VERSION ""

NS_ :

BS_:

BU_: R_BPCU_BCU JiaShiCang L_BPCU_BCU EMPC_ECU

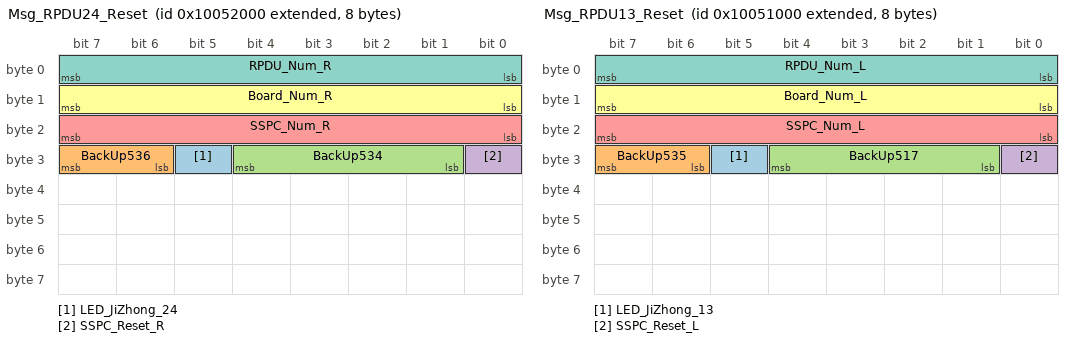
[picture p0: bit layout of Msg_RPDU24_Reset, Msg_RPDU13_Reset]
BO_ 2416254976 Msg_RPDU24_Reset: 8 JiaShiCang
 SG_ LED_JiZhong_24 : 29|1@1+ (1,0) [0|1] "" Vector__XXX
 SG_ BackUp536 : 30|2@1+ (1,0) [0|0] "" Vector__XXX
 SG_ BackUp534 : 25|4@1+ (1,0) [0|0] ""  R_BPCU_BCU
 SG_ SSPC_Reset_R : 24|1@1+ (1,0) [0|1] ""  R_BPCU_BCU
 SG_ SSPC_Num_R : 16|8@1+ (1,0) [1|18] ""  R_BPCU_BCU
 SG_ Board_Num_R : 8|8@1+ (1,0) [1|6] ""  R_BPCU_BCU
 SG_ RPDU_Num_R : 0|8@1+ (1,0) [1|4] ""  R_BPCU_BCU

BO_ 2416189440 Msg_RPDU4_Order2: 8 JiaShiCang
 SG_ BackUp533 : 56|8@1+ (1,0) [0|0] ""  R_BPCU_BCU
 SG_ BackUp532 : 55|1@1+ (1,0) [0|0] ""  R_BPCU_BCU
 SG_ RPDU4_B6_SSPC_Order_07 : 54|1@1+ (1,0) [0|1] ""  R_BPCU_BCU
 SG_ RPDU4_B6_SSPC_Order_06 : 53|1@1+ (1,0) [0|1] ""  R_BPCU_BCU
 SG_ RPDU4_B6_SSPC_Order_05 : 52|1@1+ (1,0) [0|1] ""  R_BPCU_BCU
 SG_ RPDU4_B6_SSPC_Order_04 : 51|1@1+ (1,0) [0|1] ""  R_BPCU_BCU
 SG_ RPDU4_B6_SSPC_Order_03 : 50|1@1+ (1,0) [0|1] ""  R_BPCU_BCU
 SG_ RPDU4_B6_SSPC_Order_02 : 49|1@1+ (1,0) [0|1] ""  R_BPCU_BCU
 SG_ RPDU4_B6_SSPC_Order_01 : 48|1@1+ (1,0) [0|1] ""  R_BPCU_BCU
 SG_ BackUp531 : 42|6@1+ (1,0) [0|0] ""  R_BPCU_BCU
 SG_ RPDU4_B4_SSPC_Order_18 : 41|1@1+ (1,0) [0|1] ""  R_BPCU_BCU
 SG_ RPDU4_B4_SSPC_Order_17 : 40|1@1+ (1,0) [0|1] ""  R_BPCU_BCU
 SG_ RPDU4_B4_SSPC_Order_16 : 39|1@1+ (1,0) [0|1] ""  R_BPCU_BCU
 SG_ RPDU4_B4_SSPC_Order_15 : 38|1@1+ (1,0) [0|1] ""  R_BPCU_BCU
 SG_ RPDU4_B4_SSPC_Order_14 : 37|1@1+ (1,0) [0|1] ""  R_BPCU_BCU
 SG_ RPDU4_B4_SSPC_Order_13 : 36|1@1+ (1,0) [0|1] ""  R_BPCU_BCU
 SG_ RPDU4_B4_SSPC_Order_12 : 35|1@1+ (1,0) [0|1] ""  R_BPCU_BCU
 SG_ RPDU4_B4_SSPC_Order_11 : 34|1@1+ (1,0) [0|1] ""  R_BPCU_BCU
 SG_ RPDU4_B4_SSPC_Order_10 : 33|1@1+ (1,0) [0|1] ""  R_BPCU_BCU
 SG_ RPDU4_B4_SSPC_Order_09 : 32|1@1+ (1,0) [0|1] ""  R_BPCU_BCU
 SG_ RPDU4_B4_SSPC_Order_08 : 31|1@1+ (1,0) [0|1] ""  R_BPCU_BCU
 SG_ RPDU4_B4_SSPC_Order_07 : 30|1@1+ (1,0) [0|1] ""  R_BPCU_BCU
 SG_ RPDU4_B4_SSPC_Order_06 : 29|1@1+ (1,0) [0|1] ""  R_BPCU_BCU
 SG_ RPDU4_B4_SSPC_Order_05 : 28|1@1+ (1,0) [0|1] ""  R_BPCU_BCU
 SG_ RPDU4_B4_SSPC_Order_04 : 27|1@1+ (1,0) [0|1] ""  R_BPCU_BCU
 SG_ RPDU4_B4_SSPC_Order_03 : 26|1@1+ (1,0) [0|1] ""  R_BPCU_BCU
 SG_ RPDU4_B4_SSPC_Order_02 : 25|1@1+ (1,0) [0|1] ""  R_BPCU_BCU
 SG_ RPDU4_B4_SSPC_Order_01 : 24|1@1+ (1,0) [0|1] ""  R_BPCU_BCU
 SG_ BackUp530 : 18|6@1+ (1,0) [0|0] ""  R_BPCU_BCU
 SG_ RPDU4_B2_SSPC_Order_18 : 17|1@1+ (1,0) [0|1] ""  R_BPCU_BCU
 SG_ RPDU4_B2_SSPC_Order_17 : 16|1@1+ (1,0) [0|1] ""  R_BPCU_BCU
 SG_ RPDU4_B2_SSPC_Order_16 : 15|1@1+ (1,0) [0|1] ""  R_BPCU_BCU
 SG_ RPDU4_B2_SSPC_Order_15 : 14|1@1+ (1,0) [0|1] ""  R_BPCU_BCU
 SG_ RPDU4_B2_SSPC_Order_14 : 13|1@1+ (1,0) [0|1] ""  R_BPCU_BCU
 SG_ RPDU4_B2_SSPC_Order_13 : 12|1@1+ (1,0) [0|1] ""  R_BPCU_BCU
 SG_ RPDU4_B2_SSPC_Order_12 : 11|1@1+ (1,0) [0|1] ""  R_BPCU_BCU
 SG_ RPDU4_B2_SSPC_Order_11 : 10|1@1+ (1,0) [0|1] ""  R_BPCU_BCU
 SG_ RPDU4_B2_SSPC_Order_10 : 9|1@1+ (1,0) [0|1] ""  R_BPCU_BCU
 SG_ RPDU4_B2_SSPC_Order_09 : 8|1@1+ (1,0) [0|1] ""  R_BPCU_BCU
 SG_ RPDU4_B2_SSPC_Order_08 : 7|1@1+ (1,0) [0|1] ""  R_BPCU_BCU
 SG_ RPDU4_B2_SSPC_Order_07 : 6|1@1+ (1,0) [0|1] ""  R_BPCU_BCU
 SG_ RPDU4_B2_SSPC_Order_06 : 5|1@1+ (1,0) [0|1] ""  R_BPCU_BCU
 SG_ RPDU4_B2_SSPC_Order_05 : 4|1@1+ (1,0) [0|1] ""  R_BPCU_BCU
 SG_ RPDU4_B2_SSPC_Order_04 : 3|1@1+ (1,0) [0|1] ""  R_BPCU_BCU
 SG_ RPDU4_B2_SSPC_Order_03 : 2|1@1+ (1,0) [0|1] ""  R_BPCU_BCU
 SG_ RPDU4_B2_SSPC_Order_02 : 1|1@1+ (1,0) [0|1] ""  R_BPCU_BCU
 SG_ RPDU4_B2_SSPC_Order_01 : 0|1@1+ (1,0) [0|1] ""  R_BPCU_BCU

BO_ 2416123904 Msg_RPDU4_Order1: 8 JiaShiCang
 SG_ BackUp529 : 56|8@1+ (1,0) [0|0] ""  R_BPCU_BCU
 SG_ BackUp528 : 55|1@1+ (1,0) [0|0] ""  R_BPCU_BCU
 SG_ RPDU4_B5_SSPC_Order_07 : 54|1@1+ (1,0) [0|1] ""  R_BPCU_BCU
 SG_ RPDU4_B5_SSPC_Order_06 : 53|1@1+ (1,0) [0|1] ""  R_BPCU_BCU
 SG_ RPDU4_B5_SSPC_Order_05 : 52|1@1+ (1,0) [0|1] ""  R_BPCU_BCU
 SG_ RPDU4_B5_SSPC_Order_04 : 51|1@1+ (1,0) [0|1] ""  R_BPCU_BCU
 SG_ RPDU4_B5_SSPC_Order_03 : 50|1@1+ (1,0) [0|1] ""  R_BPCU_BCU
 SG_ RPDU4_B5_SSPC_Order_02 : 49|1@1+ (1,0) [0|1] ""  R_BPCU_BCU
 SG_ RPDU4_B5_SSPC_Order_01 : 48|1@1+ (1,0) [0|1] ""  R_BPCU_BCU
 SG_ BackUp527 : 42|6@1+ (1,0) [0|0] ""  R_BPCU_BCU
 SG_ RPDU4_B3_SSPC_Order_18 : 41|1@1+ (1,0) [0|1] ""  R_BPCU_BCU
 SG_ RPDU4_B3_SSPC_Order_17 : 40|1@1+ (1,0) [0|1] ""  R_BPCU_BCU
 SG_ RPDU4_B3_SSPC_Order_16 : 39|1@1+ (1,0) [0|1] ""  R_BPCU_BCU
 SG_ RPDU4_B3_SSPC_Order_15 : 38|1@1+ (1,0) [0|1] ""  R_BPCU_BCU
 SG_ RPDU4_B3_SSPC_Order_14 : 37|1@1+ (1,0) [0|1] ""  R_BPCU_BCU
 SG_ RPDU4_B3_SSPC_Order_13 : 36|1@1+ (1,0) [0|1] ""  R_BPCU_BCU
 SG_ RPDU4_B3_SSPC_Order_12 : 35|1@1+ (1,0) [0|1] ""  R_BPCU_BCU
 SG_ RPDU4_B3_SSPC_Order_11 : 34|1@1+ (1,0) [0|1] ""  R_BPCU_BCU
 SG_ RPDU4_B3_SSPC_Order_10 : 33|1@1+ (1,0) [0|1] ""  R_BPCU_BCU
 SG_ RPDU4_B3_SSPC_Order_09 : 32|1@1+ (1,0) [0|1] ""  R_BPCU_BCU
 SG_ RPDU4_B3_SSPC_Order_08 : 31|1@1+ (1,0) [0|1] ""  R_BPCU_BCU
 SG_ RPDU4_B3_SSPC_Order_07 : 30|1@1+ (1,0) [0|1] ""  R_BPCU_BCU
 SG_ RPDU4_B3_SSPC_Order_06 : 29|1@1+ (1,0) [0|1] ""  R_BPCU_BCU
 SG_ RPDU4_B3_SSPC_Order_05 : 28|1@1+ (1,0) [0|1] ""  R_BPCU_BCU
 SG_ RPDU4_B3_SSPC_Order_04 : 27|1@1+ (1,0) [0|1] ""  R_BPCU_BCU
 SG_ RPDU4_B3_SSPC_Order_03 : 26|1@1+ (1,0) [0|1] ""  R_BPCU_BCU
 SG_ RPDU4_B3_SSPC_Order_02 : 25|1@1+ (1,0) [0|1] ""  R_BPCU_BCU
 SG_ RPDU4_B3_SSPC_Order_01 : 24|1@1+ (1,0) [0|1] ""  R_BPCU_BCU
 SG_ BackUp526 : 18|6@1+ (1,0) [0|0] ""  R_BPCU_BCU
 SG_ RPDU4_B1_SSPC_Order_18 : 17|1@1+ (1,0) [0|1] ""  R_BPCU_BCU
 SG_ RPDU4_B1_SSPC_Order_17 : 16|1@1+ (1,0) [0|1] ""  R_BPCU_BCU
 SG_ RPDU4_B1_SSPC_Order_16 : 15|1@1+ (1,0) [0|1] ""  R_BPCU_BCU
 SG_ RPDU4_B1_SSPC_Order_15 : 14|1@1+ (1,0) [0|1] ""  R_BPCU_BCU
 SG_ RPDU4_B1_SSPC_Order_14 : 13|1@1+ (1,0) [0|1] ""  R_BPCU_BCU
 SG_ RPDU4_B1_SSPC_Order_13 : 12|1@1+ (1,0) [0|1] ""  R_BPCU_BCU
 SG_ RPDU4_B1_SSPC_Order_12 : 11|1@1+ (1,0) [0|1] ""  R_BPCU_BCU
 SG_ RPDU4_B1_SSPC_Order_11 : 10|1@1+ (1,0) [0|1] ""  R_BPCU_BCU
 SG_ RPDU4_B1_SSPC_Order_10 : 9|1@1+ (1,0) [0|1] ""  R_BPCU_BCU
 SG_ RPDU4_B1_SSPC_Order_09 : 8|1@1+ (1,0) [0|1] ""  R_BPCU_BCU
 SG_ RPDU4_B1_SSPC_Order_08 : 7|1@1+ (1,0) [0|1] ""  R_BPCU_BCU
 SG_ RPDU4_B1_SSPC_Order_07 : 6|1@1+ (1,0) [0|1] ""  R_BPCU_BCU
 SG_ RPDU4_B1_SSPC_Order_06 : 5|1@1+ (1,0) [0|1] ""  R_BPCU_BCU
 SG_ RPDU4_B1_SSPC_Order_05 : 4|1@1+ (1,0) [0|1] ""  R_BPCU_BCU
 SG_ RPDU4_B1_SSPC_Order_04 : 3|1@1+ (1,0) [0|1] ""  R_BPCU_BCU
 SG_ RPDU4_B1_SSPC_Order_03 : 2|1@1+ (1,0) [0|1] ""  R_BPCU_BCU
 SG_ RPDU4_B1_SSPC_Order_02 : 1|1@1+ (1,0) [0|1] ""  R_BPCU_BCU
 SG_ RPDU4_B1_SSPC_Order_01 : 0|1@1+ (1,0) [0|1] ""  R_BPCU_BCU

BO_ 2416058368 Msg_RPDU2_Order2: 8 JiaShiCang
 SG_ BackUp525 : 56|8@1+ (1,0) [0|0] ""  R_BPCU_BCU
 SG_ BackUp524 : 55|1@1+ (1,0) [0|0] ""  R_BPCU_BCU
 SG_ RPDU2_B6_SSPC_Order_07 : 54|1@1+ (1,0) [0|1] ""  R_BPCU_BCU
 SG_ RPDU2_B6_SSPC_Order_06 : 53|1@1+ (1,0) [0|1] ""  R_BPCU_BCU
 SG_ RPDU2_B6_SSPC_Order_05 : 52|1@1+ (1,0) [0|1] ""  R_BPCU_BCU
 SG_ RPDU2_B6_SSPC_Order_04 : 51|1@1+ (1,0) [0|1] ""  R_BPCU_BCU
 SG_ RPDU2_B6_SSPC_Order_03 : 50|1@1+ (1,0) [0|1] ""  R_BPCU_BCU
 SG_ RPDU2_B6_SSPC_Order_02 : 49|1@1+ (1,0) [0|1] ""  R_BPCU_BCU
 SG_ RPDU2_B6_SSPC_Order_01 : 48|1@1+ (1,0) [0|1] ""  R_BPCU_BCU
 SG_ BackUp523 : 42|6@1+ (1,0) [0|0] ""  R_BPCU_BCU
 SG_ RPDU2_B4_SSPC_Order_18 : 41|1@1+ (1,0) [0|1] ""  R_BPCU_BCU
 SG_ RPDU2_B4_SSPC_Order_17 : 40|1@1+ (1,0) [0|1] ""  R_BPCU_BCU
 SG_ RPDU2_B4_SSPC_Order_16 : 39|1@1+ (1,0) [0|1] ""  R_BPCU_BCU
 SG_ RPDU2_B4_SSPC_Order_15 : 38|1@1+ (1,0) [0|1] ""  R_BPCU_BCU
 SG_ RPDU2_B4_SSPC_Order_14 : 37|1@1+ (1,0) [0|1] ""  R_BPCU_BCU
 SG_ RPDU2_B4_SSPC_Order_13 : 36|1@1+ (1,0) [0|1] ""  R_BPCU_BCU
 SG_ RPDU2_B4_SSPC_Order_12 : 35|1@1+ (1,0) [0|1] ""  R_BPCU_BCU
 SG_ RPDU2_B4_SSPC_Order_11 : 34|1@1+ (1,0) [0|1] ""  R_BPCU_BCU
 SG_ RPDU2_B4_SSPC_Order_10 : 33|1@1+ (1,0) [0|1] ""  R_BPCU_BCU
 SG_ RPDU2_B4_SSPC_Order_09 : 32|1@1+ (1,0) [0|1] ""  R_BPCU_BCU
 SG_ RPDU2_B4_SSPC_Order_08 : 31|1@1+ (1,0) [0|1] ""  R_BPCU_BCU
 SG_ RPDU2_B4_SSPC_Order_07 : 30|1@1+ (1,0) [0|1] ""  R_BPCU_BCU
 SG_ RPDU2_B4_SSPC_Order_06 : 29|1@1+ (1,0) [0|1] ""  R_BPCU_BCU
 SG_ RPDU2_B4_SSPC_Order_05 : 28|1@1+ (1,0) [0|1] ""  R_BPCU_BCU
 SG_ RPDU2_B4_SSPC_Order_04 : 27|1@1+ (1,0) [0|1] ""  R_BPCU_BCU
 SG_ RPDU2_B4_SSPC_Order_03 : 26|1@1+ (1,0) [0|1] ""  R_BPCU_BCU
 SG_ RPDU2_B4_SSPC_Order_02 : 25|1@1+ (1,0) [0|1] ""  R_BPCU_BCU
 SG_ RPDU2_B4_SSPC_Order_01 : 24|1@1+ (1,0) [0|1] ""  R_BPCU_BCU
 SG_ BackUp522 : 18|6@1+ (1,0) [0|0] ""  R_BPCU_BCU
 SG_ RPDU2_B2_SSPC_Order_18 : 17|1@1+ (1,0) [0|1] ""  R_BPCU_BCU
 SG_ RPDU2_B2_SSPC_Order_17 : 16|1@1+ (1,0) [0|1] ""  R_BPCU_BCU
 SG_ RPDU2_B2_SSPC_Order_16 : 15|1@1+ (1,0) [0|1] ""  R_BPCU_BCU
 SG_ RPDU2_B2_SSPC_Order_15 : 14|1@1+ (1,0) [0|1] ""  R_BPCU_BCU
 SG_ RPDU2_B2_SSPC_Order_14 : 13|1@1+ (1,0) [0|1] ""  R_BPCU_BCU
 SG_ RPDU2_B2_SSPC_Order_13 : 12|1@1+ (1,0) [0|1] ""  R_BPCU_BCU
 SG_ RPDU2_B2_SSPC_Order_12 : 11|1@1+ (1,0) [0|1] ""  R_BPCU_BCU
 SG_ RPDU2_B2_SSPC_Order_11 : 10|1@1+ (1,0) [0|1] ""  R_BPCU_BCU
 SG_ RPDU2_B2_SSPC_Order_10 : 9|1@1+ (1,0) [0|1] ""  R_BPCU_BCU
 SG_ RPDU2_B2_SSPC_Order_09 : 8|1@1+ (1,0) [0|1] ""  R_BPCU_BCU
 SG_ RPDU2_B2_SSPC_Order_08 : 7|1@1+ (1,0) [0|1] ""  R_BPCU_BCU
 SG_ RPDU2_B2_SSPC_Order_07 : 6|1@1+ (1,0) [0|1] ""  R_BPCU_BCU
 SG_ RPDU2_B2_SSPC_Order_06 : 5|1@1+ (1,0) [0|1] ""  R_BPCU_BCU
 SG_ RPDU2_B2_SSPC_Order_05 : 4|1@1+ (1,0) [0|1] ""  R_BPCU_BCU
 SG_ RPDU2_B2_SSPC_Order_04 : 3|1@1+ (1,0) [0|1] ""  R_BPCU_BCU
 SG_ RPDU2_B2_SSPC_Order_03 : 2|1@1+ (1,0) [0|1] ""  R_BPCU_BCU
 SG_ RPDU2_B2_SSPC_Order_02 : 1|1@1+ (1,0) [0|1] ""  R_BPCU_BCU
 SG_ RPDU2_B2_SSPC_Order_01 : 0|1@1+ (1,0) [0|1] ""  R_BPCU_BCU

BO_ 2415992832 Msg_RPDU2_Order1: 8 JiaShiCang
 SG_ BackUp521 : 56|8@1+ (1,0) [0|0] ""  R_BPCU_BCU
 SG_ BackUp520 : 55|1@1+ (1,0) [0|0] ""  R_BPCU_BCU
 SG_ RPDU2_B5_SSPC_Order_07 : 54|1@1+ (1,0) [0|1] ""  R_BPCU_BCU
 SG_ RPDU2_B5_SSPC_Order_06 : 53|1@1+ (1,0) [0|1] ""  R_BPCU_BCU
 SG_ RPDU2_B5_SSPC_Order_05 : 52|1@1+ (1,0) [0|1] ""  R_BPCU_BCU
 SG_ RPDU2_B5_SSPC_Order_04 : 51|1@1+ (1,0) [0|1] ""  R_BPCU_BCU
 SG_ RPDU2_B5_SSPC_Order_03 : 50|1@1+ (1,0) [0|1] ""  R_BPCU_BCU
 SG_ RPDU2_B5_SSPC_Order_02 : 49|1@1+ (1,0) [0|1] ""  R_BPCU_BCU
 SG_ RPDU2_B5_SSPC_Order_01 : 48|1@1+ (1,0) [0|1] ""  R_BPCU_BCU
 SG_ BackUp519 : 42|6@1+ (1,0) [0|0] ""  R_BPCU_BCU
 SG_ RPDU2_B3_SSPC_Order_18 : 41|1@1+ (1,0) [0|1] ""  R_BPCU_BCU
 SG_ RPDU2_B3_SSPC_Order_17 : 40|1@1+ (1,0) [0|1] ""  R_BPCU_BCU
 SG_ RPDU2_B3_SSPC_Order_16 : 39|1@1+ (1,0) [0|1] ""  R_BPCU_BCU
 SG_ RPDU2_B3_SSPC_Order_15 : 38|1@1+ (1,0) [0|1] ""  R_BPCU_BCU
 SG_ RPDU2_B3_SSPC_Order_14 : 37|1@1+ (1,0) [0|1] ""  R_BPCU_BCU
 SG_ RPDU2_B3_SSPC_Order_13 : 36|1@1+ (1,0) [0|1] ""  R_BPCU_BCU
 SG_ RPDU2_B3_SSPC_Order_12 : 35|1@1+ (1,0) [0|1] ""  R_BPCU_BCU
 SG_ RPDU2_B3_SSPC_Order_11 : 34|1@1+ (1,0) [0|1] ""  R_BPCU_BCU
 SG_ RPDU2_B3_SSPC_Order_10 : 33|1@1+ (1,0) [0|1] ""  R_BPCU_BCU
 SG_ RPDU2_B3_SSPC_Order_09 : 32|1@1+ (1,0) [0|1] ""  R_BPCU_BCU
 SG_ RPDU2_B3_SSPC_Order_08 : 31|1@1+ (1,0) [0|1] ""  R_BPCU_BCU
 SG_ RPDU2_B3_SSPC_Order_07 : 30|1@1+ (1,0) [0|1] ""  R_BPCU_BCU
 SG_ RPDU2_B3_SSPC_Order_06 : 29|1@1+ (1,0) [0|1] ""  R_BPCU_BCU
 SG_ RPDU2_B3_SSPC_Order_05 : 28|1@1+ (1,0) [0|1] ""  R_BPCU_BCU
 SG_ RPDU2_B3_SSPC_Order_04 : 27|1@1+ (1,0) [0|1] ""  R_BPCU_BCU
 SG_ RPDU2_B3_SSPC_Order_03 : 26|1@1+ (1,0) [0|1] ""  R_BPCU_BCU
 SG_ RPDU2_B3_SSPC_Order_02 : 25|1@1+ (1,0) [0|1] ""  R_BPCU_BCU
 SG_ RPDU2_B3_SSPC_Order_01 : 24|1@1+ (1,0) [0|1] ""  R_BPCU_BCU
 SG_ BackUp518 : 18|6@1+ (1,0) [0|0] ""  R_BPCU_BCU
 SG_ RPDU2_B1_SSPC_Order_18 : 17|1@1+ (1,0) [0|1] ""  R_BPCU_BCU
 SG_ RPDU2_B1_SSPC_Order_17 : 16|1@1+ (1,0) [0|1] ""  R_BPCU_BCU
 SG_ RPDU2_B1_SSPC_Order_16 : 15|1@1+ (1,0) [0|1] ""  R_BPCU_BCU
 SG_ RPDU2_B1_SSPC_Order_15 : 14|1@1+ (1,0) [0|1] ""  R_BPCU_BCU
 SG_ RPDU2_B1_SSPC_Order_14 : 13|1@1+ (1,0) [0|1] ""  R_BPCU_BCU
 SG_ RPDU2_B1_SSPC_Order_13 : 12|1@1+ (1,0) [0|1] ""  R_BPCU_BCU
 SG_ RPDU2_B1_SSPC_Order_12 : 11|1@1+ (1,0) [0|1] ""  R_BPCU_BCU
 SG_ RPDU2_B1_SSPC_Order_11 : 10|1@1+ (1,0) [0|1] ""  R_BPCU_BCU
 SG_ RPDU2_B1_SSPC_Order_10 : 9|1@1+ (1,0) [0|1] ""  R_BPCU_BCU
 SG_ RPDU2_B1_SSPC_Order_09 : 8|1@1+ (1,0) [0|1] ""  R_BPCU_BCU
 SG_ RPDU2_B1_SSPC_Order_08 : 7|1@1+ (1,0) [0|1] ""  R_BPCU_BCU
 SG_ RPDU2_B1_SSPC_Order_07 : 6|1@1+ (1,0) [0|1] ""  R_BPCU_BCU
 SG_ RPDU2_B1_SSPC_Order_06 : 5|1@1+ (1,0) [0|1] ""  R_BPCU_BCU
 SG_ RPDU2_B1_SSPC_Order_05 : 4|1@1+ (1,0) [0|1] ""  R_BPCU_BCU
 SG_ RPDU2_B1_SSPC_Order_04 : 3|1@1+ (1,0) [0|1] ""  R_BPCU_BCU
 SG_ RPDU2_B1_SSPC_Order_03 : 2|1@1+ (1,0) [0|1] ""  R_BPCU_BCU
 SG_ RPDU2_B1_SSPC_Order_02 : 1|1@1+ (1,0) [0|1] ""  R_BPCU_BCU
 SG_ RPDU2_B1_SSPC_Order_01 : 0|1@1+ (1,0) [0|1] ""  R_BPCU_BCU

BO_ 2416250880 Msg_RPDU13_Reset: 8 JiaShiCang
 SG_ LED_JiZhong_13 : 29|1@1+ (1,0) [0|1] "" Vector__XXX
 SG_ BackUp535 : 30|2@1+ (1,0) [0|0] "" Vector__XXX
 SG_ BackUp517 : 25|4@1+ (1,0) [0|0] ""  L_BPCU_BCU
 SG_ SSPC_Reset_L : 24|1@1+ (1,0) [0|1] ""  L_BPCU_BCU
 SG_ SSPC_Num_L : 16|8@1+ (1,0) [1|18] ""  L_BPCU_BCU
 SG_ Board_Num_L : 8|8@1+ (1,0) [1|6] ""  L_BPCU_BCU
 SG_ RPDU_Num_L : 0|8@1+ (1,0) [1|4] ""  L_BPCU_BCU

BO_ 2416185344 Msg_RPDU3_Order2: 8 JiaShiCang
 SG_ BackUp516 : 56|8@1+ (1,0) [0|0] ""  L_BPCU_BCU
 SG_ BackUp515 : 55|1@1+ (1,0) [0|0] ""  L_BPCU_BCU
 SG_ RPDU3_B6_SSPC_Order_07 : 54|1@1+ (1,0) [0|1] ""  L_BPCU_BCU
 SG_ RPDU3_B6_SSPC_Order_06 : 53|1@1+ (1,0) [0|1] ""  L_BPCU_BCU
 SG_ RPDU3_B6_SSPC_Order_05 : 52|1@1+ (1,0) [0|1] ""  L_BPCU_BCU
 SG_ RPDU3_B6_SSPC_Order_04 : 51|1@1+ (1,0) [0|1] ""  L_BPCU_BCU
 SG_ RPDU3_B6_SSPC_Order_03 : 50|1@1+ (1,0) [0|1] ""  L_BPCU_BCU
 SG_ RPDU3_B6_SSPC_Order_02 : 49|1@1+ (1,0) [0|1] ""  L_BPCU_BCU
 SG_ RPDU3_B6_SSPC_Order_01 : 48|1@1+ (1,0) [0|1] ""  L_BPCU_BCU
 SG_ BackUp514 : 42|6@1+ (1,0) [0|0] ""  L_BPCU_BCU
 SG_ RPDU3_B4_SSPC_Order_18 : 41|1@1+ (1,0) [0|1] ""  L_BPCU_BCU
 SG_ RPDU3_B4_SSPC_Order_17 : 40|1@1+ (1,0) [0|1] ""  L_BPCU_BCU
 SG_ RPDU3_B4_SSPC_Order_16 : 39|1@1+ (1,0) [0|1] ""  L_BPCU_BCU
 SG_ RPDU3_B4_SSPC_Order_15 : 38|1@1+ (1,0) [0|1] ""  L_BPCU_BCU
 SG_ RPDU3_B4_SSPC_Order_14 : 37|1@1+ (1,0) [0|1] ""  L_BPCU_BCU
 SG_ RPDU3_B4_SSPC_Order_13 : 36|1@1+ (1,0) [0|1] ""  L_BPCU_BCU
 SG_ RPDU3_B4_SSPC_Order_12 : 35|1@1+ (1,0) [0|1] ""  L_BPCU_BCU
 SG_ RPDU3_B4_SSPC_Order_11 : 34|1@1+ (1,0) [0|1] ""  L_BPCU_BCU
 SG_ RPDU3_B4_SSPC_Order_10 : 33|1@1+ (1,0) [0|1] ""  L_BPCU_BCU
 SG_ RPDU3_B4_SSPC_Order_09 : 32|1@1+ (1,0) [0|1] ""  L_BPCU_BCU
 SG_ RPDU3_B4_SSPC_Order_08 : 31|1@1+ (1,0) [0|1] ""  L_BPCU_BCU
 SG_ RPDU3_B4_SSPC_Order_07 : 30|1@1+ (1,0) [0|1] ""  L_BPCU_BCU
 SG_ RPDU3_B4_SSPC_Order_06 : 29|1@1+ (1,0) [0|1] ""  L_BPCU_BCU
 SG_ RPDU3_B4_SSPC_Order_05 : 28|1@1+ (1,0) [0|1] ""  L_BPCU_BCU
 SG_ RPDU3_B4_SSPC_Order_04 : 27|1@1+ (1,0) [0|1] ""  L_BPCU_BCU
 SG_ RPDU3_B4_SSPC_Order_03 : 26|1@1+ (1,0) [0|1] ""  L_BPCU_BCU
 SG_ RPDU3_B4_SSPC_Order_02 : 25|1@1+ (1,0) [0|1] ""  L_BPCU_BCU
 SG_ RPDU3_B4_SSPC_Order_01 : 24|1@1+ (1,0) [0|1] ""  L_BPCU_BCU
 SG_ BackUp513 : 18|6@1+ (1,0) [0|0] ""  L_BPCU_BCU
 SG_ RPDU3_B2_SSPC_Order_18 : 17|1@1+ (1,0) [0|1] ""  L_BPCU_BCU
 SG_ RPDU3_B2_SSPC_Order_17 : 16|1@1+ (1,0) [0|1] ""  L_BPCU_BCU
 SG_ RPDU3_B2_SSPC_Order_16 : 15|1@1+ (1,0) [0|1] ""  L_BPCU_BCU
 SG_ RPDU3_B2_SSPC_Order_15 : 14|1@1+ (1,0) [0|1] ""  L_BPCU_BCU
 SG_ RPDU3_B2_SSPC_Order_14 : 13|1@1+ (1,0) [0|1] ""  L_BPCU_BCU
 SG_ RPDU3_B2_SSPC_Order_13 : 12|1@1+ (1,0) [0|1] ""  L_BPCU_BCU
 SG_ RPDU3_B2_SSPC_Order_12 : 11|1@1+ (1,0) [0|1] ""  L_BPCU_BCU
 SG_ RPDU3_B2_SSPC_Order_11 : 10|1@1+ (1,0) [0|1] ""  L_BPCU_BCU
 SG_ RPDU3_B2_SSPC_Order_10 : 9|1@1+ (1,0) [0|1] ""  L_BPCU_BCU
 SG_ RPDU3_B2_SSPC_Order_09 : 8|1@1+ (1,0) [0|1] ""  L_BPCU_BCU
 SG_ RPDU3_B2_SSPC_Order_08 : 7|1@1+ (1,0) [0|1] ""  L_BPCU_BCU
 SG_ RPDU3_B2_SSPC_Order_07 : 6|1@1+ (1,0) [0|1] ""  L_BPCU_BCU
 SG_ RPDU3_B2_SSPC_Order_06 : 5|1@1+ (1,0) [0|1] ""  L_BPCU_BCU
 SG_ RPDU3_B2_SSPC_Order_05 : 4|1@1+ (1,0) [0|1] ""  L_BPCU_BCU
 SG_ RPDU3_B2_SSPC_Order_04 : 3|1@1+ (1,0) [0|1] ""  L_BPCU_BCU
 SG_ RPDU3_B2_SSPC_Order_03 : 2|1@1+ (1,0) [0|1] ""  L_BPCU_BCU
 SG_ RPDU3_B2_SSPC_Order_02 : 1|1@1+ (1,0) [0|1] ""  L_BPCU_BCU
 SG_ RPDU3_B2_SSPC_Order_01 : 0|1@1+ (1,0) [0|1] ""  L_BPCU_BCU

BO_ 2416119808 Msg_RPDU3_Order1: 8 JiaShiCang
 SG_ BackUp512 : 56|8@1+ (1,0) [0|0] ""  L_BPCU_BCU
 SG_ BackUp511 : 55|1@1+ (1,0) [0|0] ""  L_BPCU_BCU
 SG_ RPDU3_B5_SSPC_Order_07 : 54|1@1+ (1,0) [0|1] ""  L_BPCU_BCU
 SG_ RPDU3_B5_SSPC_Order_06 : 53|1@1+ (1,0) [0|1] ""  L_BPCU_BCU
 SG_ RPDU3_B5_SSPC_Order_05 : 52|1@1+ (1,0) [0|1] ""  L_BPCU_BCU
 SG_ RPDU3_B5_SSPC_Order_04 : 51|1@1+ (1,0) [0|1] ""  L_BPCU_BCU
 SG_ RPDU3_B5_SSPC_Order_03 : 50|1@1+ (1,0) [0|1] ""  L_BPCU_BCU
 SG_ RPDU3_B5_SSPC_Order_02 : 49|1@1+ (1,0) [0|1] ""  L_BPCU_BCU
 SG_ RPDU3_B5_SSPC_Order_01 : 48|1@1+ (1,0) [0|1] ""  L_BPCU_BCU
 SG_ BackUp510 : 42|6@1+ (1,0) [0|0] ""  L_BPCU_BCU
 SG_ RPDU3_B3_SSPC_Order_18 : 41|1@1+ (1,0) [0|1] ""  L_BPCU_BCU
 SG_ RPDU3_B3_SSPC_Order_17 : 40|1@1+ (1,0) [0|1] ""  L_BPCU_BCU
 SG_ RPDU3_B3_SSPC_Order_16 : 39|1@1+ (1,0) [0|1] ""  L_BPCU_BCU
 SG_ RPDU3_B3_SSPC_Order_15 : 38|1@1+ (1,0) [0|1] ""  L_BPCU_BCU
 SG_ RPDU3_B3_SSPC_Order_14 : 37|1@1+ (1,0) [0|1] ""  L_BPCU_BCU
 SG_ RPDU3_B3_SSPC_Order_13 : 36|1@1+ (1,0) [0|1] ""  L_BPCU_BCU
 SG_ RPDU3_B3_SSPC_Order_12 : 35|1@1+ (1,0) [0|1] ""  L_BPCU_BCU
 SG_ RPDU3_B3_SSPC_Order_11 : 34|1@1+ (1,0) [0|1] ""  L_BPCU_BCU
 SG_ RPDU3_B3_SSPC_Order_10 : 33|1@1+ (1,0) [0|1] ""  L_BPCU_BCU
 SG_ RPDU3_B3_SSPC_Order_09 : 32|1@1+ (1,0) [0|1] ""  L_BPCU_BCU
 SG_ RPDU3_B3_SSPC_Order_08 : 31|1@1+ (1,0) [0|1] ""  L_BPCU_BCU
 SG_ RPDU3_B3_SSPC_Order_07 : 30|1@1+ (1,0) [0|1] ""  L_BPCU_BCU
 SG_ RPDU3_B3_SSPC_Order_06 : 29|1@1+ (1,0) [0|1] ""  L_BPCU_BCU
 SG_ RPDU3_B3_SSPC_Order_05 : 28|1@1+ (1,0) [0|1] ""  L_BPCU_BCU
 SG_ RPDU3_B3_SSPC_Order_04 : 27|1@1+ (1,0) [0|1] ""  L_BPCU_BCU
 SG_ RPDU3_B3_SSPC_Order_03 : 26|1@1+ (1,0) [0|1] ""  L_BPCU_BCU
 SG_ RPDU3_B3_SSPC_Order_02 : 25|1@1+ (1,0) [0|1] ""  L_BPCU_BCU
 SG_ RPDU3_B3_SSPC_Order_01 : 24|1@1+ (1,0) [0|1] ""  L_BPCU_BCU
 SG_ BackUp509 : 18|6@1+ (1,0) [0|0] ""  L_BPCU_BCU
 SG_ RPDU3_B1_SSPC_Order_18 : 17|1@1+ (1,0) [0|1] ""  L_BPCU_BCU
 SG_ RPDU3_B1_SSPC_Order_17 : 16|1@1+ (1,0) [0|1] ""  L_BPCU_BCU
 SG_ RPDU3_B1_SSPC_Order_16 : 15|1@1+ (1,0) [0|1] ""  L_BPCU_BCU
 SG_ RPDU3_B1_SSPC_Order_15 : 14|1@1+ (1,0) [0|1] ""  L_BPCU_BCU
 SG_ RPDU3_B1_SSPC_Order_14 : 13|1@1+ (1,0) [0|1] ""  L_BPCU_BCU
 SG_ RPDU3_B1_SSPC_Order_13 : 12|1@1+ (1,0) [0|1] ""  L_BPCU_BCU
 SG_ RPDU3_B1_SSPC_Order_12 : 11|1@1+ (1,0) [0|1] ""  L_BPCU_BCU
 SG_ RPDU3_B1_SSPC_Order_11 : 10|1@1+ (1,0) [0|1] ""  L_BPCU_BCU
 SG_ RPDU3_B1_SSPC_Order_10 : 9|1@1+ (1,0) [0|1] ""  L_BPCU_BCU
 SG_ RPDU3_B1_SSPC_Order_09 : 8|1@1+ (1,0) [0|1] ""  L_BPCU_BCU
 SG_ RPDU3_B1_SSPC_Order_08 : 7|1@1+ (1,0) [0|1] ""  L_BPCU_BCU
 SG_ RPDU3_B1_SSPC_Order_07 : 6|1@1+ (1,0) [0|1] ""  L_BPCU_BCU
 SG_ RPDU3_B1_SSPC_Order_06 : 5|1@1+ (1,0) [0|1] ""  L_BPCU_BCU
 SG_ RPDU3_B1_SSPC_Order_05 : 4|1@1+ (1,0) [0|1] ""  L_BPCU_BCU
 SG_ RPDU3_B1_SSPC_Order_04 : 3|1@1+ (1,0) [0|1] ""  L_BPCU_BCU
 SG_ RPDU3_B1_SSPC_Order_03 : 2|1@1+ (1,0) [0|1] ""  L_BPCU_BCU
 SG_ RPDU3_B1_SSPC_Order_02 : 1|1@1+ (1,0) [0|1] ""  L_BPCU_BCU
 SG_ RPDU3_B1_SSPC_Order_01 : 0|1@1+ (1,0) [0|1] ""  L_BPCU_BCU

BO_ 2416054272 Msg_RPDU1_Order2: 8 JiaShiCang
 SG_ BackUp508 : 56|8@1+ (1,0) [0|0] ""  L_BPCU_BCU
 SG_ BackUp507 : 55|1@1+ (1,0) [0|0] ""  L_BPCU_BCU
 SG_ RPDU1_B6_SSPC_Order_07 : 54|1@1+ (1,0) [0|1] ""  L_BPCU_BCU
 SG_ RPDU1_B6_SSPC_Order_06 : 53|1@1+ (1,0) [0|1] ""  L_BPCU_BCU
 SG_ RPDU1_B6_SSPC_Order_05 : 52|1@1+ (1,0) [0|1] ""  L_BPCU_BCU
 SG_ RPDU1_B6_SSPC_Order_04 : 51|1@1+ (1,0) [0|1] ""  L_BPCU_BCU
 SG_ RPDU1_B6_SSPC_Order_03 : 50|1@1+ (1,0) [0|1] ""  L_BPCU_BCU
 SG_ RPDU1_B6_SSPC_Order_02 : 49|1@1+ (1,0) [0|1] ""  L_BPCU_BCU
 SG_ RPDU1_B6_SSPC_Order_01 : 48|1@1+ (1,0) [0|1] ""  L_BPCU_BCU
 SG_ BackUp506 : 42|6@1+ (1,0) [0|0] ""  L_BPCU_BCU
 SG_ RPDU1_B4_SSPC_Order_18 : 41|1@1+ (1,0) [0|1] ""  L_BPCU_BCU
 SG_ RPDU1_B4_SSPC_Order_17 : 40|1@1+ (1,0) [0|1] ""  L_BPCU_BCU
 SG_ RPDU1_B4_SSPC_Order_16 : 39|1@1+ (1,0) [0|1] ""  L_BPCU_BCU
 SG_ RPDU1_B4_SSPC_Order_15 : 38|1@1+ (1,0) [0|1] ""  L_BPCU_BCU
 SG_ RPDU1_B4_SSPC_Order_14 : 37|1@1+ (1,0) [0|1] ""  L_BPCU_BCU
 SG_ RPDU1_B4_SSPC_Order_13 : 36|1@1+ (1,0) [0|1] ""  L_BPCU_BCU
 SG_ RPDU1_B4_SSPC_Order_12 : 35|1@1+ (1,0) [0|1] ""  L_BPCU_BCU
 SG_ RPDU1_B4_SSPC_Order_11 : 34|1@1+ (1,0) [0|1] ""  L_BPCU_BCU
 SG_ RPDU1_B4_SSPC_Order_10 : 33|1@1+ (1,0) [0|1] ""  L_BPCU_BCU
 SG_ RPDU1_B4_SSPC_Order_09 : 32|1@1+ (1,0) [0|1] ""  L_BPCU_BCU
 SG_ RPDU1_B4_SSPC_Order_08 : 31|1@1+ (1,0) [0|1] ""  L_BPCU_BCU
 SG_ RPDU1_B4_SSPC_Order_07 : 30|1@1+ (1,0) [0|1] ""  L_BPCU_BCU
 SG_ RPDU1_B4_SSPC_Order_06 : 29|1@1+ (1,0) [0|1] ""  L_BPCU_BCU
 SG_ RPDU1_B4_SSPC_Order_05 : 28|1@1+ (1,0) [0|1] ""  L_BPCU_BCU
 SG_ RPDU1_B4_SSPC_Order_04 : 27|1@1+ (1,0) [0|1] ""  L_BPCU_BCU
 SG_ RPDU1_B4_SSPC_Order_03 : 26|1@1+ (1,0) [0|1] ""  L_BPCU_BCU
 SG_ RPDU1_B4_SSPC_Order_02 : 25|1@1+ (1,0) [0|1] ""  L_BPCU_BCU
 SG_ RPDU1_B4_SSPC_Order_01 : 24|1@1+ (1,0) [0|1] ""  L_BPCU_BCU
 SG_ BackUp505 : 18|6@1+ (1,0) [0|0] ""  L_BPCU_BCU
 SG_ RPDU1_B2_SSPC_Order_18 : 17|1@1+ (1,0) [0|1] ""  L_BPCU_BCU
 SG_ RPDU1_B2_SSPC_Order_17 : 16|1@1+ (1,0) [0|1] ""  L_BPCU_BCU
 SG_ RPDU1_B2_SSPC_Order_16 : 15|1@1+ (1,0) [0|1] ""  L_BPCU_BCU
 SG_ RPDU1_B2_SSPC_Order_15 : 14|1@1+ (1,0) [0|1] ""  L_BPCU_BCU
 SG_ RPDU1_B2_SSPC_Order_14 : 13|1@1+ (1,0) [0|1] ""  L_BPCU_BCU
 SG_ RPDU1_B2_SSPC_Order_13 : 12|1@1+ (1,0) [0|1] ""  L_BPCU_BCU
 SG_ RPDU1_B2_SSPC_Order_12 : 11|1@1+ (1,0) [0|1] ""  L_BPCU_BCU
 SG_ RPDU1_B2_SSPC_Order_11 : 10|1@1+ (1,0) [0|1] ""  L_BPCU_BCU
 SG_ RPDU1_B2_SSPC_Order_10 : 9|1@1+ (1,0) [0|1] ""  L_BPCU_BCU
 SG_ RPDU1_B2_SSPC_Order_09 : 8|1@1+ (1,0) [0|1] ""  L_BPCU_BCU
 SG_ RPDU1_B2_SSPC_Order_08 : 7|1@1+ (1,0) [0|1] ""  L_BPCU_BCU
 SG_ RPDU1_B2_SSPC_Order_07 : 6|1@1+ (1,0) [0|1] ""  L_BPCU_BCU
 SG_ RPDU1_B2_SSPC_Order_06 : 5|1@1+ (1,0) [0|1] ""  L_BPCU_BCU
 SG_ RPDU1_B2_SSPC_Order_05 : 4|1@1+ (1,0) [0|1] ""  L_BPCU_BCU
 SG_ RPDU1_B2_SSPC_Order_04 : 3|1@1+ (1,0) [0|1] ""  L_BPCU_BCU
 SG_ RPDU1_B2_SSPC_Order_03 : 2|1@1+ (1,0) [0|1] ""  L_BPCU_BCU
 SG_ RPDU1_B2_SSPC_Order_02 : 1|1@1+ (1,0) [0|1] ""  L_BPCU_BCU
 SG_ RPDU1_B2_SSPC_Order_01 : 0|1@1+ (1,0) [0|1] ""  L_BPCU_BCU

BO_ 2415988736 Msg_RPDU1_Order1: 8 JiaShiCang
 SG_ BackUp504 : 56|8@1+ (1,0) [0|0] ""  L_BPCU_BCU
 SG_ BackUp503 : 55|1@1+ (1,0) [0|0] ""  L_BPCU_BCU
 SG_ RPDU1_B5_SSPC_Order_07 : 54|1@1+ (1,0) [0|1] ""  L_BPCU_BCU
 SG_ RPDU1_B5_SSPC_Order_06 : 53|1@1+ (1,0) [0|1] ""  L_BPCU_BCU
 SG_ RPDU1_B5_SSPC_Order_05 : 52|1@1+ (1,0) [0|1] ""  L_BPCU_BCU
 SG_ RPDU1_B5_SSPC_Order_04 : 51|1@1+ (1,0) [0|1] ""  L_BPCU_BCU
 SG_ RPDU1_B5_SSPC_Order_03 : 50|1@1+ (1,0) [0|1] ""  L_BPCU_BCU
 SG_ RPDU1_B5_SSPC_Order_02 : 49|1@1+ (1,0) [0|1] ""  L_BPCU_BCU
 SG_ RPDU1_B5_SSPC_Order_01 : 48|1@1+ (1,0) [0|1] ""  L_BPCU_BCU
 SG_ BackUp502 : 42|6@1+ (1,0) [0|0] ""  L_BPCU_BCU
 SG_ RPDU1_B3_SSPC_Order_18 : 41|1@1+ (1,0) [0|1] ""  L_BPCU_BCU
 SG_ RPDU1_B3_SSPC_Order_17 : 40|1@1+ (1,0) [0|1] ""  L_BPCU_BCU
 SG_ RPDU1_B3_SSPC_Order_16 : 39|1@1+ (1,0) [0|1] ""  L_BPCU_BCU
 SG_ RPDU1_B3_SSPC_Order_15 : 38|1@1+ (1,0) [0|1] ""  L_BPCU_BCU
 SG_ RPDU1_B3_SSPC_Order_14 : 37|1@1+ (1,0) [0|1] ""  L_BPCU_BCU
 SG_ RPDU1_B3_SSPC_Order_13 : 36|1@1+ (1,0) [0|1] ""  L_BPCU_BCU
 SG_ RPDU1_B3_SSPC_Order_12 : 35|1@1+ (1,0) [0|1] ""  L_BPCU_BCU
 SG_ RPDU1_B3_SSPC_Order_11 : 34|1@1+ (1,0) [0|1] ""  L_BPCU_BCU
 SG_ RPDU1_B3_SSPC_Order_10 : 33|1@1+ (1,0) [0|1] ""  L_BPCU_BCU
 SG_ RPDU1_B3_SSPC_Order_09 : 32|1@1+ (1,0) [0|1] ""  L_BPCU_BCU
 SG_ RPDU1_B3_SSPC_Order_08 : 31|1@1+ (1,0) [0|1] ""  L_BPCU_BCU
 SG_ RPDU1_B3_SSPC_Order_07 : 30|1@1+ (1,0) [0|1] ""  L_BPCU_BCU
 SG_ RPDU1_B3_SSPC_Order_06 : 29|1@1+ (1,0) [0|1] ""  L_BPCU_BCU
 SG_ RPDU1_B3_SSPC_Order_05 : 28|1@1+ (1,0) [0|1] ""  L_BPCU_BCU
 SG_ RPDU1_B3_SSPC_Order_04 : 27|1@1+ (1,0) [0|1] ""  L_BPCU_BCU
 SG_ RPDU1_B3_SSPC_Order_03 : 26|1@1+ (1,0) [0|1] ""  L_BPCU_BCU
 SG_ RPDU1_B3_SSPC_Order_02 : 25|1@1+ (1,0) [0|1] ""  L_BPCU_BCU
 SG_ RPDU1_B3_SSPC_Order_01 : 24|1@1+ (1,0) [0|1] ""  L_BPCU_BCU
 SG_ BackUp501 : 18|6@1+ (1,0) [0|0] ""  L_BPCU_BCU
 SG_ RPDU1_B1_SSPC_Order_18 : 17|1@1+ (1,0) [0|1] ""  L_BPCU_BCU
 SG_ RPDU1_B1_SSPC_Order_17 : 16|1@1+ (1,0) [0|1] ""  L_BPCU_BCU
 SG_ RPDU1_B1_SSPC_Order_16 : 15|1@1+ (1,0) [0|1] ""  L_BPCU_BCU
 SG_ RPDU1_B1_SSPC_Order_15 : 14|1@1+ (1,0) [0|1] ""  L_BPCU_BCU
 SG_ RPDU1_B1_SSPC_Order_14 : 13|1@1+ (1,0) [0|1] ""  L_BPCU_BCU
 SG_ RPDU1_B1_SSPC_Order_13 : 12|1@1+ (1,0) [0|1] ""  L_BPCU_BCU
 SG_ RPDU1_B1_SSPC_Order_12 : 11|1@1+ (1,0) [0|1] ""  L_BPCU_BCU
 SG_ RPDU1_B1_SSPC_Order_11 : 10|1@1+ (1,0) [0|1] ""  L_BPCU_BCU
 SG_ RPDU1_B1_SSPC_Order_10 : 9|1@1+ (1,0) [0|1] ""  L_BPCU_BCU
 SG_ RPDU1_B1_SSPC_Order_09 : 8|1@1+ (1,0) [0|1] ""  L_BPCU_BCU
 SG_ RPDU1_B1_SSPC_Order_08 : 7|1@1+ (1,0) [0|1] ""  L_BPCU_BCU
 SG_ RPDU1_B1_SSPC_Order_07 : 6|1@1+ (1,0) [0|1] ""  L_BPCU_BCU
 SG_ RPDU1_B1_SSPC_Order_06 : 5|1@1+ (1,0) [0|1] ""  L_BPCU_BCU
 SG_ RPDU1_B1_SSPC_Order_05 : 4|1@1+ (1,0) [0|1] ""  L_BPCU_BCU
 SG_ RPDU1_B1_SSPC_Order_04 : 3|1@1+ (1,0) [0|1] ""  L_BPCU_BCU
 SG_ RPDU1_B1_SSPC_Order_03 : 2|1@1+ (1,0) [0|1] ""  L_BPCU_BCU
 SG_ RPDU1_B1_SSPC_Order_02 : 1|1@1+ (1,0) [0|1] ""  L_BPCU_BCU
 SG_ RPDU1_B1_SSPC_Order_01 : 0|1@1+ (1,0) [0|1] ""  L_BPCU_BCU

BO_ 2421178416 Msg_E_ChongGou_JiaoHu: 8 EMPC_ECU
 SG_ BackUp500 : 56|8@1+ (1,0) [0|0] ""  R_BPCU_BCU,L_BPCU_BCU
 SG_ BackUp499 : 48|8@1+ (1,0) [0|0] ""  R_BPCU_BCU,L_BPCU_BCU
 SG_ E_E270_HLT_U : 32|16@1+ (0.1,0) [0|6553.5] "V"  R_BPCU_BCU,L_BPCU_BCU
 SG_ BackUp498 : 24|8@1+ (1,0) [0|0] ""  R_BPCU_BCU,L_BPCU_BCU
 SG_ BackUp497 : 23|1@1+ (1,0) [0|0] ""  R_BPCU_BCU,L_BPCU_BCU
 SG_ BackUp496 : 22|1@1+ (1,0) [0|0] ""  R_BPCU_BCU,L_BPCU_BCU
 SG_ BackUp495 : 20|2@1+ (1,0) [0|0] ""  R_BPCU_BCU,L_BPCU_BCU
 SG_ BackUp494 : 18|2@1+ (1,0) [0|0] ""  R_BPCU_BCU,L_BPCU_BCU
 SG_ BackUp493 : 16|2@1+ (1,0) [0|0] ""  R_BPCU_BCU,L_BPCU_BCU
 SG_ BackUp492 : 14|2@1+ (1,0) [0|0] ""  R_BPCU_BCU,L_BPCU_BCU
 SG_ EPC_Ctrl : 13|1@1+ (1,0) [0|1] ""  R_BPCU_BCU,L_BPCU_BCU
 SG_ BackUp491 : 12|1@1+ (1,0) [0|0] ""  R_BPCU_BCU,L_BPCU_BCU
 SG_ CPC_A_STA_ChongGou : 11|1@1+ (1,0) [0|1] ""  R_BPCU_BCU,L_BPCU_BCU
 SG_ BackUp490 : 10|1@1+ (1,0) [0|0] ""  R_BPCU_BCU,L_BPCU_BCU
 SG_ BackUp489 : 9|1@1+ (1,0) [0|0] ""  R_BPCU_BCU,L_BPCU_BCU
 SG_ EDC1_Ctrl : 8|1@1+ (1,0) [0|1] ""  R_BPCU_BCU,L_BPCU_BCU
 SG_ BackUp488 : 6|2@1+ (1,0) [0|0] ""  R_BPCU_BCU,L_BPCU_BCU
 SG_ BackUp487 : 4|2@1+ (1,0) [0|0] ""  R_BPCU_BCU,L_BPCU_BCU
 SG_ BackUp486 : 3|1@1+ (1,0) [0|0] ""  R_BPCU_BCU,L_BPCU_BCU
 SG_ BackUp485 : 2|1@1+ (1,0) [0|0] ""  R_BPCU_BCU,L_BPCU_BCU
 SG_ E_HLT28IOver_ChongGou : 1|1@1+ (1,0) [0|1] ""  R_BPCU_BCU,L_BPCU_BCU
 SG_ E_HLT270IOver_ChongGou : 0|1@1+ (1,0) [0|1] ""  R_BPCU_BCU,L_BPCU_BCU

BO_ 2416181296 Msg_E_DuanLuQi_State: 6 EMPC_ECU
 SG_ E_DuanLuQi_Sta_48 : 47|1@1+ (1,0) [0|1] ""  JiaShiCang
 SG_ E_DuanLuQi_Sta_47 : 46|1@1+ (1,0) [0|1] ""  JiaShiCang
 SG_ E_DuanLuQi_Sta_46 : 45|1@1+ (1,0) [0|1] ""  JiaShiCang
 SG_ E_DuanLuQi_Sta_45 : 44|1@1+ (1,0) [0|1] ""  JiaShiCang
 SG_ E_DuanLuQi_Sta_44 : 43|1@1+ (1,0) [0|1] ""  JiaShiCang
 SG_ E_DuanLuQi_Sta_43 : 42|1@1+ (1,0) [0|1] ""  JiaShiCang
 SG_ E_DuanLuQi_Sta_42 : 41|1@1+ (1,0) [0|1] ""  JiaShiCang
 SG_ E_DuanLuQi_Sta_41 : 40|1@1+ (1,0) [0|1] ""  JiaShiCang
 SG_ E_DuanLuQi_Sta_40 : 39|1@1+ (1,0) [0|1] ""  JiaShiCang
 SG_ E_DuanLuQi_Sta_39 : 38|1@1+ (1,0) [0|1] ""  JiaShiCang
 SG_ E_DuanLuQi_Sta_38 : 37|1@1+ (1,0) [0|1] ""  JiaShiCang
 SG_ E_DuanLuQi_Sta_37 : 36|1@1+ (1,0) [0|1] ""  JiaShiCang
 SG_ E_DuanLuQi_Sta_36 : 35|1@1+ (1,0) [0|1] ""  JiaShiCang
 SG_ E_DuanLuQi_Sta_35 : 34|1@1+ (1,0) [0|1] ""  JiaShiCang
 SG_ E_DuanLuQi_Sta_34 : 33|1@1+ (1,0) [0|1] ""  JiaShiCang
 SG_ E_DuanLuQi_Sta_33 : 32|1@1+ (1,0) [0|1] ""  JiaShiCang
 SG_ E_DuanLuQi_Sta_32 : 31|1@1+ (1,0) [0|1] ""  JiaShiCang
 SG_ E_DuanLuQi_Sta_31 : 30|1@1+ (1,0) [0|1] ""  JiaShiCang
 SG_ E_DuanLuQi_Sta_30 : 29|1@1+ (1,0) [0|1] ""  JiaShiCang
 SG_ E_DuanLuQi_Sta_29 : 28|1@1+ (1,0) [0|1] ""  JiaShiCang
 SG_ E_DuanLuQi_Sta_28 : 27|1@1+ (1,0) [0|1] ""  JiaShiCang
 SG_ E_DuanLuQi_Sta_27 : 26|1@1+ (1,0) [0|1] ""  JiaShiCang
 SG_ E_DuanLuQi_Sta_26 : 25|1@1+ (1,0) [0|1] ""  JiaShiCang
 SG_ E_DuanLuQi_Sta_25 : 24|1@1+ (1,0) [0|1] ""  JiaShiCang
 SG_ E_DuanLuQi_Sta_24 : 23|1@1+ (1,0) [0|1] ""  JiaShiCang
 SG_ E_DuanLuQi_Sta_23 : 22|1@1+ (1,0) [0|1] ""  JiaShiCang
 SG_ E_DuanLuQi_Sta_22 : 21|1@1+ (1,0) [0|1] ""  JiaShiCang
 SG_ E_DuanLuQi_Sta_21 : 20|1@1+ (1,0) [0|1] ""  JiaShiCang
 SG_ E_DuanLuQi_Sta_20 : 19|1@1+ (1,0) [0|1] ""  JiaShiCang
 SG_ E_DuanLuQi_Sta_19 : 18|1@1+ (1,0) [0|1] ""  JiaShiCang
 SG_ E_DuanLuQi_Sta_18 : 17|1@1+ (1,0) [0|1] ""  JiaShiCang
 SG_ E_DuanLuQi_Sta_17 : 16|1@1+ (1,0) [0|1] ""  JiaShiCang
 SG_ E_DuanLuQi_Sta_16 : 15|1@1+ (1,0) [0|1] ""  JiaShiCang
 SG_ E_DuanLuQi_Sta_15 : 14|1@1+ (1,0) [0|1] ""  JiaShiCang
 SG_ E_DuanLuQi_Sta_14 : 13|1@1+ (1,0) [0|1] ""  JiaShiCang
 SG_ E_DuanLuQi_Sta_13 : 12|1@1+ (1,0) [0|1] ""  JiaShiCang
 SG_ E_DuanLuQi_Sta_12 : 11|1@1+ (1,0) [0|1] ""  JiaShiCang
 SG_ E_DuanLuQi_Sta_11 : 10|1@1+ (1,0) [0|1] ""  JiaShiCang
 SG_ E_DuanLuQi_Sta_10 : 9|1@1+ (1,0) [0|1] ""  JiaShiCang
 SG_ E_DuanLuQi_Sta_09 : 8|1@1+ (1,0) [0|1] ""  JiaShiCang
 SG_ E_DuanLuQi_Sta_08 : 7|1@1+ (1,0) [0|1] ""  JiaShiCang
 SG_ E_DuanLuQi_Sta_07 : 6|1@1+ (1,0) [0|1] ""  JiaShiCang
 SG_ E_DuanLuQi_Sta_06 : 5|1@1+ (1,0) [0|1] ""  JiaShiCang
 SG_ E_DuanLuQi_Sta_05 : 4|1@1+ (1,0) [0|1] ""  JiaShiCang
 SG_ E_DuanLuQi_Sta_04 : 3|1@1+ (1,0) [0|1] ""  JiaShiCang
 SG_ E_DuanLuQi_Sta_03 : 2|1@1+ (1,0) [0|1] ""  JiaShiCang
 SG_ E_DuanLuQi_Sta_02 : 1|1@1+ (1,0) [0|1] ""  JiaShiCang
 SG_ E_DuanLuQi_Sta_01 : 0|1@1+ (1,0) [0|1] ""  JiaShiCang

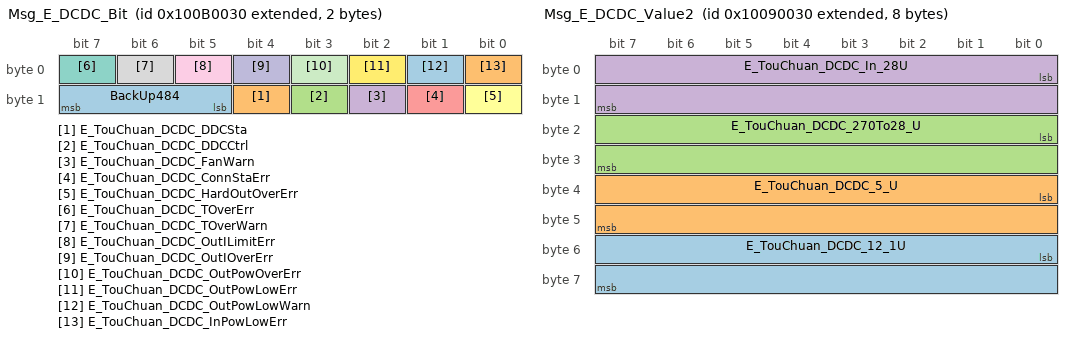
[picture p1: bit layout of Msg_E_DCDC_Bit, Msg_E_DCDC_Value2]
BO_ 2416640048 Msg_E_DCDC_Bit: 2 EMPC_ECU
 SG_ BackUp484 : 13|3@1+ (1,0) [0|0] ""  JiaShiCang
 SG_ E_TouChuan_DCDC_DDCSta : 12|1@1+ (1,0) [0|1] ""  JiaShiCang
 SG_ E_TouChuan_DCDC_DDCCtrl : 11|1@1+ (1,0) [0|1] ""  JiaShiCang
 SG_ E_TouChuan_DCDC_FanWarn : 10|1@1+ (1,0) [0|1] ""  JiaShiCang
 SG_ E_TouChuan_DCDC_ConnStaErr : 9|1@1+ (1,0) [0|1] ""  JiaShiCang
 SG_ E_TouChuan_DCDC_HardOutOverErr : 8|1@1+ (1,0) [0|1] ""  JiaShiCang
 SG_ E_TouChuan_DCDC_TOverErr : 7|1@1+ (1,0) [0|1] ""  JiaShiCang
 SG_ E_TouChuan_DCDC_TOverWarn : 6|1@1+ (1,0) [0|1] ""  JiaShiCang
 SG_ E_TouChuan_DCDC_OutILimitErr : 5|1@1+ (1,0) [0|1] ""  JiaShiCang
 SG_ E_TouChuan_DCDC_OutIOverErr : 4|1@1+ (1,0) [0|1] ""  JiaShiCang
 SG_ E_TouChuan_DCDC_OutPowOverErr : 3|1@1+ (1,0) [0|1] ""  JiaShiCang
 SG_ E_TouChuan_DCDC_OutPowLowErr : 2|1@1+ (1,0) [0|1] ""  JiaShiCang
 SG_ E_TouChuan_DCDC_OutPowLowWarn : 1|1@1+ (1,0) [0|1] ""  JiaShiCang
 SG_ E_TouChuan_DCDC_InPowLowErr : 0|1@1+ (1,0) [0|1] ""  JiaShiCang

BO_ 2416574512 Msg_E_DCDC_Value3: 8 EMPC_ECU
 SG_ BackUp481 : 16|16@1+ (1,0) [0|0] ""  JiaShiCang
 SG_ E_TouChuan_DCDC_12_2U : 0|16@1+ (0.1,0) [0|6553.5] "V"  JiaShiCang

BO_ 2416508976 Msg_E_DCDC_Value2: 8 EMPC_ECU
 SG_ E_TouChuan_DCDC_12_1U : 48|16@1+ (0.1,0) [0|6553.5] "V"  JiaShiCang
 SG_ E_TouChuan_DCDC_5_U : 32|16@1+ (0.1,0) [0|6553.5] "V"  JiaShiCang
 SG_ E_TouChuan_DCDC_270To28_U : 16|16@1+ (0.1,0) [0|6553.5] "V"  JiaShiCang
 SG_ E_TouChuan_DCDC_In_28U : 0|16@1+ (0.1,0) [0|6553.5] "V"  JiaShiCang

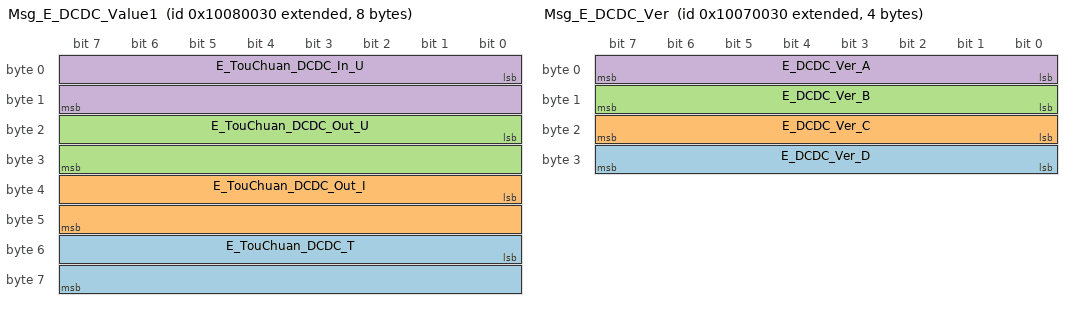
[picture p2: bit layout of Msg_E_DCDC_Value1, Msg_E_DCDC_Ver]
BO_ 2416443440 Msg_E_DCDC_Value1: 8 EMPC_ECU
 SG_ E_TouChuan_DCDC_T : 48|16@1+ (1,-55) [-55|65480] ""  JiaShiCang
 SG_ E_TouChuan_DCDC_Out_I : 32|16@1+ (0.1,0) [0|6553.5] "A"  JiaShiCang
 SG_ E_TouChuan_DCDC_Out_U : 16|16@1+ (0.1,0) [0|6553.5] "V"  JiaShiCang
 SG_ E_TouChuan_DCDC_In_U : 0|16@1+ (0.1,0) [0|6553.5] "V"  JiaShiCang

BO_ 2416377904 Msg_E_DCDC_Ver: 4 EMPC_ECU
 SG_ E_DCDC_Ver_D : 24|8@1+ (1,0) [0|153] ""  JiaShiCang
 SG_ E_DCDC_Ver_C : 16|8@1+ (1,0) [0|153] ""  JiaShiCang
 SG_ E_DCDC_Ver_B : 8|8@1+ (1,0) [0|153] ""  JiaShiCang
 SG_ E_DCDC_Ver_A : 0|8@1+ (1,0) [0|153] ""  JiaShiCang

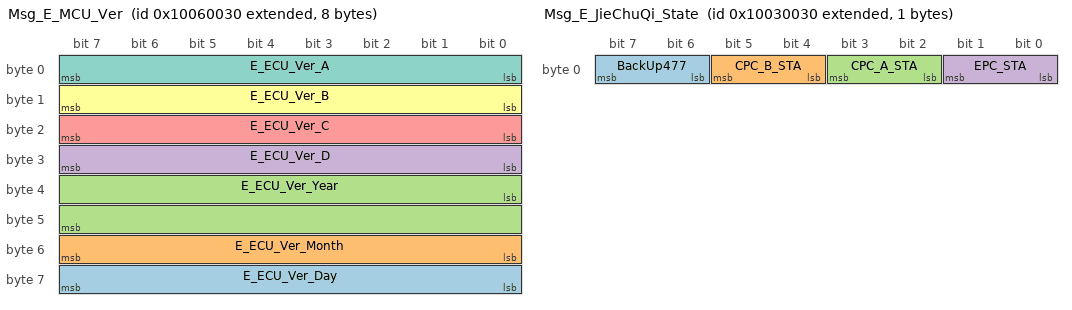
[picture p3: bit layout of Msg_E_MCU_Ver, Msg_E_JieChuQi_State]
BO_ 2416312368 Msg_E_MCU_Ver: 8 EMPC_ECU
 SG_ E_ECU_Ver_Day : 56|8@1+ (1,0) [1|49] ""  JiaShiCang
 SG_ E_ECU_Ver_Month : 48|8@1+ (1,0) [1|18] ""  JiaShiCang
 SG_ E_ECU_Ver_Year : 32|16@1+ (1,0) [0|39321] ""  JiaShiCang
 SG_ E_ECU_Ver_D : 24|8@1+ (1,0) [0|153] ""  JiaShiCang
 SG_ E_ECU_Ver_C : 16|8@1+ (1,0) [0|153] ""  JiaShiCang
 SG_ E_ECU_Ver_B : 8|8@1+ (1,0) [0|153] ""  JiaShiCang
 SG_ E_ECU_Ver_A : 0|8@1+ (1,0) [0|153] ""  JiaShiCang

BO_ 2416246832 Msg_E_BIT_Msg: 8 EMPC_ECU
 SG_ BackUp480 : 35|5@1+ (1,0) [0|0] ""  JiaShiCang
 SG_ E_HLT28IOver : 34|1@1+ (1,0) [0|1] ""  JiaShiCang
 SG_ E_WaiBu270IOver : 33|1@1+ (1,0) [0|1] ""  JiaShiCang
 SG_ E_HLT270IOver : 32|1@1+ (1,0) [0|1] ""  JiaShiCang
 SG_ BackUp479 : 30|2@1+ (1,0) [0|0] ""  JiaShiCang
 SG_ E_HLT28USta : 28|2@1+ (1,0) [0|3] ""  JiaShiCang
 SG_ E_DCDC28OutUSta : 26|2@1+ (1,0) [0|3] ""  JiaShiCang
 SG_ E_DCDC270InUSta : 24|2@1+ (1,0) [0|3] ""  JiaShiCang
 SG_ E_HLT270USta : 22|2@1+ (1,0) [0|3] ""  JiaShiCang
 SG_ E_ChongDianUSta : 20|2@1+ (1,0) [0|3] ""  JiaShiCang
 SG_ E_WaiBu270USta : 18|2@1+ (1,0) [0|3] ""  JiaShiCang
 SG_ E_Batter270USta : 16|2@1+ (1,0) [0|3] ""  JiaShiCang
 SG_ BackUp478 : 8|8@1+ (1,0) [0|0] ""  JiaShiCang
 SG_ E_ADCIN_BIT : 7|1@1+ (1,0) [0|1] ""  JiaShiCang
 SG_ E_GpioIN_BIT : 6|1@1+ (1,0) [0|1] ""  JiaShiCang
 SG_ E_Flash_BIT : 5|1@1+ (1,0) [0|1] ""  JiaShiCang
 SG_ E_UART_BIT : 4|1@1+ (1,0) [0|1] ""  JiaShiCang
 SG_ E_ExtCAN2_BIT : 3|1@1+ (1,0) [0|1] ""  JiaShiCang
 SG_ E_ExtCAN1_BIT : 2|1@1+ (1,0) [0|1] ""  JiaShiCang
 SG_ E_CPU_BIT : 1|1@1+ (1,0) [0|1] ""  JiaShiCang
 SG_ E_Pow_BIT : 0|1@1+ (1,0) [0|1] ""  JiaShiCang

BO_ 2416115760 Msg_E_JieChuQi_State: 1 EMPC_ECU
 SG_ BackUp477 : 6|2@1+ (1,0) [0|0] ""  JiaShiCang
 SG_ CPC_B_STA : 4|2@1+ (1,0) [0|3] ""  JiaShiCang
 SG_ CPC_A_STA : 2|2@1+ (1,0) [0|3] ""  JiaShiCang
 SG_ EPC_STA : 0|2@1+ (1,0) [0|3] ""  JiaShiCang

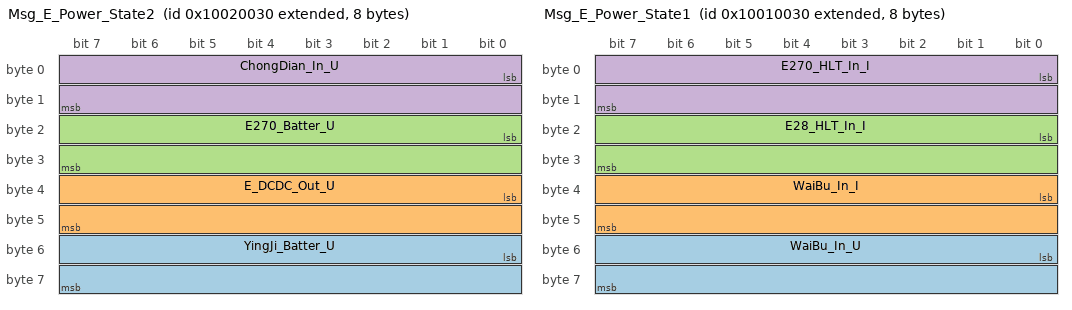
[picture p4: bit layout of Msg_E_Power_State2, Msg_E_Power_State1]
BO_ 2416050224 Msg_E_Power_State2: 8 EMPC_ECU
 SG_ YingJi_Batter_U : 48|16@1+ (0.1,0) [0|6553.5] "V"  JiaShiCang
 SG_ E_DCDC_Out_U : 32|16@1+ (0.1,0) [0|6553.5] "V"  JiaShiCang
 SG_ E270_Batter_U : 16|16@1+ (0.1,0) [0|6553.5] "V"  JiaShiCang
 SG_ ChongDian_In_U : 0|16@1+ (0.1,0) [0|6553.5] "V"  JiaShiCang

BO_ 2415984688 Msg_E_Power_State1: 8 EMPC_ECU
 SG_ WaiBu_In_U : 48|16@1+ (0.1,0) [0|6553.5] "V"  JiaShiCang
 SG_ WaiBu_In_I : 32|16@1+ (0.1,0) [0|6553.5] "A"  JiaShiCang
 SG_ E28_HLT_In_I : 16|16@1+ (0.1,0) [0|6553.5] "A"  JiaShiCang
 SG_ E270_HLT_In_I : 0|16@1+ (0.1,0) [0|6553.5] "A"  JiaShiCang

BO_ 2421178400 Msg_R_ChongGou_JiaoHu: 8 R_BPCU_BCU
 SG_ BackUp476 : 56|8@1+ (1,0) [0|0] ""  L_BPCU_BCU,EMPC_ECU
 SG_ BackUp475 : 48|8@1+ (1,0) [0|0] ""  L_BPCU_BCU,EMPC_ECU
 SG_ BackUp474 : 32|16@1+ (1,0) [0|0] ""  L_BPCU_BCU,EMPC_ECU
 SG_ BackUp473 : 24|8@1+ (1,0) [0|0] ""  L_BPCU_BCU,EMPC_ECU
 SG_ BackUp472 : 23|1@1+ (1,0) [0|0] ""  L_BPCU_BCU,EMPC_ECU
 SG_ BackUp471 : 22|1@1+ (1,0) [0|0] ""  L_BPCU_BCU,EMPC_ECU
 SG_ BackUp470 : 20|2@1+ (1,0) [0|0] ""  L_BPCU_BCU,EMPC_ECU
 SG_ RETC1_ChongGou_ChangJing : 18|2@1+ (1,0) [0|3] ""  L_BPCU_BCU,EMPC_ECU
 SG_ RETC1_STA_ChongGou : 16|2@1+ (1,0) [0|3] ""  L_BPCU_BCU,EMPC_ECU
 SG_ BackUp469 : 14|2@1+ (1,0) [0|0] ""  L_BPCU_BCU,EMPC_ECU
 SG_ BackUp468 : 13|1@1+ (1,0) [0|0] ""  L_BPCU_BCU,EMPC_ECU
 SG_ BackUp467 : 12|1@1+ (1,0) [0|0] ""  L_BPCU_BCU,EMPC_ECU
 SG_ BackUp466 : 11|1@1+ (1,0) [0|0] ""  L_BPCU_BCU,EMPC_ECU
 SG_ BackUp465 : 10|1@1+ (1,0) [0|0] ""  L_BPCU_BCU,EMPC_ECU
 SG_ RDC2_Ctrl : 9|1@1+ (1,0) [0|1] ""  L_BPCU_BCU,EMPC_ECU
 SG_ RDC1_Ctrl : 8|1@1+ (1,0) [0|1] ""  L_BPCU_BCU,EMPC_ECU
 SG_ BackUp464 : 6|2@1+ (1,0) [0|0] ""  L_BPCU_BCU,EMPC_ECU
 SG_ BTC1_ChongGou_ChangJing : 4|2@1+ (1,0) [0|3] ""  L_BPCU_BCU,EMPC_ECU
 SG_ RETC1_ReSta : 3|1@1+ (1,0) [0|1] ""  L_BPCU_BCU,EMPC_ECU
 SG_ R_HLT282IOver_ChongGou : 2|1@1+ (1,0) [0|1] ""  L_BPCU_BCU,EMPC_ECU
 SG_ R_HLT281IOver_ChongGou : 1|1@1+ (1,0) [0|1] ""  L_BPCU_BCU,EMPC_ECU
 SG_ R_HLT270IOver_ChongGou : 0|1@1+ (1,0) [0|1] ""  L_BPCU_BCU,EMPC_ECU

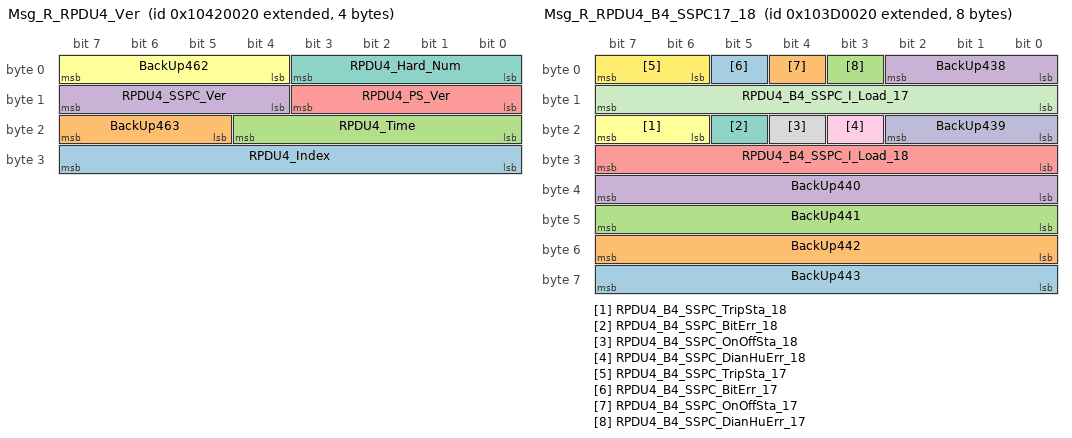
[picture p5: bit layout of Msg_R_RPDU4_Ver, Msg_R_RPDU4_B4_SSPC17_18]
BO_ 2420244512 Msg_R_RPDU4_Ver: 4 R_BPCU_BCU
 SG_ RPDU4_Index : 24|8@1+ (1,0) [0|255] ""  JiaShiCang
 SG_ BackUp463 : 21|3@1+ (1,0) [0|0] ""  JiaShiCang
 SG_ RPDU4_Time : 16|5@1+ (1,0) [0|31] ""  JiaShiCang
 SG_ RPDU4_SSPC_Ver : 12|4@1+ (1,0) [0|15] ""  JiaShiCang
 SG_ RPDU4_PS_Ver : 8|4@1+ (1,0) [0|15] ""  JiaShiCang
 SG_ BackUp462 : 4|4@1+ (1,0) [0|0] ""  JiaShiCang
 SG_ RPDU4_Hard_Num : 0|4@1+ (1,0) [0|15] ""  JiaShiCang

BO_ 2420178976 Msg_R_RPDU4_B6_SSPC05_07: 8 R_BPCU_BCU
 SG_ BackUp461 : 56|8@1+ (1,0) [0|0] ""  JiaShiCang
 SG_ BackUp460 : 48|8@1+ (1,0) [0|0] ""  JiaShiCang
 SG_ RPDU4_B6_SSPC_I_Load_07 : 40|8@1+ (0.1,0) [0|25.5] "A"  JiaShiCang
 SG_ RPDU4_B6_SSPC_TripSta_07 : 38|2@1+ (1,0) [0|3] ""  JiaShiCang
 SG_ RPDU4_B6_SSPC_BitErr_07 : 37|1@1+ (1,0) [0|1] ""  JiaShiCang
 SG_ RPDU4_B6_SSPC_OnOffSta_07 : 36|1@1+ (1,0) [0|1] ""  JiaShiCang
 SG_ RPDU4_B6_SSPC_DianHuErr_07 : 35|1@1+ (1,0) [0|1] ""  JiaShiCang
 SG_ BackUp459 : 32|3@1+ (1,0) [0|0] ""  JiaShiCang
 SG_ RPDU4_B6_SSPC_I_Load_06 : 24|8@1+ (0.1,0) [0|25.5] "A"  JiaShiCang
 SG_ RPDU4_B6_SSPC_TripSta_06 : 22|2@1+ (1,0) [0|3] ""  JiaShiCang
 SG_ RPDU4_B6_SSPC_BitErr_06 : 21|1@1+ (1,0) [0|1] ""  JiaShiCang
 SG_ RPDU4_B6_SSPC_OnOffSta_06 : 20|1@1+ (1,0) [0|1] ""  JiaShiCang
 SG_ RPDU4_B6_SSPC_DianHuErr_06 : 19|1@1+ (1,0) [0|1] ""  JiaShiCang
 SG_ BackUp458 : 16|3@1+ (1,0) [0|0] ""  JiaShiCang
 SG_ RPDU4_B6_SSPC_I_Load_05 : 8|8@1+ (0.1,0) [0|25.5] "A"  JiaShiCang
 SG_ RPDU4_B6_SSPC_TripSta_05 : 6|2@1+ (1,0) [0|3] ""  JiaShiCang
 SG_ RPDU4_B6_SSPC_BitErr_05 : 5|1@1+ (1,0) [0|1] ""  JiaShiCang
 SG_ RPDU4_B6_SSPC_OnOffSta_05 : 4|1@1+ (1,0) [0|1] ""  JiaShiCang
 SG_ RPDU4_B6_SSPC_DianHuErr_05 : 3|1@1+ (1,0) [0|1] ""  JiaShiCang
 SG_ BackUp457 : 0|3@1+ (1,0) [0|0] ""  JiaShiCang

BO_ 2420113440 Msg_R_RPDU4_B6_SSPC01_04: 8 R_BPCU_BCU
 SG_ RPDU4_B6_SSPC_I_Load_04 : 56|8@1+ (0.1,0) [0|25.5] "A"  JiaShiCang
 SG_ RPDU4_B6_SSPC_TripSta_04 : 54|2@1+ (1,0) [0|3] ""  JiaShiCang
 SG_ RPDU4_B6_SSPC_BitErr_04 : 53|1@1+ (1,0) [0|1] ""  JiaShiCang
 SG_ RPDU4_B6_SSPC_OnOffSta_04 : 52|1@1+ (1,0) [0|1] ""  JiaShiCang
 SG_ RPDU4_B6_SSPC_DianHuErr_04 : 51|1@1+ (1,0) [0|1] ""  JiaShiCang
 SG_ BackUp456 : 48|3@1+ (1,0) [0|0] ""  JiaShiCang
 SG_ RPDU4_B6_SSPC_I_Load_03 : 40|8@1+ (0.1,0) [0|25.5] "A"  JiaShiCang
 SG_ RPDU4_B6_SSPC_TripSta_03 : 38|2@1+ (1,0) [0|3] ""  JiaShiCang
 SG_ RPDU4_B6_SSPC_BitErr_03 : 37|1@1+ (1,0) [0|1] ""  JiaShiCang
 SG_ RPDU4_B6_SSPC_OnOffSta_03 : 36|1@1+ (1,0) [0|1] ""  JiaShiCang
 SG_ RPDU4_B6_SSPC_DianHuErr_03 : 35|1@1+ (1,0) [0|1] ""  JiaShiCang
 SG_ BackUp455 : 32|3@1+ (1,0) [0|0] ""  JiaShiCang
 SG_ RPDU4_B6_SSPC_I_Load_02 : 24|8@1+ (0.1,0) [0|25.5] "A"  JiaShiCang
 SG_ RPDU4_B6_SSPC_TripSta_02 : 22|2@1+ (1,0) [0|3] ""  JiaShiCang
 SG_ RPDU4_B6_SSPC_BitErr_02 : 21|1@1+ (1,0) [0|1] ""  JiaShiCang
 SG_ RPDU4_B6_SSPC_OnOffSta_02 : 20|1@1+ (1,0) [0|1] ""  JiaShiCang
 SG_ RPDU4_B6_SSPC_DianHuErr_02 : 19|1@1+ (1,0) [0|1] ""  JiaShiCang
 SG_ BackUp454 : 16|3@1+ (1,0) [0|0] ""  JiaShiCang
 SG_ RPDU4_B6_SSPC_I_Load_01 : 8|8@1+ (0.1,0) [0|25.5] "A"  JiaShiCang
 SG_ RPDU4_B6_SSPC_TripSta_01 : 6|2@1+ (1,0) [0|3] ""  JiaShiCang
 SG_ RPDU4_B6_SSPC_BitErr_01 : 5|1@1+ (1,0) [0|1] ""  JiaShiCang
 SG_ RPDU4_B6_SSPC_OnOffSta_01 : 4|1@1+ (1,0) [0|1] ""  JiaShiCang
 SG_ RPDU4_B6_SSPC_DianHuErr_01 : 3|1@1+ (1,0) [0|1] ""  JiaShiCang
 SG_ BackUp453 : 0|3@1+ (1,0) [0|0] ""  JiaShiCang

BO_ 2420047904 Msg_R_RPDU4_B5_SSPC05_07: 8 R_BPCU_BCU
 SG_ BackUp452 : 56|8@1+ (1,0) [0|0] ""  JiaShiCang
 SG_ BackUp451 : 48|8@1+ (1,0) [0|0] ""  JiaShiCang
 SG_ RPDU4_B5_SSPC_I_Load_07 : 40|8@1+ (0.1,0) [0|25.5] "A"  JiaShiCang
 SG_ RPDU4_B5_SSPC_TripSta_07 : 38|2@1+ (1,0) [0|3] ""  JiaShiCang
 SG_ RPDU4_B5_SSPC_BitErr_07 : 37|1@1+ (1,0) [0|1] ""  JiaShiCang
 SG_ RPDU4_B5_SSPC_OnOffSta_07 : 36|1@1+ (1,0) [0|1] ""  JiaShiCang
 SG_ RPDU4_B5_SSPC_DianHuErr_07 : 35|1@1+ (1,0) [0|1] ""  JiaShiCang
 SG_ BackUp450 : 32|3@1+ (1,0) [0|0] ""  JiaShiCang
 SG_ RPDU4_B5_SSPC_I_Load_06 : 24|8@1+ (0.1,0) [0|25.5] "A"  JiaShiCang
 SG_ RPDU4_B5_SSPC_TripSta_06 : 22|2@1+ (1,0) [0|3] ""  JiaShiCang
 SG_ RPDU4_B5_SSPC_BitErr_06 : 21|1@1+ (1,0) [0|1] ""  JiaShiCang
 SG_ RPDU4_B5_SSPC_OnOffSta_06 : 20|1@1+ (1,0) [0|1] ""  JiaShiCang
 SG_ RPDU4_B5_SSPC_DianHuErr_06 : 19|1@1+ (1,0) [0|1] ""  JiaShiCang
 SG_ BackUp449 : 16|3@1+ (1,0) [0|0] ""  JiaShiCang
 SG_ RPDU4_B5_SSPC_I_Load_05 : 8|8@1+ (0.1,0) [0|25.5] "A"  JiaShiCang
 SG_ RPDU4_B5_SSPC_TripSta_05 : 6|2@1+ (1,0) [0|3] ""  JiaShiCang
 SG_ RPDU4_B5_SSPC_BitErr_05 : 5|1@1+ (1,0) [0|1] ""  JiaShiCang
 SG_ RPDU4_B5_SSPC_OnOffSta_05 : 4|1@1+ (1,0) [0|1] ""  JiaShiCang
 SG_ RPDU4_B5_SSPC_DianHuErr_05 : 3|1@1+ (1,0) [0|1] ""  JiaShiCang
 SG_ BackUp448 : 0|3@1+ (1,0) [0|0] ""  JiaShiCang

BO_ 2419982368 Msg_R_RPDU4_B5_SSPC01_04: 8 R_BPCU_BCU
 SG_ RPDU4_B5_SSPC_I_Load_04 : 56|8@1+ (0.1,0) [0|25.5] "A"  JiaShiCang
 SG_ RPDU4_B5_SSPC_TripSta_04 : 54|2@1+ (1,0) [0|3] ""  JiaShiCang
 SG_ RPDU4_B5_SSPC_BitErr_04 : 53|1@1+ (1,0) [0|1] ""  JiaShiCang
 SG_ RPDU4_B5_SSPC_OnOffSta_04 : 52|1@1+ (1,0) [0|1] ""  JiaShiCang
 SG_ RPDU4_B5_SSPC_DianHuErr_04 : 51|1@1+ (1,0) [0|1] ""  JiaShiCang
 SG_ BackUp447 : 48|3@1+ (1,0) [0|0] ""  JiaShiCang
 SG_ RPDU4_B5_SSPC_I_Load_03 : 40|8@1+ (0.1,0) [0|25.5] "A"  JiaShiCang
 SG_ RPDU4_B5_SSPC_TripSta_03 : 38|2@1+ (1,0) [0|3] ""  JiaShiCang
 SG_ RPDU4_B5_SSPC_BitErr_03 : 37|1@1+ (1,0) [0|1] ""  JiaShiCang
 SG_ RPDU4_B5_SSPC_OnOffSta_03 : 36|1@1+ (1,0) [0|1] ""  JiaShiCang
 SG_ RPDU4_B5_SSPC_DianHuErr_03 : 35|1@1+ (1,0) [0|1] ""  JiaShiCang
 SG_ BackUp446 : 32|3@1+ (1,0) [0|0] ""  JiaShiCang
 SG_ RPDU4_B5_SSPC_I_Load_02 : 24|8@1+ (0.1,0) [0|25.5] "A"  JiaShiCang
 SG_ RPDU4_B5_SSPC_TripSta_02 : 22|2@1+ (1,0) [0|3] ""  JiaShiCang
 SG_ RPDU4_B5_SSPC_BitErr_02 : 21|1@1+ (1,0) [0|1] ""  JiaShiCang
 SG_ RPDU4_B5_SSPC_OnOffSta_02 : 20|1@1+ (1,0) [0|1] ""  JiaShiCang
 SG_ RPDU4_B5_SSPC_DianHuErr_02 : 19|1@1+ (1,0) [0|1] ""  JiaShiCang
 SG_ BackUp445 : 16|3@1+ (1,0) [0|0] ""  JiaShiCang
 SG_ RPDU4_B5_SSPC_I_Load_01 : 8|8@1+ (0.1,0) [0|25.5] "A"  JiaShiCang
 SG_ RPDU4_B5_SSPC_TripSta_01 : 6|2@1+ (1,0) [0|3] ""  JiaShiCang
 SG_ RPDU4_B5_SSPC_BitErr_01 : 5|1@1+ (1,0) [0|1] ""  JiaShiCang
 SG_ RPDU4_B5_SSPC_OnOffSta_01 : 4|1@1+ (1,0) [0|1] ""  JiaShiCang
 SG_ RPDU4_B5_SSPC_DianHuErr_01 : 3|1@1+ (1,0) [0|1] ""  JiaShiCang
 SG_ BackUp444 : 0|3@1+ (1,0) [0|0] ""  JiaShiCang

BO_ 2419916832 Msg_R_RPDU4_B4_SSPC17_18: 8 R_BPCU_BCU
 SG_ BackUp443 : 56|8@1+ (1,0) [0|0] ""  JiaShiCang
 SG_ BackUp442 : 48|8@1+ (1,0) [0|0] ""  JiaShiCang
 SG_ BackUp441 : 40|8@1+ (1,0) [0|0] ""  JiaShiCang
 SG_ BackUp440 : 32|8@1+ (1,0) [0|0] ""  JiaShiCang
 SG_ RPDU4_B4_SSPC_I_Load_18 : 24|8@1+ (0.1,0) [0|25.5] "A"  JiaShiCang
 SG_ RPDU4_B4_SSPC_TripSta_18 : 22|2@1+ (1,0) [0|3] ""  JiaShiCang
 SG_ RPDU4_B4_SSPC_BitErr_18 : 21|1@1+ (1,0) [0|1] ""  JiaShiCang
 SG_ RPDU4_B4_SSPC_OnOffSta_18 : 20|1@1+ (1,0) [0|1] ""  JiaShiCang
 SG_ RPDU4_B4_SSPC_DianHuErr_18 : 19|1@1+ (1,0) [0|1] ""  JiaShiCang
 SG_ BackUp439 : 16|3@1+ (1,0) [0|0] ""  JiaShiCang
 SG_ RPDU4_B4_SSPC_I_Load_17 : 8|8@1+ (0.1,0) [0|25.5] "A"  JiaShiCang
 SG_ RPDU4_B4_SSPC_TripSta_17 : 6|2@1+ (1,0) [0|3] ""  JiaShiCang
 SG_ RPDU4_B4_SSPC_BitErr_17 : 5|1@1+ (1,0) [0|1] ""  JiaShiCang
 SG_ RPDU4_B4_SSPC_OnOffSta_17 : 4|1@1+ (1,0) [0|1] ""  JiaShiCang
 SG_ RPDU4_B4_SSPC_DianHuErr_17 : 3|1@1+ (1,0) [0|1] ""  JiaShiCang
 SG_ BackUp438 : 0|3@1+ (1,0) [0|0] ""  JiaShiCang

BO_ 2419851296 Msg_R_RPDU4_B4_SSPC13_16: 8 R_BPCU_BCU
 SG_ RPDU4_B4_SSPC_I_Load_16 : 56|8@1+ (0.1,0) [0|25.5] "A"  JiaShiCang
 SG_ RPDU4_B4_SSPC_TripSta_16 : 54|2@1+ (1,0) [0|3] ""  JiaShiCang
 SG_ RPDU4_B4_SSPC_BitErr_16 : 53|1@1+ (1,0) [0|1] ""  JiaShiCang
 SG_ RPDU4_B4_SSPC_OnOffSta_16 : 52|1@1+ (1,0) [0|1] ""  JiaShiCang
 SG_ RPDU4_B4_SSPC_DianHuErr_16 : 51|1@1+ (1,0) [0|1] ""  JiaShiCang
 SG_ BackUp437 : 48|3@1+ (1,0) [0|0] ""  JiaShiCang
 SG_ RPDU4_B4_SSPC_I_Load_15 : 40|8@1+ (0.1,0) [0|25.5] "A"  JiaShiCang
 SG_ RPDU4_B4_SSPC_TripSta_15 : 38|2@1+ (1,0) [0|3] ""  JiaShiCang
 SG_ RPDU4_B4_SSPC_BitErr_15 : 37|1@1+ (1,0) [0|1] ""  JiaShiCang
 SG_ RPDU4_B4_SSPC_OnOffSta_15 : 36|1@1+ (1,0) [0|1] ""  JiaShiCang
 SG_ RPDU4_B4_SSPC_DianHuErr_15 : 35|1@1+ (1,0) [0|1] ""  JiaShiCang
 SG_ BackUp436 : 32|3@1+ (1,0) [0|0] ""  JiaShiCang
 SG_ RPDU4_B4_SSPC_I_Load_14 : 24|8@1+ (0.1,0) [0|25.5] "A"  JiaShiCang
 SG_ RPDU4_B4_SSPC_TripSta_14 : 22|2@1+ (1,0) [0|3] ""  JiaShiCang
 SG_ RPDU4_B4_SSPC_BitErr_14 : 21|1@1+ (1,0) [0|1] ""  JiaShiCang
 SG_ RPDU4_B4_SSPC_OnOffSta_14 : 20|1@1+ (1,0) [0|1] ""  JiaShiCang
 SG_ RPDU4_B4_SSPC_DianHuErr_14 : 19|1@1+ (1,0) [0|1] ""  JiaShiCang
 SG_ BackUp435 : 16|3@1+ (1,0) [0|0] ""  JiaShiCang
 SG_ RPDU4_B4_SSPC_I_Load_13 : 8|8@1+ (0.1,0) [0|25.5] "A"  JiaShiCang
 SG_ RPDU4_B4_SSPC_TripSta_13 : 6|2@1+ (1,0) [0|3] ""  JiaShiCang
 SG_ RPDU4_B4_SSPC_BitErr_13 : 5|1@1+ (1,0) [0|1] ""  JiaShiCang
 SG_ RPDU4_B4_SSPC_OnOffSta_13 : 4|1@1+ (1,0) [0|1] ""  JiaShiCang
 SG_ RPDU4_B4_SSPC_DianHuErr_13 : 3|1@1+ (1,0) [0|1] ""  JiaShiCang
 SG_ BackUp434 : 0|3@1+ (1,0) [0|0] ""  JiaShiCang

BO_ 2419785760 Msg_R_RPDU4_B4_SSPC09_12: 8 R_BPCU_BCU
 SG_ RPDU4_B4_SSPC_I_Load_12 : 56|8@1+ (0.1,0) [0|25.5] "A"  JiaShiCang
 SG_ RPDU4_B4_SSPC_TripSta_12 : 54|2@1+ (1,0) [0|3] ""  JiaShiCang
 SG_ RPDU4_B4_SSPC_BitErr_12 : 53|1@1+ (1,0) [0|1] ""  JiaShiCang
 SG_ RPDU4_B4_SSPC_OnOffSta_12 : 52|1@1+ (1,0) [0|1] ""  JiaShiCang
 SG_ RPDU4_B4_SSPC_DianHuErr_12 : 51|1@1+ (1,0) [0|1] ""  JiaShiCang
 SG_ BackUp433 : 48|3@1+ (1,0) [0|0] ""  JiaShiCang
 SG_ RPDU4_B4_SSPC_I_Load_11 : 40|8@1+ (0.1,0) [0|25.5] "A"  JiaShiCang
 SG_ RPDU4_B4_SSPC_TripSta_11 : 38|2@1+ (1,0) [0|3] ""  JiaShiCang
 SG_ RPDU4_B4_SSPC_BitErr_11 : 37|1@1+ (1,0) [0|1] ""  JiaShiCang
 SG_ RPDU4_B4_SSPC_OnOffSta_11 : 36|1@1+ (1,0) [0|1] ""  JiaShiCang
 SG_ RPDU4_B4_SSPC_DianHuErr_11 : 35|1@1+ (1,0) [0|1] ""  JiaShiCang
 SG_ BackUp432 : 32|3@1+ (1,0) [0|0] ""  JiaShiCang
 SG_ RPDU4_B4_SSPC_I_Load_10 : 24|8@1+ (0.1,0) [0|25.5] "A"  JiaShiCang
 SG_ RPDU4_B4_SSPC_TripSta_10 : 22|2@1+ (1,0) [0|3] ""  JiaShiCang
 SG_ RPDU4_B4_SSPC_BitErr_10 : 21|1@1+ (1,0) [0|1] ""  JiaShiCang
 SG_ RPDU4_B4_SSPC_OnOffSta_10 : 20|1@1+ (1,0) [0|1] ""  JiaShiCang
 SG_ RPDU4_B4_SSPC_DianHuErr_10 : 19|1@1+ (1,0) [0|1] ""  JiaShiCang
 SG_ BackUp431 : 16|3@1+ (1,0) [0|0] ""  JiaShiCang
 SG_ RPDU4_B4_SSPC_I_Load_09 : 8|8@1+ (0.1,0) [0|25.5] "A"  JiaShiCang
 SG_ RPDU4_B4_SSPC_TripSta_09 : 6|2@1+ (1,0) [0|3] ""  JiaShiCang
 SG_ RPDU4_B4_SSPC_BitErr_09 : 5|1@1+ (1,0) [0|1] ""  JiaShiCang
 SG_ RPDU4_B4_SSPC_OnOffSta_09 : 4|1@1+ (1,0) [0|1] ""  JiaShiCang
 SG_ RPDU4_B4_SSPC_DianHuErr_09 : 3|1@1+ (1,0) [0|1] ""  JiaShiCang
 SG_ BackUp430 : 0|3@1+ (1,0) [0|0] ""  JiaShiCang

BO_ 2419720224 Msg_R_RPDU4_B4_SSPC05_08: 8 R_BPCU_BCU
 SG_ RPDU4_B4_SSPC_I_Load_08 : 56|8@1+ (0.1,0) [0|25.5] "A"  JiaShiCang
 SG_ RPDU4_B4_SSPC_TripSta_08 : 54|2@1+ (1,0) [0|3] ""  JiaShiCang
 SG_ RPDU4_B4_SSPC_BitErr_08 : 53|1@1+ (1,0) [0|1] ""  JiaShiCang
 SG_ RPDU4_B4_SSPC_OnOffSta_08 : 52|1@1+ (1,0) [0|1] ""  JiaShiCang
 SG_ RPDU4_B4_SSPC_DianHuErr_08 : 51|1@1+ (1,0) [0|1] ""  JiaShiCang
 SG_ BackUp429 : 48|3@1+ (1,0) [0|0] ""  JiaShiCang
 SG_ RPDU4_B4_SSPC_I_Load_07 : 40|8@1+ (0.1,0) [0|25.5] "A"  JiaShiCang
 SG_ RPDU4_B4_SSPC_TripSta_07 : 38|2@1+ (1,0) [0|3] ""  JiaShiCang
 SG_ RPDU4_B4_SSPC_BitErr_07 : 37|1@1+ (1,0) [0|1] ""  JiaShiCang
 SG_ RPDU4_B4_SSPC_OnOffSta_07 : 36|1@1+ (1,0) [0|1] ""  JiaShiCang
 SG_ RPDU4_B4_SSPC_DianHuErr_07 : 35|1@1+ (1,0) [0|1] ""  JiaShiCang
 SG_ BackUp428 : 32|3@1+ (1,0) [0|0] ""  JiaShiCang
 SG_ RPDU4_B4_SSPC_I_Load_06 : 24|8@1+ (0.1,0) [0|25.5] "A"  JiaShiCang
 SG_ RPDU4_B4_SSPC_TripSta_06 : 22|2@1+ (1,0) [0|3] ""  JiaShiCang
 SG_ RPDU4_B4_SSPC_BitErr_06 : 21|1@1+ (1,0) [0|1] ""  JiaShiCang
 SG_ RPDU4_B4_SSPC_OnOffSta_06 : 20|1@1+ (1,0) [0|1] ""  JiaShiCang
 SG_ RPDU4_B4_SSPC_DianHuErr_06 : 19|1@1+ (1,0) [0|1] ""  JiaShiCang
 SG_ BackUp427 : 16|3@1+ (1,0) [0|0] ""  JiaShiCang
 SG_ RPDU4_B4_SSPC_I_Load_05 : 8|8@1+ (0.1,0) [0|25.5] "A"  JiaShiCang
 SG_ RPDU4_B4_SSPC_TripSta_05 : 6|2@1+ (1,0) [0|3] ""  JiaShiCang
 SG_ RPDU4_B4_SSPC_BitErr_05 : 5|1@1+ (1,0) [0|1] ""  JiaShiCang
 SG_ RPDU4_B4_SSPC_OnOffSta_05 : 4|1@1+ (1,0) [0|1] ""  JiaShiCang
 SG_ RPDU4_B4_SSPC_DianHuErr_05 : 3|1@1+ (1,0) [0|1] ""  JiaShiCang
 SG_ BackUp426 : 0|3@1+ (1,0) [0|0] ""  JiaShiCang

BO_ 2419654688 Msg_R_RPDU4_B4_SSPC01_04: 8 R_BPCU_BCU
 SG_ RPDU4_B4_SSPC_I_Load_04 : 56|8@1+ (0.1,0) [0|25.5] "A"  JiaShiCang
 SG_ RPDU4_B4_SSPC_TripSta_04 : 54|2@1+ (1,0) [0|3] ""  JiaShiCang
 SG_ RPDU4_B4_SSPC_BitErr_04 : 53|1@1+ (1,0) [0|1] ""  JiaShiCang
 SG_ RPDU4_B4_SSPC_OnOffSta_04 : 52|1@1+ (1,0) [0|1] ""  JiaShiCang
 SG_ RPDU4_B4_SSPC_DianHuErr_04 : 51|1@1+ (1,0) [0|1] ""  JiaShiCang
 SG_ BackUp425 : 48|3@1+ (1,0) [0|0] ""  JiaShiCang
 SG_ RPDU4_B4_SSPC_I_Load_03 : 40|8@1+ (0.1,0) [0|25.5] "A"  JiaShiCang
 SG_ RPDU4_B4_SSPC_TripSta_03 : 38|2@1+ (1,0) [0|3] ""  JiaShiCang
 SG_ RPDU4_B4_SSPC_BitErr_03 : 37|1@1+ (1,0) [0|1] ""  JiaShiCang
 SG_ RPDU4_B4_SSPC_OnOffSta_03 : 36|1@1+ (1,0) [0|1] ""  JiaShiCang
 SG_ RPDU4_B4_SSPC_DianHuErr_03 : 35|1@1+ (1,0) [0|1] ""  JiaShiCang
 SG_ BackUp424 : 32|3@1+ (1,0) [0|0] ""  JiaShiCang
 SG_ RPDU4_B4_SSPC_I_Load_02 : 24|8@1+ (0.1,0) [0|25.5] "A"  JiaShiCang
 SG_ RPDU4_B4_SSPC_TripSta_02 : 22|2@1+ (1,0) [0|3] ""  JiaShiCang
 SG_ RPDU4_B4_SSPC_BitErr_02 : 21|1@1+ (1,0) [0|1] ""  JiaShiCang
 SG_ RPDU4_B4_SSPC_OnOffSta_02 : 20|1@1+ (1,0) [0|1] ""  JiaShiCang
 SG_ RPDU4_B4_SSPC_DianHuErr_02 : 19|1@1+ (1,0) [0|1] ""  JiaShiCang
 SG_ BackUp423 : 16|3@1+ (1,0) [0|0] ""  JiaShiCang
 SG_ RPDU4_B4_SSPC_I_Load_01 : 8|8@1+ (0.1,0) [0|25.5] "A"  JiaShiCang
 SG_ RPDU4_B4_SSPC_TripSta_01 : 6|2@1+ (1,0) [0|3] ""  JiaShiCang
 SG_ RPDU4_B4_SSPC_BitErr_01 : 5|1@1+ (1,0) [0|1] ""  JiaShiCang
 SG_ RPDU4_B4_SSPC_OnOffSta_01 : 4|1@1+ (1,0) [0|1] ""  JiaShiCang
 SG_ RPDU4_B4_SSPC_DianHuErr_01 : 3|1@1+ (1,0) [0|1] ""  JiaShiCang
 SG_ BackUp422 : 0|3@1+ (1,0) [0|0] ""  JiaShiCang

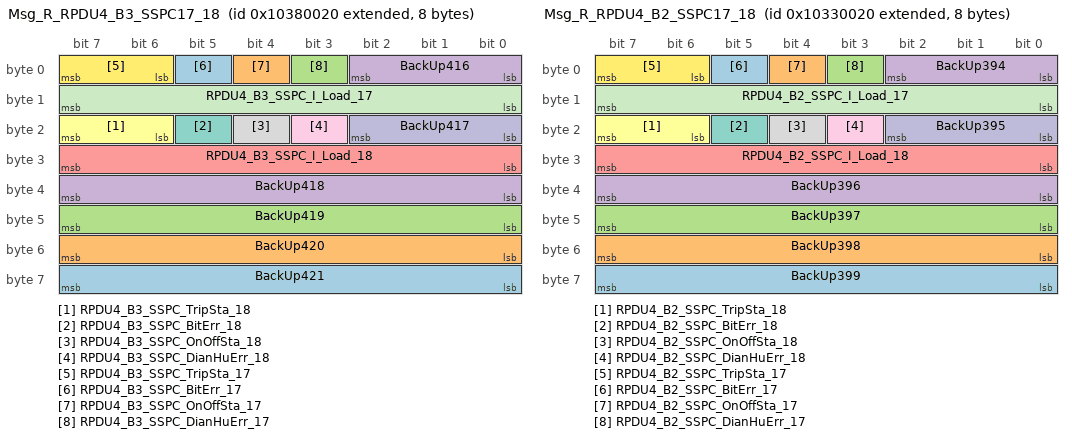
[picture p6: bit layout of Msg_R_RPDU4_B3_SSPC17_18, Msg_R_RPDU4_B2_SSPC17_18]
BO_ 2419589152 Msg_R_RPDU4_B3_SSPC17_18: 8 R_BPCU_BCU
 SG_ BackUp421 : 56|8@1+ (1,0) [0|0] ""  JiaShiCang
 SG_ BackUp420 : 48|8@1+ (1,0) [0|0] ""  JiaShiCang
 SG_ BackUp419 : 40|8@1+ (1,0) [0|0] ""  JiaShiCang
 SG_ BackUp418 : 32|8@1+ (1,0) [0|0] ""  JiaShiCang
 SG_ RPDU4_B3_SSPC_I_Load_18 : 24|8@1+ (0.1,0) [0|25.5] "A"  JiaShiCang
 SG_ RPDU4_B3_SSPC_TripSta_18 : 22|2@1+ (1,0) [0|3] ""  JiaShiCang
 SG_ RPDU4_B3_SSPC_BitErr_18 : 21|1@1+ (1,0) [0|1] ""  JiaShiCang
 SG_ RPDU4_B3_SSPC_OnOffSta_18 : 20|1@1+ (1,0) [0|1] ""  JiaShiCang
 SG_ RPDU4_B3_SSPC_DianHuErr_18 : 19|1@1+ (1,0) [0|1] ""  JiaShiCang
 SG_ BackUp417 : 16|3@1+ (1,0) [0|0] ""  JiaShiCang
 SG_ RPDU4_B3_SSPC_I_Load_17 : 8|8@1+ (0.1,0) [0|25.5] "A"  JiaShiCang
 SG_ RPDU4_B3_SSPC_TripSta_17 : 6|2@1+ (1,0) [0|3] ""  JiaShiCang
 SG_ RPDU4_B3_SSPC_BitErr_17 : 5|1@1+ (1,0) [0|1] ""  JiaShiCang
 SG_ RPDU4_B3_SSPC_OnOffSta_17 : 4|1@1+ (1,0) [0|1] ""  JiaShiCang
 SG_ RPDU4_B3_SSPC_DianHuErr_17 : 3|1@1+ (1,0) [0|1] ""  JiaShiCang
 SG_ BackUp416 : 0|3@1+ (1,0) [0|0] ""  JiaShiCang

BO_ 2419523616 Msg_R_RPDU4_B3_SSPC13_16: 8 R_BPCU_BCU
 SG_ RPDU4_B3_SSPC_I_Load_16 : 56|8@1+ (0.1,0) [0|25.5] "A"  JiaShiCang
 SG_ RPDU4_B3_SSPC_TripSta_16 : 54|2@1+ (1,0) [0|3] ""  JiaShiCang
 SG_ RPDU4_B3_SSPC_BitErr_16 : 53|1@1+ (1,0) [0|1] ""  JiaShiCang
 SG_ RPDU4_B3_SSPC_OnOffSta_16 : 52|1@1+ (1,0) [0|1] ""  JiaShiCang
 SG_ RPDU4_B3_SSPC_DianHuErr_16 : 51|1@1+ (1,0) [0|1] ""  JiaShiCang
 SG_ BackUp415 : 48|3@1+ (1,0) [0|0] ""  JiaShiCang
 SG_ RPDU4_B3_SSPC_I_Load_15 : 40|8@1+ (0.1,0) [0|25.5] "A"  JiaShiCang
 SG_ RPDU4_B3_SSPC_TripSta_15 : 38|2@1+ (1,0) [0|3] ""  JiaShiCang
 SG_ RPDU4_B3_SSPC_BitErr_15 : 37|1@1+ (1,0) [0|1] ""  JiaShiCang
 SG_ RPDU4_B3_SSPC_OnOffSta_15 : 36|1@1+ (1,0) [0|1] ""  JiaShiCang
 SG_ RPDU4_B3_SSPC_DianHuErr_15 : 35|1@1+ (1,0) [0|1] ""  JiaShiCang
 SG_ BackUp414 : 32|3@1+ (1,0) [0|0] ""  JiaShiCang
 SG_ RPDU4_B3_SSPC_I_Load_14 : 24|8@1+ (0.1,0) [0|25.5] "A"  JiaShiCang
 SG_ RPDU4_B3_SSPC_TripSta_14 : 22|2@1+ (1,0) [0|3] ""  JiaShiCang
 SG_ RPDU4_B3_SSPC_BitErr_14 : 21|1@1+ (1,0) [0|1] ""  JiaShiCang
 SG_ RPDU4_B3_SSPC_OnOffSta_14 : 20|1@1+ (1,0) [0|1] ""  JiaShiCang
 SG_ RPDU4_B3_SSPC_DianHuErr_14 : 19|1@1+ (1,0) [0|1] ""  JiaShiCang
 SG_ BackUp413 : 16|3@1+ (1,0) [0|0] ""  JiaShiCang
 SG_ RPDU4_B3_SSPC_I_Load_13 : 8|8@1+ (0.1,0) [0|25.5] "A"  JiaShiCang
 SG_ RPDU4_B3_SSPC_TripSta_13 : 6|2@1+ (1,0) [0|3] ""  JiaShiCang
 SG_ RPDU4_B3_SSPC_BitErr_13 : 5|1@1+ (1,0) [0|1] ""  JiaShiCang
 SG_ RPDU4_B3_SSPC_OnOffSta_13 : 4|1@1+ (1,0) [0|1] ""  JiaShiCang
 SG_ RPDU4_B3_SSPC_DianHuErr_13 : 3|1@1+ (1,0) [0|1] ""  JiaShiCang
 SG_ BackUp412 : 0|3@1+ (1,0) [0|0] ""  JiaShiCang

BO_ 2419458080 Msg_R_RPDU4_B3_SSPC09_12: 8 R_BPCU_BCU
 SG_ RPDU4_B3_SSPC_I_Load_12 : 56|8@1+ (0.1,0) [0|25.5] "A"  JiaShiCang
 SG_ RPDU4_B3_SSPC_TripSta_12 : 54|2@1+ (1,0) [0|3] ""  JiaShiCang
 SG_ RPDU4_B3_SSPC_BitErr_12 : 53|1@1+ (1,0) [0|1] ""  JiaShiCang
 SG_ RPDU4_B3_SSPC_OnOffSta_12 : 52|1@1+ (1,0) [0|1] ""  JiaShiCang
 SG_ RPDU4_B3_SSPC_DianHuErr_12 : 51|1@1+ (1,0) [0|1] ""  JiaShiCang
 SG_ BackUp411 : 48|3@1+ (1,0) [0|0] ""  JiaShiCang
 SG_ RPDU4_B3_SSPC_I_Load_11 : 40|8@1+ (0.1,0) [0|25.5] "A"  JiaShiCang
 SG_ RPDU4_B3_SSPC_TripSta_11 : 38|2@1+ (1,0) [0|3] ""  JiaShiCang
 SG_ RPDU4_B3_SSPC_BitErr_11 : 37|1@1+ (1,0) [0|1] ""  JiaShiCang
 SG_ RPDU4_B3_SSPC_OnOffSta_11 : 36|1@1+ (1,0) [0|1] ""  JiaShiCang
 SG_ RPDU4_B3_SSPC_DianHuErr_11 : 35|1@1+ (1,0) [0|1] ""  JiaShiCang
 SG_ BackUp410 : 32|3@1+ (1,0) [0|0] ""  JiaShiCang
 SG_ RPDU4_B3_SSPC_I_Load_10 : 24|8@1+ (0.1,0) [0|25.5] "A"  JiaShiCang
 SG_ RPDU4_B3_SSPC_TripSta_10 : 22|2@1+ (1,0) [0|3] ""  JiaShiCang
 SG_ RPDU4_B3_SSPC_BitErr_10 : 21|1@1+ (1,0) [0|1] ""  JiaShiCang
 SG_ RPDU4_B3_SSPC_OnOffSta_10 : 20|1@1+ (1,0) [0|1] ""  JiaShiCang
 SG_ RPDU4_B3_SSPC_DianHuErr_10 : 19|1@1+ (1,0) [0|1] ""  JiaShiCang
 SG_ BackUp409 : 16|3@1+ (1,0) [0|0] ""  JiaShiCang
 SG_ RPDU4_B3_SSPC_I_Load_09 : 8|8@1+ (0.1,0) [0|25.5] "A"  JiaShiCang
 SG_ RPDU4_B3_SSPC_TripSta_09 : 6|2@1+ (1,0) [0|3] ""  JiaShiCang
 SG_ RPDU4_B3_SSPC_BitErr_09 : 5|1@1+ (1,0) [0|1] ""  JiaShiCang
 SG_ RPDU4_B3_SSPC_OnOffSta_09 : 4|1@1+ (1,0) [0|1] ""  JiaShiCang
 SG_ RPDU4_B3_SSPC_DianHuErr_09 : 3|1@1+ (1,0) [0|1] ""  JiaShiCang
 SG_ BackUp408 : 0|3@1+ (1,0) [0|0] ""  JiaShiCang

BO_ 2419392544 Msg_R_RPDU4_B3_SSPC05_08: 8 R_BPCU_BCU
 SG_ RPDU4_B3_SSPC_I_Load_08 : 56|8@1+ (0.1,0) [0|25.5] "A"  JiaShiCang
 SG_ RPDU4_B3_SSPC_TripSta_08 : 54|2@1+ (1,0) [0|3] ""  JiaShiCang
 SG_ RPDU4_B3_SSPC_BitErr_08 : 53|1@1+ (1,0) [0|1] ""  JiaShiCang
 SG_ RPDU4_B3_SSPC_OnOffSta_08 : 52|1@1+ (1,0) [0|1] ""  JiaShiCang
 SG_ RPDU4_B3_SSPC_DianHuErr_08 : 51|1@1+ (1,0) [0|1] ""  JiaShiCang
 SG_ BackUp407 : 48|3@1+ (1,0) [0|0] ""  JiaShiCang
 SG_ RPDU4_B3_SSPC_I_Load_07 : 40|8@1+ (0.1,0) [0|25.5] "A"  JiaShiCang
 SG_ RPDU4_B3_SSPC_TripSta_07 : 38|2@1+ (1,0) [0|3] ""  JiaShiCang
 SG_ RPDU4_B3_SSPC_BitErr_07 : 37|1@1+ (1,0) [0|1] ""  JiaShiCang
 SG_ RPDU4_B3_SSPC_OnOffSta_07 : 36|1@1+ (1,0) [0|1] ""  JiaShiCang
 SG_ RPDU4_B3_SSPC_DianHuErr_07 : 35|1@1+ (1,0) [0|1] ""  JiaShiCang
 SG_ BackUp406 : 32|3@1+ (1,0) [0|0] ""  JiaShiCang
 SG_ RPDU4_B3_SSPC_I_Load_06 : 24|8@1+ (0.1,0) [0|25.5] "A"  JiaShiCang
 SG_ RPDU4_B3_SSPC_TripSta_06 : 22|2@1+ (1,0) [0|3] ""  JiaShiCang
 SG_ RPDU4_B3_SSPC_BitErr_06 : 21|1@1+ (1,0) [0|1] ""  JiaShiCang
 SG_ RPDU4_B3_SSPC_OnOffSta_06 : 20|1@1+ (1,0) [0|1] ""  JiaShiCang
 SG_ RPDU4_B3_SSPC_DianHuErr_06 : 19|1@1+ (1,0) [0|1] ""  JiaShiCang
 SG_ BackUp405 : 16|3@1+ (1,0) [0|0] ""  JiaShiCang
 SG_ RPDU4_B3_SSPC_I_Load_05 : 8|8@1+ (0.1,0) [0|25.5] "A"  JiaShiCang
 SG_ RPDU4_B3_SSPC_TripSta_05 : 6|2@1+ (1,0) [0|3] ""  JiaShiCang
 SG_ RPDU4_B3_SSPC_BitErr_05 : 5|1@1+ (1,0) [0|1] ""  JiaShiCang
 SG_ RPDU4_B3_SSPC_OnOffSta_05 : 4|1@1+ (1,0) [0|1] ""  JiaShiCang
 SG_ RPDU4_B3_SSPC_DianHuErr_05 : 3|1@1+ (1,0) [0|1] ""  JiaShiCang
 SG_ BackUp404 : 0|3@1+ (1,0) [0|0] ""  JiaShiCang

BO_ 2419327008 Msg_R_RPDU4_B3_SSPC01_04: 8 R_BPCU_BCU
 SG_ RPDU4_B3_SSPC_I_Load_04 : 56|8@1+ (0.1,0) [0|25.5] "A"  JiaShiCang
 SG_ RPDU4_B3_SSPC_TripSta_04 : 54|2@1+ (1,0) [0|3] ""  JiaShiCang
 SG_ RPDU4_B3_SSPC_BitErr_04 : 53|1@1+ (1,0) [0|1] ""  JiaShiCang
 SG_ RPDU4_B3_SSPC_OnOffSta_04 : 52|1@1+ (1,0) [0|1] ""  JiaShiCang
 SG_ RPDU4_B3_SSPC_DianHuErr_04 : 51|1@1+ (1,0) [0|1] ""  JiaShiCang
 SG_ BackUp403 : 48|3@1+ (1,0) [0|0] ""  JiaShiCang
 SG_ RPDU4_B3_SSPC_I_Load_03 : 40|8@1+ (0.1,0) [0|25.5] "A"  JiaShiCang
 SG_ RPDU4_B3_SSPC_TripSta_03 : 38|2@1+ (1,0) [0|3] ""  JiaShiCang
 SG_ RPDU4_B3_SSPC_BitErr_03 : 37|1@1+ (1,0) [0|1] ""  JiaShiCang
 SG_ RPDU4_B3_SSPC_OnOffSta_03 : 36|1@1+ (1,0) [0|1] ""  JiaShiCang
 SG_ RPDU4_B3_SSPC_DianHuErr_03 : 35|1@1+ (1,0) [0|1] ""  JiaShiCang
 SG_ BackUp402 : 32|3@1+ (1,0) [0|0] ""  JiaShiCang
 SG_ RPDU4_B3_SSPC_I_Load_02 : 24|8@1+ (0.1,0) [0|25.5] "A"  JiaShiCang
 SG_ RPDU4_B3_SSPC_TripSta_02 : 22|2@1+ (1,0) [0|3] ""  JiaShiCang
 SG_ RPDU4_B3_SSPC_BitErr_02 : 21|1@1+ (1,0) [0|1] ""  JiaShiCang
 SG_ RPDU4_B3_SSPC_OnOffSta_02 : 20|1@1+ (1,0) [0|1] ""  JiaShiCang
 SG_ RPDU4_B3_SSPC_DianHuErr_02 : 19|1@1+ (1,0) [0|1] ""  JiaShiCang
 SG_ BackUp401 : 16|3@1+ (1,0) [0|0] ""  JiaShiCang
 SG_ RPDU4_B3_SSPC_I_Load_01 : 8|8@1+ (0.1,0) [0|25.5] "A"  JiaShiCang
 SG_ RPDU4_B3_SSPC_TripSta_01 : 6|2@1+ (1,0) [0|3] ""  JiaShiCang
 SG_ RPDU4_B3_SSPC_BitErr_01 : 5|1@1+ (1,0) [0|1] ""  JiaShiCang
 SG_ RPDU4_B3_SSPC_OnOffSta_01 : 4|1@1+ (1,0) [0|1] ""  JiaShiCang
 SG_ RPDU4_B3_SSPC_DianHuErr_01 : 3|1@1+ (1,0) [0|1] ""  JiaShiCang
 SG_ BackUp400 : 0|3@1+ (1,0) [0|0] ""  JiaShiCang

BO_ 2419261472 Msg_R_RPDU4_B2_SSPC17_18: 8 R_BPCU_BCU
 SG_ BackUp399 : 56|8@1+ (1,0) [0|0] ""  JiaShiCang
 SG_ BackUp398 : 48|8@1+ (1,0) [0|0] ""  JiaShiCang
 SG_ BackUp397 : 40|8@1+ (1,0) [0|0] ""  JiaShiCang
 SG_ BackUp396 : 32|8@1+ (1,0) [0|0] ""  JiaShiCang
 SG_ RPDU4_B2_SSPC_I_Load_18 : 24|8@1+ (0.1,0) [0|25.5] "A"  JiaShiCang
 SG_ RPDU4_B2_SSPC_TripSta_18 : 22|2@1+ (1,0) [0|3] ""  JiaShiCang
 SG_ RPDU4_B2_SSPC_BitErr_18 : 21|1@1+ (1,0) [0|1] ""  JiaShiCang
 SG_ RPDU4_B2_SSPC_OnOffSta_18 : 20|1@1+ (1,0) [0|1] ""  JiaShiCang
 SG_ RPDU4_B2_SSPC_DianHuErr_18 : 19|1@1+ (1,0) [0|1] ""  JiaShiCang
 SG_ BackUp395 : 16|3@1+ (1,0) [0|0] ""  JiaShiCang
 SG_ RPDU4_B2_SSPC_I_Load_17 : 8|8@1+ (0.1,0) [0|25.5] "A"  JiaShiCang
 SG_ RPDU4_B2_SSPC_TripSta_17 : 6|2@1+ (1,0) [0|3] ""  JiaShiCang
 SG_ RPDU4_B2_SSPC_BitErr_17 : 5|1@1+ (1,0) [0|1] ""  JiaShiCang
 SG_ RPDU4_B2_SSPC_OnOffSta_17 : 4|1@1+ (1,0) [0|1] ""  JiaShiCang
 SG_ RPDU4_B2_SSPC_DianHuErr_17 : 3|1@1+ (1,0) [0|1] ""  JiaShiCang
 SG_ BackUp394 : 0|3@1+ (1,0) [0|0] ""  JiaShiCang

BO_ 2419195936 Msg_R_RPDU4_B2_SSPC13_16: 8 R_BPCU_BCU
 SG_ RPDU4_B2_SSPC_I_Load_16 : 56|8@1+ (0.1,0) [0|25.5] "A"  JiaShiCang
 SG_ RPDU4_B2_SSPC_TripSta_16 : 54|2@1+ (1,0) [0|3] ""  JiaShiCang
 SG_ RPDU4_B2_SSPC_BitErr_16 : 53|1@1+ (1,0) [0|1] ""  JiaShiCang
 SG_ RPDU4_B2_SSPC_OnOffSta_16 : 52|1@1+ (1,0) [0|1] ""  JiaShiCang
 SG_ RPDU4_B2_SSPC_DianHuErr_16 : 51|1@1+ (1,0) [0|1] ""  JiaShiCang
 SG_ BackUp393 : 48|3@1+ (1,0) [0|0] ""  JiaShiCang
 SG_ RPDU4_B2_SSPC_I_Load_15 : 40|8@1+ (0.1,0) [0|25.5] "A"  JiaShiCang
 SG_ RPDU4_B2_SSPC_TripSta_15 : 38|2@1+ (1,0) [0|3] ""  JiaShiCang
 SG_ RPDU4_B2_SSPC_BitErr_15 : 37|1@1+ (1,0) [0|1] ""  JiaShiCang
 SG_ RPDU4_B2_SSPC_OnOffSta_15 : 36|1@1+ (1,0) [0|1] ""  JiaShiCang
 SG_ RPDU4_B2_SSPC_DianHuErr_15 : 35|1@1+ (1,0) [0|1] ""  JiaShiCang
 SG_ BackUp392 : 32|3@1+ (1,0) [0|0] ""  JiaShiCang
 SG_ RPDU4_B2_SSPC_I_Load_14 : 24|8@1+ (0.1,0) [0|25.5] "A"  JiaShiCang
 SG_ RPDU4_B2_SSPC_TripSta_14 : 22|2@1+ (1,0) [0|3] ""  JiaShiCang
 SG_ RPDU4_B2_SSPC_BitErr_14 : 21|1@1+ (1,0) [0|1] ""  JiaShiCang
 SG_ RPDU4_B2_SSPC_OnOffSta_14 : 20|1@1+ (1,0) [0|1] ""  JiaShiCang
 SG_ RPDU4_B2_SSPC_DianHuErr_14 : 19|1@1+ (1,0) [0|1] ""  JiaShiCang
 SG_ BackUp391 : 16|3@1+ (1,0) [0|0] ""  JiaShiCang
 SG_ RPDU4_B2_SSPC_I_Load_13 : 8|8@1+ (0.1,0) [0|25.5] "A"  JiaShiCang
 SG_ RPDU4_B2_SSPC_TripSta_13 : 6|2@1+ (1,0) [0|3] ""  JiaShiCang
 SG_ RPDU4_B2_SSPC_BitErr_13 : 5|1@1+ (1,0) [0|1] ""  JiaShiCang
 SG_ RPDU4_B2_SSPC_OnOffSta_13 : 4|1@1+ (1,0) [0|1] ""  JiaShiCang
 SG_ RPDU4_B2_SSPC_DianHuErr_13 : 3|1@1+ (1,0) [0|1] ""  JiaShiCang
 SG_ BackUp390 : 0|3@1+ (1,0) [0|0] ""  JiaShiCang

BO_ 2419130400 Msg_R_RPDU4_B2_SSPC09_12: 8 R_BPCU_BCU
 SG_ RPDU4_B2_SSPC_I_Load_12 : 56|8@1+ (0.1,0) [0|25.5] "A"  JiaShiCang
 SG_ RPDU4_B2_SSPC_TripSta_12 : 54|2@1+ (1,0) [0|3] ""  JiaShiCang
 SG_ RPDU4_B2_SSPC_BitErr_12 : 53|1@1+ (1,0) [0|1] ""  JiaShiCang
 SG_ RPDU4_B2_SSPC_OnOffSta_12 : 52|1@1+ (1,0) [0|1] ""  JiaShiCang
 SG_ RPDU4_B2_SSPC_DianHuErr_12 : 51|1@1+ (1,0) [0|1] ""  JiaShiCang
 SG_ BackUp389 : 48|3@1+ (1,0) [0|0] ""  JiaShiCang
 SG_ RPDU4_B2_SSPC_I_Load_11 : 40|8@1+ (0.1,0) [0|25.5] "A"  JiaShiCang
 SG_ RPDU4_B2_SSPC_TripSta_11 : 38|2@1+ (1,0) [0|3] ""  JiaShiCang
 SG_ RPDU4_B2_SSPC_BitErr_11 : 37|1@1+ (1,0) [0|1] ""  JiaShiCang
 SG_ RPDU4_B2_SSPC_OnOffSta_11 : 36|1@1+ (1,0) [0|1] ""  JiaShiCang
 SG_ RPDU4_B2_SSPC_DianHuErr_11 : 35|1@1+ (1,0) [0|1] ""  JiaShiCang
 SG_ BackUp388 : 32|3@1+ (1,0) [0|0] ""  JiaShiCang
 SG_ RPDU4_B2_SSPC_I_Load_10 : 24|8@1+ (0.1,0) [0|25.5] "A"  JiaShiCang
 SG_ RPDU4_B2_SSPC_TripSta_10 : 22|2@1+ (1,0) [0|3] ""  JiaShiCang
 SG_ RPDU4_B2_SSPC_BitErr_10 : 21|1@1+ (1,0) [0|1] ""  JiaShiCang
 SG_ RPDU4_B2_SSPC_OnOffSta_10 : 20|1@1+ (1,0) [0|1] ""  JiaShiCang
 SG_ RPDU4_B2_SSPC_DianHuErr_10 : 19|1@1+ (1,0) [0|1] ""  JiaShiCang
 SG_ BackUp387 : 16|3@1+ (1,0) [0|0] ""  JiaShiCang
 SG_ RPDU4_B2_SSPC_I_Load_09 : 8|8@1+ (0.1,0) [0|25.5] "A"  JiaShiCang
 SG_ RPDU4_B2_SSPC_TripSta_09 : 6|2@1+ (1,0) [0|3] ""  JiaShiCang
 SG_ RPDU4_B2_SSPC_BitErr_09 : 5|1@1+ (1,0) [0|1] ""  JiaShiCang
 SG_ RPDU4_B2_SSPC_OnOffSta_09 : 4|1@1+ (1,0) [0|1] ""  JiaShiCang
 SG_ RPDU4_B2_SSPC_DianHuErr_09 : 3|1@1+ (1,0) [0|1] ""  JiaShiCang
 SG_ BackUp386 : 0|3@1+ (1,0) [0|0] ""  JiaShiCang

BO_ 2419064864 Msg_R_RPDU4_B2_SSPC05_08: 8 R_BPCU_BCU
 SG_ RPDU4_B2_SSPC_I_Load_08 : 56|8@1+ (0.1,0) [0|25.5] "A"  JiaShiCang
 SG_ RPDU4_B2_SSPC_TripSta_08 : 54|2@1+ (1,0) [0|3] ""  JiaShiCang
 SG_ RPDU4_B2_SSPC_BitErr_08 : 53|1@1+ (1,0) [0|1] ""  JiaShiCang
 SG_ RPDU4_B2_SSPC_OnOffSta_08 : 52|1@1+ (1,0) [0|1] ""  JiaShiCang
 SG_ RPDU4_B2_SSPC_DianHuErr_08 : 51|1@1+ (1,0) [0|1] ""  JiaShiCang
 SG_ BackUp385 : 48|3@1+ (1,0) [0|0] ""  JiaShiCang
 SG_ RPDU4_B2_SSPC_I_Load_07 : 40|8@1+ (0.1,0) [0|25.5] "A"  JiaShiCang
 SG_ RPDU4_B2_SSPC_TripSta_07 : 38|2@1+ (1,0) [0|3] ""  JiaShiCang
 SG_ RPDU4_B2_SSPC_BitErr_07 : 37|1@1+ (1,0) [0|1] ""  JiaShiCang
 SG_ RPDU4_B2_SSPC_OnOffSta_07 : 36|1@1+ (1,0) [0|1] ""  JiaShiCang
 SG_ RPDU4_B2_SSPC_DianHuErr_07 : 35|1@1+ (1,0) [0|1] ""  JiaShiCang
 SG_ BackUp384 : 32|3@1+ (1,0) [0|0] ""  JiaShiCang
 SG_ RPDU4_B2_SSPC_I_Load_06 : 24|8@1+ (0.1,0) [0|25.5] "A"  JiaShiCang
 SG_ RPDU4_B2_SSPC_TripSta_06 : 22|2@1+ (1,0) [0|3] ""  JiaShiCang
 SG_ RPDU4_B2_SSPC_BitErr_06 : 21|1@1+ (1,0) [0|1] ""  JiaShiCang
 SG_ RPDU4_B2_SSPC_OnOffSta_06 : 20|1@1+ (1,0) [0|1] ""  JiaShiCang
 SG_ RPDU4_B2_SSPC_DianHuErr_06 : 19|1@1+ (1,0) [0|1] ""  JiaShiCang
 SG_ BackUp383 : 16|3@1+ (1,0) [0|0] ""  JiaShiCang
 SG_ RPDU4_B2_SSPC_I_Load_05 : 8|8@1+ (0.1,0) [0|25.5] "A"  JiaShiCang
 SG_ RPDU4_B2_SSPC_TripSta_05 : 6|2@1+ (1,0) [0|3] ""  JiaShiCang
 SG_ RPDU4_B2_SSPC_BitErr_05 : 5|1@1+ (1,0) [0|1] ""  JiaShiCang
 SG_ RPDU4_B2_SSPC_OnOffSta_05 : 4|1@1+ (1,0) [0|1] ""  JiaShiCang
 SG_ RPDU4_B2_SSPC_DianHuErr_05 : 3|1@1+ (1,0) [0|1] ""  JiaShiCang
 SG_ BackUp382 : 0|3@1+ (1,0) [0|0] ""  JiaShiCang

BO_ 2418999328 Msg_R_RPDU4_B2_SSPC01_04: 8 R_BPCU_BCU
 SG_ RPDU4_B2_SSPC_I_Load_04 : 56|8@1+ (0.1,0) [0|25.5] "A"  JiaShiCang
 SG_ RPDU4_B2_SSPC_TripSta_04 : 54|2@1+ (1,0) [0|3] ""  JiaShiCang
 SG_ RPDU4_B2_SSPC_BitErr_04 : 53|1@1+ (1,0) [0|1] ""  JiaShiCang
 SG_ RPDU4_B2_SSPC_OnOffSta_04 : 52|1@1+ (1,0) [0|1] ""  JiaShiCang
 SG_ RPDU4_B2_SSPC_DianHuErr_04 : 51|1@1+ (1,0) [0|1] ""  JiaShiCang
 SG_ BackUp381 : 48|3@1+ (1,0) [0|0] ""  JiaShiCang
 SG_ RPDU4_B2_SSPC_I_Load_03 : 40|8@1+ (0.1,0) [0|25.5] "A"  JiaShiCang
 SG_ RPDU4_B2_SSPC_TripSta_03 : 38|2@1+ (1,0) [0|3] ""  JiaShiCang
 SG_ RPDU4_B2_SSPC_BitErr_03 : 37|1@1+ (1,0) [0|1] ""  JiaShiCang
 SG_ RPDU4_B2_SSPC_OnOffSta_03 : 36|1@1+ (1,0) [0|1] ""  JiaShiCang
 SG_ RPDU4_B2_SSPC_DianHuErr_03 : 35|1@1+ (1,0) [0|1] ""  JiaShiCang
 SG_ BackUp380 : 32|3@1+ (1,0) [0|0] ""  JiaShiCang
 SG_ RPDU4_B2_SSPC_I_Load_02 : 24|8@1+ (0.1,0) [0|25.5] "A"  JiaShiCang
 SG_ RPDU4_B2_SSPC_TripSta_02 : 22|2@1+ (1,0) [0|3] ""  JiaShiCang
 SG_ RPDU4_B2_SSPC_BitErr_02 : 21|1@1+ (1,0) [0|1] ""  JiaShiCang
 SG_ RPDU4_B2_SSPC_OnOffSta_02 : 20|1@1+ (1,0) [0|1] ""  JiaShiCang
 SG_ RPDU4_B2_SSPC_DianHuErr_02 : 19|1@1+ (1,0) [0|1] ""  JiaShiCang
 SG_ BackUp379 : 16|3@1+ (1,0) [0|0] ""  JiaShiCang
 SG_ RPDU4_B2_SSPC_I_Load_01 : 8|8@1+ (0.1,0) [0|25.5] "A"  JiaShiCang
 SG_ RPDU4_B2_SSPC_TripSta_01 : 6|2@1+ (1,0) [0|3] ""  JiaShiCang
 SG_ RPDU4_B2_SSPC_BitErr_01 : 5|1@1+ (1,0) [0|1] ""  JiaShiCang
 SG_ RPDU4_B2_SSPC_OnOffSta_01 : 4|1@1+ (1,0) [0|1] ""  JiaShiCang
 SG_ RPDU4_B2_SSPC_DianHuErr_01 : 3|1@1+ (1,0) [0|1] ""  JiaShiCang
 SG_ BackUp378 : 0|3@1+ (1,0) [0|0] ""  JiaShiCang

CM_ SG_ 2416254976 LED_JiZhong_24 "灯集中控制信号
1：灯亮（接通）， 0：灯灭（断开）";
CM_ SG_ 2416254976 BackUp536 "预留";
CM_ SG_ 2416254976 BackUp534 "预留";
CM_ SG_ 2416254976 SSPC_Reset_R "指定SSPC的负载复位命令";
CM_ SG_ 2416254976 SSPC_Num_R "SSPC编号";
CM_ SG_ 2416254976 Board_Num_R "板卡编号";
CM_ SG_ 2416254976 RPDU_Num_R "RPDU编号";
CM_ SG_ 2416189440 BackUp533 "预留";
CM_ SG_ 2416189440 BackUp532 "预留";
CM_ SG_ 2416189440 RPDU4_B6_SSPC_Order_07 "6号板卡—SSPC7通断控制命令";
CM_ SG_ 2416189440 RPDU4_B6_SSPC_Order_06 "6号板卡—SSPC6通断控制命令";
CM_ SG_ 2416189440 RPDU4_B6_SSPC_Order_05 "6号板卡—SSPC5通断控制命令";
CM_ SG_ 2416189440 RPDU4_B6_SSPC_Order_04 "6号板卡—SSPC4通断控制命令";
CM_ SG_ 2416189440 RPDU4_B6_SSPC_Order_03 "6号板卡—SSPC3通断控制命令";
CM_ SG_ 2416189440 RPDU4_B6_SSPC_Order_02 "6号板卡—SSPC2通断控制命令";
CM_ SG_ 2416189440 RPDU4_B6_SSPC_Order_01 "6号板卡—SSPC1通断控制命令";
CM_ SG_ 2416189440 BackUp531 "预留";
CM_ SG_ 2416189440 RPDU4_B4_SSPC_Order_18 "4号板卡—SSPC18通断控制命令";
CM_ SG_ 2416189440 RPDU4_B4_SSPC_Order_17 "4号板卡—SSPC17通断控制命令";
CM_ SG_ 2416189440 RPDU4_B4_SSPC_Order_16 "4号板卡—SSPC16通断控制命令";
CM_ SG_ 2416189440 RPDU4_B4_SSPC_Order_15 "4号板卡—SSPC15通断控制命令";
CM_ SG_ 2416189440 RPDU4_B4_SSPC_Order_14 "4号板卡—SSPC14通断控制命令";
CM_ SG_ 2416189440 RPDU4_B4_SSPC_Order_13 "4号板卡—SSPC13通断控制命令";
CM_ SG_ 2416189440 RPDU4_B4_SSPC_Order_12 "4号板卡—SSPC12通断控制命令";
CM_ SG_ 2416189440 RPDU4_B4_SSPC_Order_11 "4号板卡—SSPC11通断控制命令";
CM_ SG_ 2416189440 RPDU4_B4_SSPC_Order_10 "4号板卡—SSPC10通断控制命令";
CM_ SG_ 2416189440 RPDU4_B4_SSPC_Order_09 "4号板卡—SSPC9通断控制命令";
CM_ SG_ 2416189440 RPDU4_B4_SSPC_Order_08 "4号板卡—SSPC8通断控制命令";
CM_ SG_ 2416189440 RPDU4_B4_SSPC_Order_07 "4号板卡—SSPC7通断控制命令";
CM_ SG_ 2416189440 RPDU4_B4_SSPC_Order_06 "4号板卡—SSPC6通断控制命令";
CM_ SG_ 2416189440 RPDU4_B4_SSPC_Order_05 "4号板卡—SSPC5通断控制命令";
CM_ SG_ 2416189440 RPDU4_B4_SSPC_Order_04 "4号板卡—SSPC4通断控制命令";
CM_ SG_ 2416189440 RPDU4_B4_SSPC_Order_03 "4号板卡—SSPC3通断控制命令";
CM_ SG_ 2416189440 RPDU4_B4_SSPC_Order_02 "4号板卡—SSPC2通断控制命令";
CM_ SG_ 2416189440 RPDU4_B4_SSPC_Order_01 "4号板卡—SSPC1通断控制命令";
CM_ SG_ 2416189440 BackUp530 "预留";
CM_ SG_ 2416189440 RPDU4_B2_SSPC_Order_18 "2号板卡—SSPC18通断控制命令";
CM_ SG_ 2416189440 RPDU4_B2_SSPC_Order_17 "2号板卡—SSPC17通断控制命令";
CM_ SG_ 2416189440 RPDU4_B2_SSPC_Order_16 "2号板卡—SSPC16通断控制命令";
CM_ SG_ 2416189440 RPDU4_B2_SSPC_Order_15 "2号板卡—SSPC15通断控制命令";
CM_ SG_ 2416189440 RPDU4_B2_SSPC_Order_14 "2号板卡—SSPC14通断控制命令";
CM_ SG_ 2416189440 RPDU4_B2_SSPC_Order_13 "2号板卡—SSPC13通断控制命令";
CM_ SG_ 2416189440 RPDU4_B2_SSPC_Order_12 "2号板卡—SSPC12通断控制命令";
CM_ SG_ 2416189440 RPDU4_B2_SSPC_Order_11 "2号板卡—SSPC11通断控制命令";
CM_ SG_ 2416189440 RPDU4_B2_SSPC_Order_10 "2号板卡—SSPC10通断控制命令";
CM_ SG_ 2416189440 RPDU4_B2_SSPC_Order_09 "2号板卡—SSPC9通断控制命令";
CM_ SG_ 2416189440 RPDU4_B2_SSPC_Order_08 "2号板卡—SSPC8通断控制命令";
CM_ SG_ 2416189440 RPDU4_B2_SSPC_Order_07 "2号板卡—SSPC7通断控制命令";
CM_ SG_ 2416189440 RPDU4_B2_SSPC_Order_06 "2号板卡—SSPC6通断控制命令";
CM_ SG_ 2416189440 RPDU4_B2_SSPC_Order_05 "2号板卡—SSPC5通断控制命令";
CM_ SG_ 2416189440 RPDU4_B2_SSPC_Order_04 "2号板卡—SSPC4通断控制命令";
CM_ SG_ 2416189440 RPDU4_B2_SSPC_Order_03 "2号板卡—SSPC3通断控制命令";
CM_ SG_ 2416189440 RPDU4_B2_SSPC_Order_02 "2号板卡—SSPC2通断控制命令";
CM_ SG_ 2416189440 RPDU4_B2_SSPC_Order_01 "2号板卡—SSPC1通断控制命令";
CM_ SG_ 2416123904 BackUp529 "预留";
CM_ SG_ 2416123904 BackUp528 "预留";
CM_ SG_ 2416123904 RPDU4_B5_SSPC_Order_07 "5号板卡—SSPC7通断控制命令";
CM_ SG_ 2416123904 RPDU4_B5_SSPC_Order_06 "5号板卡—SSPC6通断控制命令";
CM_ SG_ 2416123904 RPDU4_B5_SSPC_Order_05 "5号板卡—SSPC5通断控制命令";
CM_ SG_ 2416123904 RPDU4_B5_SSPC_Order_04 "5号板卡—SSPC4通断控制命令";
CM_ SG_ 2416123904 RPDU4_B5_SSPC_Order_03 "5号板卡—SSPC3通断控制命令";
CM_ SG_ 2416123904 RPDU4_B5_SSPC_Order_02 "5号板卡—SSPC2通断控制命令";
CM_ SG_ 2416123904 RPDU4_B5_SSPC_Order_01 "5号板卡—SSPC1通断控制命令";
CM_ SG_ 2416123904 BackUp527 "预留";
CM_ SG_ 2416123904 RPDU4_B3_SSPC_Order_18 "3号板卡—SSPC18通断控制命令";
CM_ SG_ 2416123904 RPDU4_B3_SSPC_Order_17 "3号板卡—SSPC17通断控制命令";
CM_ SG_ 2416123904 RPDU4_B3_SSPC_Order_16 "3号板卡—SSPC16通断控制命令";
CM_ SG_ 2416123904 RPDU4_B3_SSPC_Order_15 "3号板卡—SSPC15通断控制命令";
CM_ SG_ 2416123904 RPDU4_B3_SSPC_Order_14 "3号板卡—SSPC14通断控制命令";
CM_ SG_ 2416123904 RPDU4_B3_SSPC_Order_13 "3号板卡—SSPC13通断控制命令";
CM_ SG_ 2416123904 RPDU4_B3_SSPC_Order_12 "3号板卡—SSPC12通断控制命令";
CM_ SG_ 2416123904 RPDU4_B3_SSPC_Order_11 "3号板卡—SSPC11通断控制命令";
CM_ SG_ 2416123904 RPDU4_B3_SSPC_Order_10 "3号板卡—SSPC10通断控制命令";
CM_ SG_ 2416123904 RPDU4_B3_SSPC_Order_09 "3号板卡—SSPC9通断控制命令";
CM_ SG_ 2416123904 RPDU4_B3_SSPC_Order_08 "3号板卡—SSPC8通断控制命令";
CM_ SG_ 2416123904 RPDU4_B3_SSPC_Order_07 "3号板卡—SSPC7通断控制命令";
CM_ SG_ 2416123904 RPDU4_B3_SSPC_Order_06 "3号板卡—SSPC6通断控制命令";
CM_ SG_ 2416123904 RPDU4_B3_SSPC_Order_05 "3号板卡—SSPC5通断控制命令";
CM_ SG_ 2416123904 RPDU4_B3_SSPC_Order_04 "3号板卡—SSPC4通断控制命令";
CM_ SG_ 2416123904 RPDU4_B3_SSPC_Order_03 "3号板卡—SSPC3通断控制命令";
CM_ SG_ 2416123904 RPDU4_B3_SSPC_Order_02 "3号板卡—SSPC2通断控制命令";
CM_ SG_ 2416123904 RPDU4_B3_SSPC_Order_01 "3号板卡—SSPC1通断控制命令";
CM_ SG_ 2416123904 BackUp526 "预留";
CM_ SG_ 2416123904 RPDU4_B1_SSPC_Order_18 "1号板卡—SSPC18通断控制命令";
CM_ SG_ 2416123904 RPDU4_B1_SSPC_Order_17 "1号板卡—SSPC17通断控制命令";
CM_ SG_ 2416123904 RPDU4_B1_SSPC_Order_16 "1号板卡—SSPC16通断控制命令";
CM_ SG_ 2416123904 RPDU4_B1_SSPC_Order_15 "1号板卡—SSPC15通断控制命令";
CM_ SG_ 2416123904 RPDU4_B1_SSPC_Order_14 "1号板卡—SSPC14通断控制命令";
CM_ SG_ 2416123904 RPDU4_B1_SSPC_Order_13 "1号板卡—SSPC13通断控制命令";
CM_ SG_ 2416123904 RPDU4_B1_SSPC_Order_12 "1号板卡—SSPC12通断控制命令";
CM_ SG_ 2416123904 RPDU4_B1_SSPC_Order_11 "1号板卡—SSPC11通断控制命令";
CM_ SG_ 2416123904 RPDU4_B1_SSPC_Order_10 "1号板卡—SSPC10通断控制命令";
CM_ SG_ 2416123904 RPDU4_B1_SSPC_Order_09 "1号板卡—SSPC9通断控制命令";
CM_ SG_ 2416123904 RPDU4_B1_SSPC_Order_08 "1号板卡—SSPC8通断控制命令";
CM_ SG_ 2416123904 RPDU4_B1_SSPC_Order_07 "1号板卡—SSPC7通断控制命令";
CM_ SG_ 2416123904 RPDU4_B1_SSPC_Order_06 "1号板卡—SSPC6通断控制命令";
CM_ SG_ 2416123904 RPDU4_B1_SSPC_Order_05 "1号板卡—SSPC5通断控制命令";
CM_ SG_ 2416123904 RPDU4_B1_SSPC_Order_04 "1号板卡—SSPC4通断控制命令";
CM_ SG_ 2416123904 RPDU4_B1_SSPC_Order_03 "1号板卡—SSPC3通断控制命令";
CM_ SG_ 2416123904 RPDU4_B1_SSPC_Order_02 "1号板卡—SSPC2通断控制命令";
CM_ SG_ 2416123904 RPDU4_B1_SSPC_Order_01 "1号板卡—SSPC1通断控制命令";
CM_ SG_ 2416058368 BackUp525 "预留";
CM_ SG_ 2416058368 BackUp524 "预留";
CM_ SG_ 2416058368 RPDU2_B6_SSPC_Order_07 "6号板卡—SSPC7通断控制命令";
CM_ SG_ 2416058368 RPDU2_B6_SSPC_Order_06 "6号板卡—SSPC6通断控制命令";
CM_ SG_ 2416058368 RPDU2_B6_SSPC_Order_05 "6号板卡—SSPC5通断控制命令";
CM_ SG_ 2416058368 RPDU2_B6_SSPC_Order_04 "6号板卡—SSPC4通断控制命令";
CM_ SG_ 2416058368 RPDU2_B6_SSPC_Order_03 "6号板卡—SSPC3通断控制命令";
CM_ SG_ 2416058368 RPDU2_B6_SSPC_Order_02 "6号板卡—SSPC2通断控制命令";
CM_ SG_ 2416058368 RPDU2_B6_SSPC_Order_01 "6号板卡—SSPC1通断控制命令";
CM_ SG_ 2416058368 BackUp523 "预留";
CM_ SG_ 2416058368 RPDU2_B4_SSPC_Order_18 "4号板卡—SSPC18通断控制命令";
CM_ SG_ 2416058368 RPDU2_B4_SSPC_Order_17 "4号板卡—SSPC17通断控制命令";
CM_ SG_ 2416058368 RPDU2_B4_SSPC_Order_16 "4号板卡—SSPC16通断控制命令";
CM_ SG_ 2416058368 RPDU2_B4_SSPC_Order_15 "4号板卡—SSPC15通断控制命令";
CM_ SG_ 2416058368 RPDU2_B4_SSPC_Order_14 "4号板卡—SSPC14通断控制命令";
CM_ SG_ 2416058368 RPDU2_B4_SSPC_Order_13 "4号板卡—SSPC13通断控制命令";
CM_ SG_ 2416058368 RPDU2_B4_SSPC_Order_12 "4号板卡—SSPC12通断控制命令";
CM_ SG_ 2416058368 RPDU2_B4_SSPC_Order_11 "4号板卡—SSPC11通断控制命令";
CM_ SG_ 2416058368 RPDU2_B4_SSPC_Order_10 "4号板卡—SSPC10通断控制命令";
CM_ SG_ 2416058368 RPDU2_B4_SSPC_Order_09 "4号板卡—SSPC9通断控制命令";
CM_ SG_ 2416058368 RPDU2_B4_SSPC_Order_08 "4号板卡—SSPC8通断控制命令";
CM_ SG_ 2416058368 RPDU2_B4_SSPC_Order_07 "4号板卡—SSPC7通断控制命令";
CM_ SG_ 2416058368 RPDU2_B4_SSPC_Order_06 "4号板卡—SSPC6通断控制命令";
CM_ SG_ 2416058368 RPDU2_B4_SSPC_Order_05 "4号板卡—SSPC5通断控制命令";
CM_ SG_ 2416058368 RPDU2_B4_SSPC_Order_04 "4号板卡—SSPC4通断控制命令";
CM_ SG_ 2416058368 RPDU2_B4_SSPC_Order_03 "4号板卡—SSPC3通断控制命令";
CM_ SG_ 2416058368 RPDU2_B4_SSPC_Order_02 "4号板卡—SSPC2通断控制命令";
CM_ SG_ 2416058368 RPDU2_B4_SSPC_Order_01 "4号板卡—SSPC1通断控制命令";
CM_ SG_ 2416058368 BackUp522 "预留";
CM_ SG_ 2416058368 RPDU2_B2_SSPC_Order_18 "2号板卡—SSPC18通断控制命令";
CM_ SG_ 2416058368 RPDU2_B2_SSPC_Order_17 "2号板卡—SSPC17通断控制命令";
CM_ SG_ 2416058368 RPDU2_B2_SSPC_Order_16 "2号板卡—SSPC16通断控制命令";
CM_ SG_ 2416058368 RPDU2_B2_SSPC_Order_15 "2号板卡—SSPC15通断控制命令";
CM_ SG_ 2416058368 RPDU2_B2_SSPC_Order_14 "2号板卡—SSPC14通断控制命令";
CM_ SG_ 2416058368 RPDU2_B2_SSPC_Order_13 "2号板卡—SSPC13通断控制命令";
CM_ SG_ 2416058368 RPDU2_B2_SSPC_Order_12 "2号板卡—SSPC12通断控制命令";
CM_ SG_ 2416058368 RPDU2_B2_SSPC_Order_11 "2号板卡—SSPC11通断控制命令";
CM_ SG_ 2416058368 RPDU2_B2_SSPC_Order_10 "2号板卡—SSPC10通断控制命令";
CM_ SG_ 2416058368 RPDU2_B2_SSPC_Order_09 "2号板卡—SSPC9通断控制命令";
CM_ SG_ 2416058368 RPDU2_B2_SSPC_Order_08 "2号板卡—SSPC8通断控制命令";
CM_ SG_ 2416058368 RPDU2_B2_SSPC_Order_07 "2号板卡—SSPC7通断控制命令";
CM_ SG_ 2416058368 RPDU2_B2_SSPC_Order_06 "2号板卡—SSPC6通断控制命令";
CM_ SG_ 2416058368 RPDU2_B2_SSPC_Order_05 "2号板卡—SSPC5通断控制命令";
CM_ SG_ 2416058368 RPDU2_B2_SSPC_Order_04 "2号板卡—SSPC4通断控制命令";
CM_ SG_ 2416058368 RPDU2_B2_SSPC_Order_03 "2号板卡—SSPC3通断控制命令";
CM_ SG_ 2416058368 RPDU2_B2_SSPC_Order_02 "2号板卡—SSPC2通断控制命令";
CM_ SG_ 2416058368 RPDU2_B2_SSPC_Order_01 "2号板卡—SSPC1通断控制命令";
CM_ SG_ 2415992832 BackUp521 "预留";
CM_ SG_ 2415992832 BackUp520 "预留";
CM_ SG_ 2415992832 RPDU2_B5_SSPC_Order_07 "5号板卡—SSPC7通断控制命令";
CM_ SG_ 2415992832 RPDU2_B5_SSPC_Order_06 "5号板卡—SSPC6通断控制命令";
CM_ SG_ 2415992832 RPDU2_B5_SSPC_Order_05 "5号板卡—SSPC5通断控制命令";
CM_ SG_ 2415992832 RPDU2_B5_SSPC_Order_04 "5号板卡—SSPC4通断控制命令";
CM_ SG_ 2415992832 RPDU2_B5_SSPC_Order_03 "5号板卡—SSPC3通断控制命令";
CM_ SG_ 2415992832 RPDU2_B5_SSPC_Order_02 "5号板卡—SSPC2通断控制命令";
CM_ SG_ 2415992832 RPDU2_B5_SSPC_Order_01 "5号板卡—SSPC1通断控制命令";
CM_ SG_ 2415992832 BackUp519 "预留";
CM_ SG_ 2415992832 RPDU2_B3_SSPC_Order_18 "3号板卡—SSPC18通断控制命令";
CM_ SG_ 2415992832 RPDU2_B3_SSPC_Order_17 "3号板卡—SSPC17通断控制命令";
CM_ SG_ 2415992832 RPDU2_B3_SSPC_Order_16 "3号板卡—SSPC16通断控制命令";
CM_ SG_ 2415992832 RPDU2_B3_SSPC_Order_15 "3号板卡—SSPC15通断控制命令";
CM_ SG_ 2415992832 RPDU2_B3_SSPC_Order_14 "3号板卡—SSPC14通断控制命令";
CM_ SG_ 2415992832 RPDU2_B3_SSPC_Order_13 "3号板卡—SSPC13通断控制命令";
CM_ SG_ 2415992832 RPDU2_B3_SSPC_Order_12 "3号板卡—SSPC12通断控制命令";
CM_ SG_ 2415992832 RPDU2_B3_SSPC_Order_11 "3号板卡—SSPC11通断控制命令";
CM_ SG_ 2415992832 RPDU2_B3_SSPC_Order_10 "3号板卡—SSPC10通断控制命令";
CM_ SG_ 2415992832 RPDU2_B3_SSPC_Order_09 "3号板卡—SSPC9通断控制命令";
CM_ SG_ 2415992832 RPDU2_B3_SSPC_Order_08 "3号板卡—SSPC8通断控制命令";
CM_ SG_ 2415992832 RPDU2_B3_SSPC_Order_07 "3号板卡—SSPC7通断控制命令";
CM_ SG_ 2415992832 RPDU2_B3_SSPC_Order_06 "3号板卡—SSPC6通断控制命令";
CM_ SG_ 2415992832 RPDU2_B3_SSPC_Order_05 "3号板卡—SSPC5通断控制命令";
CM_ SG_ 2415992832 RPDU2_B3_SSPC_Order_04 "3号板卡—SSPC4通断控制命令";
CM_ SG_ 2415992832 RPDU2_B3_SSPC_Order_03 "3号板卡—SSPC3通断控制命令";
CM_ SG_ 2415992832 RPDU2_B3_SSPC_Order_02 "3号板卡—SSPC2通断控制命令";
CM_ SG_ 2415992832 RPDU2_B3_SSPC_Order_01 "3号板卡—SSPC1通断控制命令";
CM_ SG_ 2415992832 BackUp518 "预留";
CM_ SG_ 2415992832 RPDU2_B1_SSPC_Order_18 "1号板卡—SSPC18通断控制命令";
CM_ SG_ 2415992832 RPDU2_B1_SSPC_Order_17 "1号板卡—SSPC17通断控制命令";
CM_ SG_ 2415992832 RPDU2_B1_SSPC_Order_16 "1号板卡—SSPC16通断控制命令";
CM_ SG_ 2415992832 RPDU2_B1_SSPC_Order_15 "1号板卡—SSPC15通断控制命令";
CM_ SG_ 2415992832 RPDU2_B1_SSPC_Order_14 "1号板卡—SSPC14通断控制命令";
CM_ SG_ 2415992832 RPDU2_B1_SSPC_Order_13 "1号板卡—SSPC13通断控制命令";
CM_ SG_ 2415992832 RPDU2_B1_SSPC_Order_12 "1号板卡—SSPC12通断控制命令";
CM_ SG_ 2415992832 RPDU2_B1_SSPC_Order_11 "1号板卡—SSPC11通断控制命令";
CM_ SG_ 2415992832 RPDU2_B1_SSPC_Order_10 "1号板卡—SSPC10通断控制命令";
CM_ SG_ 2415992832 RPDU2_B1_SSPC_Order_09 "1号板卡—SSPC9通断控制命令";
CM_ SG_ 2415992832 RPDU2_B1_SSPC_Order_08 "1号板卡—SSPC8通断控制命令";
CM_ SG_ 2415992832 RPDU2_B1_SSPC_Order_07 "1号板卡—SSPC7通断控制命令";
CM_ SG_ 2415992832 RPDU2_B1_SSPC_Order_06 "1号板卡—SSPC6通断控制命令";
CM_ SG_ 2415992832 RPDU2_B1_SSPC_Order_05 "1号板卡—SSPC5通断控制命令";
CM_ SG_ 2415992832 RPDU2_B1_SSPC_Order_04 "1号板卡—SSPC4通断控制命令";
CM_ SG_ 2415992832 RPDU2_B1_SSPC_Order_03 "1号板卡—SSPC3通断控制命令";
CM_ SG_ 2415992832 RPDU2_B1_SSPC_Order_02 "1号板卡—SSPC2通断控制命令";
CM_ SG_ 2415992832 RPDU2_B1_SSPC_Order_01 "1号板卡—SSPC1通断控制命令";
CM_ SG_ 2416250880 LED_JiZhong_13 "灯集中控制信号
1：灯亮（接通）， 0：灯灭（断开）";
CM_ SG_ 2416250880 BackUp535 "预留";
CM_ SG_ 2416250880 BackUp517 "预留";
CM_ SG_ 2416250880 SSPC_Reset_L "指定SSPC的负载复位命令";
CM_ SG_ 2416250880 SSPC_Num_L "SSPC编号";
CM_ SG_ 2416250880 Board_Num_L "板卡编号";
CM_ SG_ 2416250880 RPDU_Num_L "RPDU编号";
CM_ SG_ 2416185344 BackUp516 "预留";
CM_ SG_ 2416185344 BackUp515 "预留";
CM_ SG_ 2416185344 RPDU3_B6_SSPC_Order_07 "6号板卡—SSPC7通断控制命令";
CM_ SG_ 2416185344 RPDU3_B6_SSPC_Order_06 "6号板卡—SSPC6通断控制命令";
CM_ SG_ 2416185344 RPDU3_B6_SSPC_Order_05 "6号板卡—SSPC5通断控制命令";
CM_ SG_ 2416185344 RPDU3_B6_SSPC_Order_04 "6号板卡—SSPC4通断控制命令";
CM_ SG_ 2416185344 RPDU3_B6_SSPC_Order_03 "6号板卡—SSPC3通断控制命令";
CM_ SG_ 2416185344 RPDU3_B6_SSPC_Order_02 "6号板卡—SSPC2通断控制命令";
CM_ SG_ 2416185344 RPDU3_B6_SSPC_Order_01 "6号板卡—SSPC1通断控制命令";
CM_ SG_ 2416185344 BackUp514 "预留";
CM_ SG_ 2416185344 RPDU3_B4_SSPC_Order_18 "4号板卡—SSPC18通断控制命令";
CM_ SG_ 2416185344 RPDU3_B4_SSPC_Order_17 "4号板卡—SSPC17通断控制命令";
CM_ SG_ 2416185344 RPDU3_B4_SSPC_Order_16 "4号板卡—SSPC16通断控制命令";
CM_ SG_ 2416185344 RPDU3_B4_SSPC_Order_15 "4号板卡—SSPC15通断控制命令";
CM_ SG_ 2416185344 RPDU3_B4_SSPC_Order_14 "4号板卡—SSPC14通断控制命令";
CM_ SG_ 2416185344 RPDU3_B4_SSPC_Order_13 "4号板卡—SSPC13通断控制命令";
CM_ SG_ 2416185344 RPDU3_B4_SSPC_Order_12 "4号板卡—SSPC12通断控制命令";
CM_ SG_ 2416185344 RPDU3_B4_SSPC_Order_11 "4号板卡—SSPC11通断控制命令";
CM_ SG_ 2416185344 RPDU3_B4_SSPC_Order_10 "4号板卡—SSPC10通断控制命令";
CM_ SG_ 2416185344 RPDU3_B4_SSPC_Order_09 "4号板卡—SSPC9通断控制命令";
CM_ SG_ 2416185344 RPDU3_B4_SSPC_Order_08 "4号板卡—SSPC8通断控制命令";
CM_ SG_ 2416185344 RPDU3_B4_SSPC_Order_07 "4号板卡—SSPC7通断控制命令";
CM_ SG_ 2416185344 RPDU3_B4_SSPC_Order_06 "4号板卡—SSPC6通断控制命令";
CM_ SG_ 2416185344 RPDU3_B4_SSPC_Order_05 "4号板卡—SSPC5通断控制命令";
CM_ SG_ 2416185344 RPDU3_B4_SSPC_Order_04 "4号板卡—SSPC4通断控制命令";
CM_ SG_ 2416185344 RPDU3_B4_SSPC_Order_03 "4号板卡—SSPC3通断控制命令";
CM_ SG_ 2416185344 RPDU3_B4_SSPC_Order_02 "4号板卡—SSPC2通断控制命令";
CM_ SG_ 2416185344 RPDU3_B4_SSPC_Order_01 "4号板卡—SSPC1通断控制命令";
CM_ SG_ 2416185344 BackUp513 "预留";
CM_ SG_ 2416185344 RPDU3_B2_SSPC_Order_18 "2号板卡—SSPC18通断控制命令";
CM_ SG_ 2416185344 RPDU3_B2_SSPC_Order_17 "2号板卡—SSPC17通断控制命令";
CM_ SG_ 2416185344 RPDU3_B2_SSPC_Order_16 "2号板卡—SSPC16通断控制命令";
CM_ SG_ 2416185344 RPDU3_B2_SSPC_Order_15 "2号板卡—SSPC15通断控制命令";
CM_ SG_ 2416185344 RPDU3_B2_SSPC_Order_14 "2号板卡—SSPC14通断控制命令";
CM_ SG_ 2416185344 RPDU3_B2_SSPC_Order_13 "2号板卡—SSPC13通断控制命令";
CM_ SG_ 2416185344 RPDU3_B2_SSPC_Order_12 "2号板卡—SSPC12通断控制命令";
CM_ SG_ 2416185344 RPDU3_B2_SSPC_Order_11 "2号板卡—SSPC11通断控制命令";
CM_ SG_ 2416185344 RPDU3_B2_SSPC_Order_10 "2号板卡—SSPC10通断控制命令";
CM_ SG_ 2416185344 RPDU3_B2_SSPC_Order_09 "2号板卡—SSPC9通断控制命令";
CM_ SG_ 2416185344 RPDU3_B2_SSPC_Order_08 "2号板卡—SSPC8通断控制命令";
CM_ SG_ 2416185344 RPDU3_B2_SSPC_Order_07 "2号板卡—SSPC7通断控制命令";
CM_ SG_ 2416185344 RPDU3_B2_SSPC_Order_06 "2号板卡—SSPC6通断控制命令";
CM_ SG_ 2416185344 RPDU3_B2_SSPC_Order_05 "2号板卡—SSPC5通断控制命令";
CM_ SG_ 2416185344 RPDU3_B2_SSPC_Order_04 "2号板卡—SSPC4通断控制命令";
CM_ SG_ 2416185344 RPDU3_B2_SSPC_Order_03 "2号板卡—SSPC3通断控制命令";
CM_ SG_ 2416185344 RPDU3_B2_SSPC_Order_02 "2号板卡—SSPC2通断控制命令";
CM_ SG_ 2416185344 RPDU3_B2_SSPC_Order_01 "2号板卡—SSPC1通断控制命令";
CM_ SG_ 2416119808 BackUp512 "预留";
CM_ SG_ 2416119808 BackUp511 "预留";
CM_ SG_ 2416119808 RPDU3_B5_SSPC_Order_07 "5号板卡—SSPC7通断控制命令";
CM_ SG_ 2416119808 RPDU3_B5_SSPC_Order_06 "5号板卡—SSPC6通断控制命令";
CM_ SG_ 2416119808 RPDU3_B5_SSPC_Order_05 "5号板卡—SSPC5通断控制命令";
CM_ SG_ 2416119808 RPDU3_B5_SSPC_Order_04 "5号板卡—SSPC4通断控制命令";
CM_ SG_ 2416119808 RPDU3_B5_SSPC_Order_03 "5号板卡—SSPC3通断控制命令";
CM_ SG_ 2416119808 RPDU3_B5_SSPC_Order_02 "5号板卡—SSPC2通断控制命令";
CM_ SG_ 2416119808 RPDU3_B5_SSPC_Order_01 "5号板卡—SSPC1通断控制命令";
CM_ SG_ 2416119808 BackUp510 "预留";
CM_ SG_ 2416119808 RPDU3_B3_SSPC_Order_18 "3号板卡—SSPC18通断控制命令";
CM_ SG_ 2416119808 RPDU3_B3_SSPC_Order_17 "3号板卡—SSPC17通断控制命令";
CM_ SG_ 2416119808 RPDU3_B3_SSPC_Order_16 "3号板卡—SSPC16通断控制命令";
CM_ SG_ 2416119808 RPDU3_B3_SSPC_Order_15 "3号板卡—SSPC15通断控制命令";
CM_ SG_ 2416119808 RPDU3_B3_SSPC_Order_14 "3号板卡—SSPC14通断控制命令";
CM_ SG_ 2416119808 RPDU3_B3_SSPC_Order_13 "3号板卡—SSPC13通断控制命令";
CM_ SG_ 2416119808 RPDU3_B3_SSPC_Order_12 "3号板卡—SSPC12通断控制命令";
CM_ SG_ 2416119808 RPDU3_B3_SSPC_Order_11 "3号板卡—SSPC11通断控制命令";
CM_ SG_ 2416119808 RPDU3_B3_SSPC_Order_10 "3号板卡—SSPC10通断控制命令";
CM_ SG_ 2416119808 RPDU3_B3_SSPC_Order_09 "3号板卡—SSPC9通断控制命令";
CM_ SG_ 2416119808 RPDU3_B3_SSPC_Order_08 "3号板卡—SSPC8通断控制命令";
CM_ SG_ 2416119808 RPDU3_B3_SSPC_Order_07 "3号板卡—SSPC7通断控制命令";
CM_ SG_ 2416119808 RPDU3_B3_SSPC_Order_06 "3号板卡—SSPC6通断控制命令";
CM_ SG_ 2416119808 RPDU3_B3_SSPC_Order_05 "3号板卡—SSPC5通断控制命令";
CM_ SG_ 2416119808 RPDU3_B3_SSPC_Order_04 "3号板卡—SSPC4通断控制命令";
CM_ SG_ 2416119808 RPDU3_B3_SSPC_Order_03 "3号板卡—SSPC3通断控制命令";
CM_ SG_ 2416119808 RPDU3_B3_SSPC_Order_02 "3号板卡—SSPC2通断控制命令";
CM_ SG_ 2416119808 RPDU3_B3_SSPC_Order_01 "3号板卡—SSPC1通断控制命令";
CM_ SG_ 2416119808 BackUp509 "预留";
CM_ SG_ 2416119808 RPDU3_B1_SSPC_Order_18 "1号板卡—SSPC18通断控制命令";
CM_ SG_ 2416119808 RPDU3_B1_SSPC_Order_17 "1号板卡—SSPC17通断控制命令";
CM_ SG_ 2416119808 RPDU3_B1_SSPC_Order_16 "1号板卡—SSPC16通断控制命令";
CM_ SG_ 2416119808 RPDU3_B1_SSPC_Order_15 "1号板卡—SSPC15通断控制命令";
CM_ SG_ 2416119808 RPDU3_B1_SSPC_Order_14 "1号板卡—SSPC14通断控制命令";
CM_ SG_ 2416119808 RPDU3_B1_SSPC_Order_13 "1号板卡—SSPC13通断控制命令";
CM_ SG_ 2416119808 RPDU3_B1_SSPC_Order_12 "1号板卡—SSPC12通断控制命令";
CM_ SG_ 2416119808 RPDU3_B1_SSPC_Order_11 "1号板卡—SSPC11通断控制命令";
CM_ SG_ 2416119808 RPDU3_B1_SSPC_Order_10 "1号板卡—SSPC10通断控制命令";
CM_ SG_ 2416119808 RPDU3_B1_SSPC_Order_09 "1号板卡—SSPC9通断控制命令";
CM_ SG_ 2416119808 RPDU3_B1_SSPC_Order_08 "1号板卡—SSPC8通断控制命令";
CM_ SG_ 2416119808 RPDU3_B1_SSPC_Order_07 "1号板卡—SSPC7通断控制命令";
CM_ SG_ 2416119808 RPDU3_B1_SSPC_Order_06 "1号板卡—SSPC6通断控制命令";
CM_ SG_ 2416119808 RPDU3_B1_SSPC_Order_05 "1号板卡—SSPC5通断控制命令";
CM_ SG_ 2416119808 RPDU3_B1_SSPC_Order_04 "1号板卡—SSPC4通断控制命令";
CM_ SG_ 2416119808 RPDU3_B1_SSPC_Order_03 "1号板卡—SSPC3通断控制命令";
CM_ SG_ 2416119808 RPDU3_B1_SSPC_Order_02 "1号板卡—SSPC2通断控制命令";
CM_ SG_ 2416119808 RPDU3_B1_SSPC_Order_01 "1号板卡—SSPC1通断控制命令";
CM_ SG_ 2416054272 BackUp508 "预留";
CM_ SG_ 2416054272 BackUp507 "预留";
CM_ SG_ 2416054272 RPDU1_B6_SSPC_Order_07 "6号板卡—SSPC7通断控制命令";
CM_ SG_ 2416054272 RPDU1_B6_SSPC_Order_06 "6号板卡—SSPC6通断控制命令";
CM_ SG_ 2416054272 RPDU1_B6_SSPC_Order_05 "6号板卡—SSPC5通断控制命令";
CM_ SG_ 2416054272 RPDU1_B6_SSPC_Order_04 "6号板卡—SSPC4通断控制命令";
CM_ SG_ 2416054272 RPDU1_B6_SSPC_Order_03 "6号板卡—SSPC3通断控制命令";
CM_ SG_ 2416054272 RPDU1_B6_SSPC_Order_02 "6号板卡—SSPC2通断控制命令";
CM_ SG_ 2416054272 RPDU1_B6_SSPC_Order_01 "6号板卡—SSPC1通断控制命令";
CM_ SG_ 2416054272 BackUp506 "预留";
CM_ SG_ 2416054272 RPDU1_B4_SSPC_Order_18 "4号板卡—SSPC18通断控制命令";
CM_ SG_ 2416054272 RPDU1_B4_SSPC_Order_17 "4号板卡—SSPC17通断控制命令";
CM_ SG_ 2416054272 RPDU1_B4_SSPC_Order_16 "4号板卡—SSPC16通断控制命令";
CM_ SG_ 2416054272 RPDU1_B4_SSPC_Order_15 "4号板卡—SSPC15通断控制命令";
CM_ SG_ 2416054272 RPDU1_B4_SSPC_Order_14 "4号板卡—SSPC14通断控制命令";
CM_ SG_ 2416054272 RPDU1_B4_SSPC_Order_13 "4号板卡—SSPC13通断控制命令";
CM_ SG_ 2416054272 RPDU1_B4_SSPC_Order_12 "4号板卡—SSPC12通断控制命令";
CM_ SG_ 2416054272 RPDU1_B4_SSPC_Order_11 "4号板卡—SSPC11通断控制命令";
CM_ SG_ 2416054272 RPDU1_B4_SSPC_Order_10 "4号板卡—SSPC10通断控制命令";
CM_ SG_ 2416054272 RPDU1_B4_SSPC_Order_09 "4号板卡—SSPC9通断控制命令";
CM_ SG_ 2416054272 RPDU1_B4_SSPC_Order_08 "4号板卡—SSPC8通断控制命令";
CM_ SG_ 2416054272 RPDU1_B4_SSPC_Order_07 "4号板卡—SSPC7通断控制命令";
CM_ SG_ 2416054272 RPDU1_B4_SSPC_Order_06 "4号板卡—SSPC6通断控制命令";
CM_ SG_ 2416054272 RPDU1_B4_SSPC_Order_05 "4号板卡—SSPC5通断控制命令";
CM_ SG_ 2416054272 RPDU1_B4_SSPC_Order_04 "4号板卡—SSPC4通断控制命令";
CM_ SG_ 2416054272 RPDU1_B4_SSPC_Order_03 "4号板卡—SSPC3通断控制命令";
CM_ SG_ 2416054272 RPDU1_B4_SSPC_Order_02 "4号板卡—SSPC2通断控制命令";
CM_ SG_ 2416054272 RPDU1_B4_SSPC_Order_01 "4号板卡—SSPC1通断控制命令";
CM_ SG_ 2416054272 BackUp505 "预留";
CM_ SG_ 2416054272 RPDU1_B2_SSPC_Order_18 "2号板卡—SSPC18通断控制命令";
CM_ SG_ 2416054272 RPDU1_B2_SSPC_Order_17 "2号板卡—SSPC17通断控制命令";
CM_ SG_ 2416054272 RPDU1_B2_SSPC_Order_16 "2号板卡—SSPC16通断控制命令";
CM_ SG_ 2416054272 RPDU1_B2_SSPC_Order_15 "2号板卡—SSPC15通断控制命令";
CM_ SG_ 2416054272 RPDU1_B2_SSPC_Order_14 "2号板卡—SSPC14通断控制命令";
CM_ SG_ 2416054272 RPDU1_B2_SSPC_Order_13 "2号板卡—SSPC13通断控制命令";
CM_ SG_ 2416054272 RPDU1_B2_SSPC_Order_12 "2号板卡—SSPC12通断控制命令";
CM_ SG_ 2416054272 RPDU1_B2_SSPC_Order_11 "2号板卡—SSPC11通断控制命令";
CM_ SG_ 2416054272 RPDU1_B2_SSPC_Order_10 "2号板卡—SSPC10通断控制命令";
CM_ SG_ 2416054272 RPDU1_B2_SSPC_Order_09 "2号板卡—SSPC9通断控制命令";
CM_ SG_ 2416054272 RPDU1_B2_SSPC_Order_08 "2号板卡—SSPC8通断控制命令";
CM_ SG_ 2416054272 RPDU1_B2_SSPC_Order_07 "2号板卡—SSPC7通断控制命令";
CM_ SG_ 2416054272 RPDU1_B2_SSPC_Order_06 "2号板卡—SSPC6通断控制命令";
CM_ SG_ 2416054272 RPDU1_B2_SSPC_Order_05 "2号板卡—SSPC5通断控制命令";
CM_ SG_ 2416054272 RPDU1_B2_SSPC_Order_04 "2号板卡—SSPC4通断控制命令";
CM_ SG_ 2416054272 RPDU1_B2_SSPC_Order_03 "2号板卡—SSPC3通断控制命令";
CM_ SG_ 2416054272 RPDU1_B2_SSPC_Order_02 "2号板卡—SSPC2通断控制命令";
CM_ SG_ 2416054272 RPDU1_B2_SSPC_Order_01 "2号板卡—SSPC1通断控制命令";
CM_ SG_ 2415988736 BackUp504 "预留";
CM_ SG_ 2415988736 BackUp503 "预留";
CM_ SG_ 2415988736 RPDU1_B5_SSPC_Order_07 "5号板卡—SSPC7通断控制命令";
CM_ SG_ 2415988736 RPDU1_B5_SSPC_Order_06 "5号板卡—SSPC6通断控制命令";
CM_ SG_ 2415988736 RPDU1_B5_SSPC_Order_05 "5号板卡—SSPC5通断控制命令";
CM_ SG_ 2415988736 RPDU1_B5_SSPC_Order_04 "5号板卡—SSPC4通断控制命令";
CM_ SG_ 2415988736 RPDU1_B5_SSPC_Order_03 "5号板卡—SSPC3通断控制命令";
CM_ SG_ 2415988736 RPDU1_B5_SSPC_Order_02 "5号板卡—SSPC2通断控制命令";
CM_ SG_ 2415988736 RPDU1_B5_SSPC_Order_01 "5号板卡—SSPC1通断控制命令";
CM_ SG_ 2415988736 BackUp502 "预留";
CM_ SG_ 2415988736 RPDU1_B3_SSPC_Order_18 "3号板卡—SSPC18通断控制命令";
CM_ SG_ 2415988736 RPDU1_B3_SSPC_Order_17 "3号板卡—SSPC17通断控制命令";
CM_ SG_ 2415988736 RPDU1_B3_SSPC_Order_16 "3号板卡—SSPC16通断控制命令";
CM_ SG_ 2415988736 RPDU1_B3_SSPC_Order_15 "3号板卡—SSPC15通断控制命令";
CM_ SG_ 2415988736 RPDU1_B3_SSPC_Order_14 "3号板卡—SSPC14通断控制命令";
CM_ SG_ 2415988736 RPDU1_B3_SSPC_Order_13 "3号板卡—SSPC13通断控制命令";
CM_ SG_ 2415988736 RPDU1_B3_SSPC_Order_12 "3号板卡—SSPC12通断控制命令";
CM_ SG_ 2415988736 RPDU1_B3_SSPC_Order_11 "3号板卡—SSPC11通断控制命令";
CM_ SG_ 2415988736 RPDU1_B3_SSPC_Order_10 "3号板卡—SSPC10通断控制命令";
CM_ SG_ 2415988736 RPDU1_B3_SSPC_Order_09 "3号板卡—SSPC9通断控制命令";
CM_ SG_ 2415988736 RPDU1_B3_SSPC_Order_08 "3号板卡—SSPC8通断控制命令";
CM_ SG_ 2415988736 RPDU1_B3_SSPC_Order_07 "3号板卡—SSPC7通断控制命令";
CM_ SG_ 2415988736 RPDU1_B3_SSPC_Order_06 "3号板卡—SSPC6通断控制命令";
CM_ SG_ 2415988736 RPDU1_B3_SSPC_Order_05 "3号板卡—SSPC5通断控制命令";
CM_ SG_ 2415988736 RPDU1_B3_SSPC_Order_04 "3号板卡—SSPC4通断控制命令";
CM_ SG_ 2415988736 RPDU1_B3_SSPC_Order_03 "3号板卡—SSPC3通断控制命令";
CM_ SG_ 2415988736 RPDU1_B3_SSPC_Order_02 "3号板卡—SSPC2通断控制命令";
CM_ SG_ 2415988736 RPDU1_B3_SSPC_Order_01 "3号板卡—SSPC1通断控制命令";
CM_ SG_ 2415988736 BackUp501 "预留";
CM_ SG_ 2415988736 RPDU1_B1_SSPC_Order_18 "1号板卡—SSPC18通断控制命令";
CM_ SG_ 2415988736 RPDU1_B1_SSPC_Order_17 "1号板卡—SSPC17通断控制命令";
CM_ SG_ 2415988736 RPDU1_B1_SSPC_Order_16 "1号板卡—SSPC16通断控制命令";
CM_ SG_ 2415988736 RPDU1_B1_SSPC_Order_15 "1号板卡—SSPC15通断控制命令";
CM_ SG_ 2415988736 RPDU1_B1_SSPC_Order_14 "1号板卡—SSPC14通断控制命令";
CM_ SG_ 2415988736 RPDU1_B1_SSPC_Order_13 "1号板卡—SSPC13通断控制命令";
CM_ SG_ 2415988736 RPDU1_B1_SSPC_Order_12 "1号板卡—SSPC12通断控制命令";
CM_ SG_ 2415988736 RPDU1_B1_SSPC_Order_11 "1号板卡—SSPC11通断控制命令";
CM_ SG_ 2415988736 RPDU1_B1_SSPC_Order_10 "1号板卡—SSPC10通断控制命令";
CM_ SG_ 2415988736 RPDU1_B1_SSPC_Order_09 "1号板卡—SSPC9通断控制命令";
CM_ SG_ 2415988736 RPDU1_B1_SSPC_Order_08 "1号板卡—SSPC8通断控制命令";
CM_ SG_ 2415988736 RPDU1_B1_SSPC_Order_07 "1号板卡—SSPC7通断控制命令";
CM_ SG_ 2415988736 RPDU1_B1_SSPC_Order_06 "1号板卡—SSPC6通断控制命令";
CM_ SG_ 2415988736 RPDU1_B1_SSPC_Order_05 "1号板卡—SSPC5通断控制命令";
CM_ SG_ 2415988736 RPDU1_B1_SSPC_Order_04 "1号板卡—SSPC4通断控制命令";
CM_ SG_ 2415988736 RPDU1_B1_SSPC_Order_03 "1号板卡—SSPC3通断控制命令";
CM_ SG_ 2415988736 RPDU1_B1_SSPC_Order_02 "1号板卡—SSPC2通断控制命令";
CM_ SG_ 2415988736 RPDU1_B1_SSPC_Order_01 "1号板卡—SSPC1通断控制命令";
CM_ SG_ 2421178416 BackUp500 "预留";
CM_ SG_ 2421178416 BackUp499 "预留";
CM_ SG_ 2421178416 E_E270_HLT_U "E 270汇流条输入电压";
CM_ SG_ 2421178416 BackUp498 "预留";
CM_ SG_ 2421178416 BackUp497 "预留";
CM_ SG_ 2421178416 BackUp496 "预留";
CM_ SG_ 2421178416 BackUp495 "预留";
CM_ SG_ 2421178416 BackUp494 "预留";
CM_ SG_ 2421178416 BackUp493 "预留";
CM_ SG_ 2421178416 BackUp492 "预留";
CM_ SG_ 2421178416 EPC_Ctrl "EPC接触器控制信号";
CM_ SG_ 2421178416 BackUp491 "预留";
CM_ SG_ 2421178416 CPC_A_STA_ChongGou "CPC＋接触器状态";
CM_ SG_ 2421178416 BackUp490 "预留";
CM_ SG_ 2421178416 BackUp489 "预留";
CM_ SG_ 2421178416 EDC1_Ctrl "EDC1接触器控制信号";
CM_ SG_ 2421178416 BackUp488 "预留";
CM_ SG_ 2421178416 BackUp487 "预留";
CM_ SG_ 2421178416 BackUp486 "预留";
CM_ SG_ 2421178416 BackUp485 "预留";
CM_ SG_ 2421178416 E_HLT28IOver_ChongGou "E28DC汇流条输入电流过流";
CM_ SG_ 2421178416 E_HLT270IOver_ChongGou "E270DC汇流条输入电流过流";
CM_ SG_ 2416181296 E_DuanLuQi_Sta_48 "断路器48状态";
CM_ SG_ 2416181296 E_DuanLuQi_Sta_47 "断路器47状态";
CM_ SG_ 2416181296 E_DuanLuQi_Sta_46 "断路器46状态";
CM_ SG_ 2416181296 E_DuanLuQi_Sta_45 "断路器45状态";
CM_ SG_ 2416181296 E_DuanLuQi_Sta_44 "断路器44状态";
CM_ SG_ 2416181296 E_DuanLuQi_Sta_43 "断路器43状态";
CM_ SG_ 2416181296 E_DuanLuQi_Sta_42 "断路器42状态";
CM_ SG_ 2416181296 E_DuanLuQi_Sta_41 "断路器41状态";
CM_ SG_ 2416181296 E_DuanLuQi_Sta_40 "断路器40状态";
CM_ SG_ 2416181296 E_DuanLuQi_Sta_39 "断路器39状态";
CM_ SG_ 2416181296 E_DuanLuQi_Sta_38 "断路器38状态";
CM_ SG_ 2416181296 E_DuanLuQi_Sta_37 "断路器37状态";
CM_ SG_ 2416181296 E_DuanLuQi_Sta_36 "断路器36状态";
CM_ SG_ 2416181296 E_DuanLuQi_Sta_35 "断路器35状态";
CM_ SG_ 2416181296 E_DuanLuQi_Sta_34 "断路器34状态";
CM_ SG_ 2416181296 E_DuanLuQi_Sta_33 "断路器33状态";
CM_ SG_ 2416181296 E_DuanLuQi_Sta_32 "断路器32状态";
CM_ SG_ 2416181296 E_DuanLuQi_Sta_31 "断路器31状态";
CM_ SG_ 2416181296 E_DuanLuQi_Sta_30 "断路器30状态";
CM_ SG_ 2416181296 E_DuanLuQi_Sta_29 "断路器29状态";
CM_ SG_ 2416181296 E_DuanLuQi_Sta_28 "断路器28状态";
CM_ SG_ 2416181296 E_DuanLuQi_Sta_27 "断路器27状态";
CM_ SG_ 2416181296 E_DuanLuQi_Sta_26 "断路器26状态";
CM_ SG_ 2416181296 E_DuanLuQi_Sta_25 "断路器25状态";
CM_ SG_ 2416181296 E_DuanLuQi_Sta_24 "断路器24状态";
CM_ SG_ 2416181296 E_DuanLuQi_Sta_23 "断路器23状态";
CM_ SG_ 2416181296 E_DuanLuQi_Sta_22 "断路器22状态";
CM_ SG_ 2416181296 E_DuanLuQi_Sta_21 "断路器21状态";
CM_ SG_ 2416181296 E_DuanLuQi_Sta_20 "断路器20状态";
CM_ SG_ 2416181296 E_DuanLuQi_Sta_19 "断路器19状态";
CM_ SG_ 2416181296 E_DuanLuQi_Sta_18 "断路器18状态";
CM_ SG_ 2416181296 E_DuanLuQi_Sta_17 "断路器17状态";
CM_ SG_ 2416181296 E_DuanLuQi_Sta_16 "断路器16状态";
CM_ SG_ 2416181296 E_DuanLuQi_Sta_15 "断路器15状态";
CM_ SG_ 2416181296 E_DuanLuQi_Sta_14 "断路器14状态";
CM_ SG_ 2416181296 E_DuanLuQi_Sta_13 "断路器13状态";
CM_ SG_ 2416181296 E_DuanLuQi_Sta_12 "断路器12状态";
CM_ SG_ 2416181296 E_DuanLuQi_Sta_11 "断路器11状态";
CM_ SG_ 2416181296 E_DuanLuQi_Sta_10 "断路器10状态";
CM_ SG_ 2416181296 E_DuanLuQi_Sta_09 "断路器9状态";
CM_ SG_ 2416181296 E_DuanLuQi_Sta_08 "断路器8状态";
CM_ SG_ 2416181296 E_DuanLuQi_Sta_07 "断路器7状态";
CM_ SG_ 2416181296 E_DuanLuQi_Sta_06 "断路器6状态";
CM_ SG_ 2416181296 E_DuanLuQi_Sta_05 "断路器5状态";
CM_ SG_ 2416181296 E_DuanLuQi_Sta_04 "断路器4状态";
CM_ SG_ 2416181296 E_DuanLuQi_Sta_03 "断路器3状态";
CM_ SG_ 2416181296 E_DuanLuQi_Sta_02 "断路器2状态";
CM_ SG_ 2416181296 E_DuanLuQi_Sta_01 "断路器1状态";
CM_ SG_ 2416640048 BackUp484 "预留";
CM_ SG_ 2416640048 E_TouChuan_DCDC_DDCSta "DDC 接触器状态信号";
CM_ SG_ 2416640048 E_TouChuan_DCDC_DDCCtrl "DDC 接触器控制信号";
CM_ SG_ 2416640048 E_TouChuan_DCDC_FanWarn "风扇异常告警";
CM_ SG_ 2416640048 E_TouChuan_DCDC_ConnStaErr "输出接触器状态故障";
CM_ SG_ 2416640048 E_TouChuan_DCDC_HardOutOverErr "硬件输出过压故障";
CM_ SG_ 2416640048 E_TouChuan_DCDC_TOverErr "过温故障";
CM_ SG_ 2416640048 E_TouChuan_DCDC_TOverWarn "过温告警";
CM_ SG_ 2416640048 E_TouChuan_DCDC_OutILimitErr "输出限流故障";
CM_ SG_ 2416640048 E_TouChuan_DCDC_OutIOverErr "输出过流故障";
CM_ SG_ 2416640048 E_TouChuan_DCDC_OutPowOverErr "输出过压故障";
CM_ SG_ 2416640048 E_TouChuan_DCDC_OutPowLowErr "输出欠压故障";
CM_ SG_ 2416640048 E_TouChuan_DCDC_OutPowLowWarn "输出电压低告警";
CM_ SG_ 2416640048 E_TouChuan_DCDC_InPowLowErr "输入欠压故障";
CM_ SG_ 2416574512 BackUp481 "预留";
CM_ SG_ 2416574512 E_TouChuan_DCDC_12_2U "二次电源12V-2";
CM_ SG_ 2416508976 E_TouChuan_DCDC_12_1U "二次电源12V-1";
CM_ SG_ 2416508976 E_TouChuan_DCDC_5_U "二次电源5V电压";
CM_ SG_ 2416508976 E_TouChuan_DCDC_270To28_U "270V转28V电压";
CM_ SG_ 2416508976 E_TouChuan_DCDC_In_28U "28V输入电压";
CM_ SG_ 2416443440 E_TouChuan_DCDC_T "产品内部温度";
CM_ SG_ 2416443440 E_TouChuan_DCDC_Out_I "输出电流";
CM_ SG_ 2416443440 E_TouChuan_DCDC_Out_U "输出电压";
CM_ SG_ 2416443440 E_TouChuan_DCDC_In_U "输入电压";
CM_ SG_ 2416377904 E_DCDC_Ver_D "版本号段D";
CM_ SG_ 2416377904 E_DCDC_Ver_C "版本号段C";
CM_ SG_ 2416377904 E_DCDC_Ver_B "版本号段B";
CM_ SG_ 2416377904 E_DCDC_Ver_A "版本号段A";
CM_ SG_ 2416312368 E_ECU_Ver_Day "日期";
CM_ SG_ 2416312368 E_ECU_Ver_Month "月份";
CM_ SG_ 2416312368 E_ECU_Ver_Year "年份";
CM_ SG_ 2416312368 E_ECU_Ver_D "版本号段D";
CM_ SG_ 2416312368 E_ECU_Ver_C "版本号段C";
CM_ SG_ 2416312368 E_ECU_Ver_B "版本号段B";
CM_ SG_ 2416312368 E_ECU_Ver_A "版本号段A";
CM_ SG_ 2416246832 BackUp480 "预留";
CM_ SG_ 2416246832 E_HLT28IOver "E 28 DC汇流条输入电流状态";
CM_ SG_ 2416246832 E_WaiBu270IOver "外部电源输入电流状态";
CM_ SG_ 2416246832 E_HLT270IOver "E 270 DC汇流条输入电流状态";
CM_ SG_ 2416246832 BackUp479 "预留";
CM_ SG_ 2416246832 E_HLT28USta "E 28 DC汇流条电压状态";
CM_ SG_ 2416246832 E_DCDC28OutUSta "E 270-28 DCDC变换器输出电源电压状态";
CM_ SG_ 2416246832 E_DCDC270InUSta "E 270-28 DCDC变换器输入电源电压状态";
CM_ SG_ 2416246832 E_HLT270USta "E 270 DC汇流条电压状态";
CM_ SG_ 2416246832 E_ChongDianUSta "充电电压状态";
CM_ SG_ 2416246832 E_WaiBu270USta "外部电源电压状态";
CM_ SG_ 2416246832 E_Batter270USta "E 270电池输入电压状态";
CM_ SG_ 2416246832 BackUp478 "预留";
CM_ SG_ 2416246832 E_ADCIN_BIT "模拟量采集电路自检";
CM_ SG_ 2416246832 E_GpioIN_BIT "离散量采集电路自检";
CM_ SG_ 2416246832 E_Flash_BIT "存储电路自检";
CM_ SG_ 2416246832 E_UART_BIT "RS422总线自检";
CM_ SG_ 2416246832 E_ExtCAN2_BIT "外部CAN总线2自检";
CM_ SG_ 2416246832 E_ExtCAN1_BIT "外部CAN总线1自检";
CM_ SG_ 2416246832 E_CPU_BIT "主处理器自检";
CM_ SG_ 2416246832 E_Pow_BIT "电源电路自检";
CM_ SG_ 2416115760 BackUp477 "预留";
CM_ SG_ 2416115760 CPC_B_STA "CPC-接触器状态";
CM_ SG_ 2416115760 CPC_A_STA "CPC+接触器状态";
CM_ SG_ 2416115760 EPC_STA "EPC接触器状态";
CM_ SG_ 2416050224 YingJi_Batter_U "应急蓄电池输入电源电压";
CM_ SG_ 2416050224 E_DCDC_Out_U "E 270-28 DCDC变换器输出电源电压";
CM_ SG_ 2416050224 E270_Batter_U "E270V电池输入电压";
CM_ SG_ 2416050224 ChongDian_In_U "充电口输入电压";
CM_ SG_ 2415984688 WaiBu_In_U "外电源输入电压";
CM_ SG_ 2415984688 WaiBu_In_I "外部电源输入电流";
CM_ SG_ 2415984688 E28_HLT_In_I "E 28 DC汇流条输入电流";
CM_ SG_ 2415984688 E270_HLT_In_I "E 270汇流条输入电流";
CM_ SG_ 2421178400 BackUp476 "预留";
CM_ SG_ 2421178400 BackUp475 "预留";
CM_ SG_ 2421178400 BackUp474 "预留";
CM_ SG_ 2421178400 BackUp473 "预留";
CM_ SG_ 2421178400 BackUp472 "预留";
CM_ SG_ 2421178400 BackUp471 "预留";
CM_ SG_ 2421178400 BackUp470 "预留";
CM_ SG_ 2421178400 RETC1_ChongGou_ChangJing "RETC1控制时的场景";
CM_ SG_ 2421178400 RETC1_STA_ChongGou "RETC1接触器状态";
CM_ SG_ 2421178400 BackUp469 "预留";
CM_ SG_ 2421178400 BackUp468 "预留";
CM_ SG_ 2421178400 BackUp467 "预留";
CM_ SG_ 2421178400 BackUp466 "预留";
CM_ SG_ 2421178400 BackUp465 "预留";
CM_ SG_ 2421178400 RDC2_Ctrl "RDC2接触器控制信号";
CM_ SG_ 2421178400 RDC1_Ctrl "RDC1接触器控制信号";
CM_ SG_ 2421178400 BackUp464 "预留";
CM_ SG_ 2421178400 BTC1_ChongGou_ChangJing "BTC1接触器控制时的场景";
CM_ SG_ 2421178400 RETC1_ReSta "RETC1接触器辅助触点状态";
CM_ SG_ 2421178400 R_HLT282IOver_ChongGou "R28DC汇流条2输入电流过流";
CM_ SG_ 2421178400 R_HLT281IOver_ChongGou "R28DC汇流条1输入电流过流";
CM_ SG_ 2421178400 R_HLT270IOver_ChongGou "R270DC汇流条输入电流过流";
CM_ SG_ 2420244512 RPDU4_Index "序号";
CM_ SG_ 2420244512 BackUp463 "预留";
CM_ SG_ 2420244512 RPDU4_Time "时间";
CM_ SG_ 2420244512 RPDU4_SSPC_Ver "SSPC模块软件版本号";
CM_ SG_ 2420244512 RPDU4_PS_Ver "PS软件版本号";
CM_ SG_ 2420244512 BackUp462 "预留";
CM_ SG_ 2420244512 RPDU4_Hard_Num "硬件修改号";
CM_ SG_ 2420178976 BackUp461 "预留";
CM_ SG_ 2420178976 BackUp460 "预留";
CM_ SG_ 2420178976 RPDU4_B6_SSPC_I_Load_07 "SSPC7通道电流";
CM_ SG_ 2420178976 RPDU4_B6_SSPC_TripSta_07 "SSPC7跳闸状态";
CM_ SG_ 2420178976 RPDU4_B6_SSPC_BitErr_07 "SSPC7通断周期自检状态";
CM_ SG_ 2420178976 RPDU4_B6_SSPC_OnOffSta_07 "SSPC7通断状态";
CM_ SG_ 2420178976 RPDU4_B6_SSPC_DianHuErr_07 "SSPC7电弧故障状态";
CM_ SG_ 2420178976 BackUp459 "预留";
CM_ SG_ 2420178976 RPDU4_B6_SSPC_I_Load_06 "SSPC6通道电流";
CM_ SG_ 2420178976 RPDU4_B6_SSPC_TripSta_06 "SSPC6跳闸状态";
CM_ SG_ 2420178976 RPDU4_B6_SSPC_BitErr_06 "SSPC6通断周期自检状态";
CM_ SG_ 2420178976 RPDU4_B6_SSPC_OnOffSta_06 "SSPC6通断状态";
CM_ SG_ 2420178976 RPDU4_B6_SSPC_DianHuErr_06 "SSPC6电弧故障状态";
CM_ SG_ 2420178976 BackUp458 "预留";
CM_ SG_ 2420178976 RPDU4_B6_SSPC_I_Load_05 "SSPC5通道电流";
CM_ SG_ 2420178976 RPDU4_B6_SSPC_TripSta_05 "SSPC5跳闸状态";
CM_ SG_ 2420178976 RPDU4_B6_SSPC_BitErr_05 "SSPC5通断周期自检状态";
CM_ SG_ 2420178976 RPDU4_B6_SSPC_OnOffSta_05 "SSPC5通断状态";
CM_ SG_ 2420178976 RPDU4_B6_SSPC_DianHuErr_05 "SSPC5电弧故障状态";
CM_ SG_ 2420178976 BackUp457 "预留";
CM_ SG_ 2420113440 RPDU4_B6_SSPC_I_Load_04 "SSPC4通道电流";
CM_ SG_ 2420113440 RPDU4_B6_SSPC_TripSta_04 "SSPC4跳闸状态";
CM_ SG_ 2420113440 RPDU4_B6_SSPC_BitErr_04 "SSPC4通断周期自检状态";
CM_ SG_ 2420113440 RPDU4_B6_SSPC_OnOffSta_04 "SSPC4通断状态";
CM_ SG_ 2420113440 RPDU4_B6_SSPC_DianHuErr_04 "SSPC4电弧故障状态";
CM_ SG_ 2420113440 BackUp456 "预留";
CM_ SG_ 2420113440 RPDU4_B6_SSPC_I_Load_03 "SSPC3通道电流";
CM_ SG_ 2420113440 RPDU4_B6_SSPC_TripSta_03 "SSPC3跳闸状态";
CM_ SG_ 2420113440 RPDU4_B6_SSPC_BitErr_03 "SSPC3通断周期自检状态";
CM_ SG_ 2420113440 RPDU4_B6_SSPC_OnOffSta_03 "SSPC3通断状态";
CM_ SG_ 2420113440 RPDU4_B6_SSPC_DianHuErr_03 "SSPC3电弧故障状态";
CM_ SG_ 2420113440 BackUp455 "预留";
CM_ SG_ 2420113440 RPDU4_B6_SSPC_I_Load_02 "SSPC2通道电流";
CM_ SG_ 2420113440 RPDU4_B6_SSPC_TripSta_02 "SSPC2跳闸状态";
CM_ SG_ 2420113440 RPDU4_B6_SSPC_BitErr_02 "SSPC2通断周期自检状态";
CM_ SG_ 2420113440 RPDU4_B6_SSPC_OnOffSta_02 "SSPC2通断状态";
CM_ SG_ 2420113440 RPDU4_B6_SSPC_DianHuErr_02 "SSPC2电弧故障状态";
CM_ SG_ 2420113440 BackUp454 "预留";
CM_ SG_ 2420113440 RPDU4_B6_SSPC_I_Load_01 "SSPC1通道电流";
CM_ SG_ 2420113440 RPDU4_B6_SSPC_TripSta_01 "SSPC1跳闸状态";
CM_ SG_ 2420113440 RPDU4_B6_SSPC_BitErr_01 "SSPC1通断周期自检状态";
CM_ SG_ 2420113440 RPDU4_B6_SSPC_OnOffSta_01 "SSPC1通断状态";
CM_ SG_ 2420113440 RPDU4_B6_SSPC_DianHuErr_01 "SSPC1电弧故障状态";
CM_ SG_ 2420113440 BackUp453 "预留";
CM_ SG_ 2420047904 BackUp452 "预留";
CM_ SG_ 2420047904 BackUp451 "预留";
CM_ SG_ 2420047904 RPDU4_B5_SSPC_I_Load_07 "SSPC7通道电流";
CM_ SG_ 2420047904 RPDU4_B5_SSPC_TripSta_07 "SSPC7跳闸状态";
CM_ SG_ 2420047904 RPDU4_B5_SSPC_BitErr_07 "SSPC7通断周期自检状态";
CM_ SG_ 2420047904 RPDU4_B5_SSPC_OnOffSta_07 "SSPC7通断状态";
CM_ SG_ 2420047904 RPDU4_B5_SSPC_DianHuErr_07 "SSPC7电弧故障状态";
CM_ SG_ 2420047904 BackUp450 "预留";
CM_ SG_ 2420047904 RPDU4_B5_SSPC_I_Load_06 "SSPC6通道电流";
CM_ SG_ 2420047904 RPDU4_B5_SSPC_TripSta_06 "SSPC6跳闸状态";
CM_ SG_ 2420047904 RPDU4_B5_SSPC_BitErr_06 "SSPC6通断周期自检状态";
CM_ SG_ 2420047904 RPDU4_B5_SSPC_OnOffSta_06 "SSPC6通断状态";
CM_ SG_ 2420047904 RPDU4_B5_SSPC_DianHuErr_06 "SSPC6电弧故障状态";
CM_ SG_ 2420047904 BackUp449 "预留";
CM_ SG_ 2420047904 RPDU4_B5_SSPC_I_Load_05 "SSPC5通道电流";
CM_ SG_ 2420047904 RPDU4_B5_SSPC_TripSta_05 "SSPC5跳闸状态";
CM_ SG_ 2420047904 RPDU4_B5_SSPC_BitErr_05 "SSPC5通断周期自检状态";
CM_ SG_ 2420047904 RPDU4_B5_SSPC_OnOffSta_05 "SSPC5通断状态";
CM_ SG_ 2420047904 RPDU4_B5_SSPC_DianHuErr_05 "SSPC5电弧故障状态";
CM_ SG_ 2420047904 BackUp448 "预留";
CM_ SG_ 2419982368 RPDU4_B5_SSPC_I_Load_04 "SSPC4通道电流";
CM_ SG_ 2419982368 RPDU4_B5_SSPC_TripSta_04 "SSPC4跳闸状态";
CM_ SG_ 2419982368 RPDU4_B5_SSPC_BitErr_04 "SSPC4通断周期自检状态";
CM_ SG_ 2419982368 RPDU4_B5_SSPC_OnOffSta_04 "SSPC4通断状态";
CM_ SG_ 2419982368 RPDU4_B5_SSPC_DianHuErr_04 "SSPC4电弧故障状态";
CM_ SG_ 2419982368 BackUp447 "预留";
CM_ SG_ 2419982368 RPDU4_B5_SSPC_I_Load_03 "SSPC3通道电流";
CM_ SG_ 2419982368 RPDU4_B5_SSPC_TripSta_03 "SSPC3跳闸状态";
CM_ SG_ 2419982368 RPDU4_B5_SSPC_BitErr_03 "SSPC3通断周期自检状态";
CM_ SG_ 2419982368 RPDU4_B5_SSPC_OnOffSta_03 "SSPC3通断状态";
CM_ SG_ 2419982368 RPDU4_B5_SSPC_DianHuErr_03 "SSPC3电弧故障状态";
CM_ SG_ 2419982368 BackUp446 "预留";
CM_ SG_ 2419982368 RPDU4_B5_SSPC_I_Load_02 "SSPC2通道电流";
CM_ SG_ 2419982368 RPDU4_B5_SSPC_TripSta_02 "SSPC2跳闸状态";
CM_ SG_ 2419982368 RPDU4_B5_SSPC_BitErr_02 "SSPC2通断周期自检状态";
CM_ SG_ 2419982368 RPDU4_B5_SSPC_OnOffSta_02 "SSPC2通断状态";
CM_ SG_ 2419982368 RPDU4_B5_SSPC_DianHuErr_02 "SSPC2电弧故障状态";
CM_ SG_ 2419982368 BackUp445 "预留";
CM_ SG_ 2419982368 RPDU4_B5_SSPC_I_Load_01 "SSPC1通道电流";
CM_ SG_ 2419982368 RPDU4_B5_SSPC_TripSta_01 "SSPC1跳闸状态";
CM_ SG_ 2419982368 RPDU4_B5_SSPC_BitErr_01 "SSPC1通断周期自检状态";
CM_ SG_ 2419982368 RPDU4_B5_SSPC_OnOffSta_01 "SSPC1通断状态";
CM_ SG_ 2419982368 RPDU4_B5_SSPC_DianHuErr_01 "SSPC1电弧故障状态";
CM_ SG_ 2419982368 BackUp444 "预留";
CM_ SG_ 2419916832 BackUp443 "预留";
CM_ SG_ 2419916832 BackUp442 "预留";
CM_ SG_ 2419916832 BackUp441 "预留";
CM_ SG_ 2419916832 BackUp440 "预留";
CM_ SG_ 2419916832 RPDU4_B4_SSPC_I_Load_18 "SSPC18通道电流";
CM_ SG_ 2419916832 RPDU4_B4_SSPC_TripSta_18 "SSPC18跳闸状态";
CM_ SG_ 2419916832 RPDU4_B4_SSPC_BitErr_18 "SSPC18通断周期自检状态";
CM_ SG_ 2419916832 RPDU4_B4_SSPC_OnOffSta_18 "SSPC18通断状态";
CM_ SG_ 2419916832 RPDU4_B4_SSPC_DianHuErr_18 "SSPC18电弧故障状态";
CM_ SG_ 2419916832 BackUp439 "预留";
CM_ SG_ 2419916832 RPDU4_B4_SSPC_I_Load_17 "SSPC17通道电流";
CM_ SG_ 2419916832 RPDU4_B4_SSPC_TripSta_17 "SSPC17跳闸状态";
CM_ SG_ 2419916832 RPDU4_B4_SSPC_BitErr_17 "SSPC17通断周期自检状态";
CM_ SG_ 2419916832 RPDU4_B4_SSPC_OnOffSta_17 "SSPC17通断状态";
CM_ SG_ 2419916832 RPDU4_B4_SSPC_DianHuErr_17 "SSPC17电弧故障状态";
CM_ SG_ 2419916832 BackUp438 "预留";
CM_ SG_ 2419851296 RPDU4_B4_SSPC_I_Load_16 "SSPC16通道电流";
CM_ SG_ 2419851296 RPDU4_B4_SSPC_TripSta_16 "SSPC16跳闸状态";
CM_ SG_ 2419851296 RPDU4_B4_SSPC_BitErr_16 "SSPC16通断周期自检状态";
CM_ SG_ 2419851296 RPDU4_B4_SSPC_OnOffSta_16 "SSPC16通断状态";
CM_ SG_ 2419851296 RPDU4_B4_SSPC_DianHuErr_16 "SSPC16电弧故障状态";
CM_ SG_ 2419851296 BackUp437 "预留";
CM_ SG_ 2419851296 RPDU4_B4_SSPC_I_Load_15 "SSPC15通道电流";
CM_ SG_ 2419851296 RPDU4_B4_SSPC_TripSta_15 "SSPC15跳闸状态";
CM_ SG_ 2419851296 RPDU4_B4_SSPC_BitErr_15 "SSPC15通断周期自检状态";
CM_ SG_ 2419851296 RPDU4_B4_SSPC_OnOffSta_15 "SSPC15通断状态";
CM_ SG_ 2419851296 RPDU4_B4_SSPC_DianHuErr_15 "SSPC15电弧故障状态";
CM_ SG_ 2419851296 BackUp436 "预留";
CM_ SG_ 2419851296 RPDU4_B4_SSPC_I_Load_14 "SSPC14通道电流";
CM_ SG_ 2419851296 RPDU4_B4_SSPC_TripSta_14 "SSPC14跳闸状态";
CM_ SG_ 2419851296 RPDU4_B4_SSPC_BitErr_14 "SSPC14通断周期自检状态";
CM_ SG_ 2419851296 RPDU4_B4_SSPC_OnOffSta_14 "SSPC14通断状态";
CM_ SG_ 2419851296 RPDU4_B4_SSPC_DianHuErr_14 "SSPC14电弧故障状态";
CM_ SG_ 2419851296 BackUp435 "预留";
CM_ SG_ 2419851296 RPDU4_B4_SSPC_I_Load_13 "SSPC13通道电流";
CM_ SG_ 2419851296 RPDU4_B4_SSPC_TripSta_13 "SSPC13跳闸状态";
CM_ SG_ 2419851296 RPDU4_B4_SSPC_BitErr_13 "SSPC13通断周期自检状态";
CM_ SG_ 2419851296 RPDU4_B4_SSPC_OnOffSta_13 "SSPC13通断状态";
CM_ SG_ 2419851296 RPDU4_B4_SSPC_DianHuErr_13 "SSPC13电弧故障状态";
CM_ SG_ 2419851296 BackUp434 "预留";
CM_ SG_ 2419785760 RPDU4_B4_SSPC_I_Load_12 "SSPC12通道电流";
CM_ SG_ 2419785760 RPDU4_B4_SSPC_TripSta_12 "SSPC12跳闸状态";
CM_ SG_ 2419785760 RPDU4_B4_SSPC_BitErr_12 "SSPC12通断周期自检状态";
CM_ SG_ 2419785760 RPDU4_B4_SSPC_OnOffSta_12 "SSPC12通断状态";
CM_ SG_ 2419785760 RPDU4_B4_SSPC_DianHuErr_12 "SSPC12电弧故障状态";
CM_ SG_ 2419785760 BackUp433 "预留";
CM_ SG_ 2419785760 RPDU4_B4_SSPC_I_Load_11 "SSPC11通道电流";
CM_ SG_ 2419785760 RPDU4_B4_SSPC_TripSta_11 "SSPC11跳闸状态";
CM_ SG_ 2419785760 RPDU4_B4_SSPC_BitErr_11 "SSPC11通断周期自检状态";
CM_ SG_ 2419785760 RPDU4_B4_SSPC_OnOffSta_11 "SSPC11通断状态";
CM_ SG_ 2419785760 RPDU4_B4_SSPC_DianHuErr_11 "SSPC11电弧故障状态";
CM_ SG_ 2419785760 BackUp432 "预留";
CM_ SG_ 2419785760 RPDU4_B4_SSPC_I_Load_10 "SSPC10通道电流";
CM_ SG_ 2419785760 RPDU4_B4_SSPC_TripSta_10 "SSPC10跳闸状态";
CM_ SG_ 2419785760 RPDU4_B4_SSPC_BitErr_10 "SSPC10通断周期自检状态";
CM_ SG_ 2419785760 RPDU4_B4_SSPC_OnOffSta_10 "SSPC10通断状态";
CM_ SG_ 2419785760 RPDU4_B4_SSPC_DianHuErr_10 "SSPC10电弧故障状态";
CM_ SG_ 2419785760 BackUp431 "预留";
CM_ SG_ 2419785760 RPDU4_B4_SSPC_I_Load_09 "SSPC9通道电流";
CM_ SG_ 2419785760 RPDU4_B4_SSPC_TripSta_09 "SSPC9跳闸状态";
CM_ SG_ 2419785760 RPDU4_B4_SSPC_BitErr_09 "SSPC9通断周期自检状态";
CM_ SG_ 2419785760 RPDU4_B4_SSPC_OnOffSta_09 "SSPC9通断状态";
CM_ SG_ 2419785760 RPDU4_B4_SSPC_DianHuErr_09 "SSPC9电弧故障状态";
CM_ SG_ 2419785760 BackUp430 "预留";
CM_ SG_ 2419720224 RPDU4_B4_SSPC_I_Load_08 "SSPC8通道电流";
CM_ SG_ 2419720224 RPDU4_B4_SSPC_TripSta_08 "SSPC8跳闸状态";
CM_ SG_ 2419720224 RPDU4_B4_SSPC_BitErr_08 "SSPC8通断周期自检状态";
CM_ SG_ 2419720224 RPDU4_B4_SSPC_OnOffSta_08 "SSPC8通断状态";
CM_ SG_ 2419720224 RPDU4_B4_SSPC_DianHuErr_08 "SSPC8电弧故障状态";
CM_ SG_ 2419720224 BackUp429 "预留";
CM_ SG_ 2419720224 RPDU4_B4_SSPC_I_Load_07 "SSPC7通道电流";
CM_ SG_ 2419720224 RPDU4_B4_SSPC_TripSta_07 "SSPC7跳闸状态";
CM_ SG_ 2419720224 RPDU4_B4_SSPC_BitErr_07 "SSPC7通断周期自检状态";
CM_ SG_ 2419720224 RPDU4_B4_SSPC_OnOffSta_07 "SSPC7通断状态";
CM_ SG_ 2419720224 RPDU4_B4_SSPC_DianHuErr_07 "SSPC7电弧故障状态";
CM_ SG_ 2419720224 BackUp428 "预留";
CM_ SG_ 2419720224 RPDU4_B4_SSPC_I_Load_06 "SSPC6通道电流";
CM_ SG_ 2419720224 RPDU4_B4_SSPC_TripSta_06 "SSPC6跳闸状态";
CM_ SG_ 2419720224 RPDU4_B4_SSPC_BitErr_06 "SSPC6通断周期自检状态";
CM_ SG_ 2419720224 RPDU4_B4_SSPC_OnOffSta_06 "SSPC6通断状态";
CM_ SG_ 2419720224 RPDU4_B4_SSPC_DianHuErr_06 "SSPC6电弧故障状态";
CM_ SG_ 2419720224 BackUp427 "预留";
CM_ SG_ 2419720224 RPDU4_B4_SSPC_I_Load_05 "SSPC5通道电流";
CM_ SG_ 2419720224 RPDU4_B4_SSPC_TripSta_05 "SSPC5跳闸状态";
CM_ SG_ 2419720224 RPDU4_B4_SSPC_BitErr_05 "SSPC5通断周期自检状态";
CM_ SG_ 2419720224 RPDU4_B4_SSPC_OnOffSta_05 "SSPC5通断状态";
CM_ SG_ 2419720224 RPDU4_B4_SSPC_DianHuErr_05 "SSPC5电弧故障状态";
CM_ SG_ 2419720224 BackUp426 "预留";
CM_ SG_ 2419654688 RPDU4_B4_SSPC_I_Load_04 "SSPC4通道电流";
CM_ SG_ 2419654688 RPDU4_B4_SSPC_TripSta_04 "SSPC4跳闸状态";
CM_ SG_ 2419654688 RPDU4_B4_SSPC_BitErr_04 "SSPC4通断周期自检状态";
CM_ SG_ 2419654688 RPDU4_B4_SSPC_OnOffSta_04 "SSPC4通断状态";
CM_ SG_ 2419654688 RPDU4_B4_SSPC_DianHuErr_04 "SSPC4电弧故障状态";
CM_ SG_ 2419654688 BackUp425 "预留";
CM_ SG_ 2419654688 RPDU4_B4_SSPC_I_Load_03 "SSPC3通道电流";
CM_ SG_ 2419654688 RPDU4_B4_SSPC_TripSta_03 "SSPC3跳闸状态";
CM_ SG_ 2419654688 RPDU4_B4_SSPC_BitErr_03 "SSPC3通断周期自检状态";
CM_ SG_ 2419654688 RPDU4_B4_SSPC_OnOffSta_03 "SSPC3通断状态";
CM_ SG_ 2419654688 RPDU4_B4_SSPC_DianHuErr_03 "SSPC3电弧故障状态";
CM_ SG_ 2419654688 BackUp424 "预留";
CM_ SG_ 2419654688 RPDU4_B4_SSPC_I_Load_02 "SSPC2通道电流";
CM_ SG_ 2419654688 RPDU4_B4_SSPC_TripSta_02 "SSPC2跳闸状态";
CM_ SG_ 2419654688 RPDU4_B4_SSPC_BitErr_02 "SSPC2通断周期自检状态";
CM_ SG_ 2419654688 RPDU4_B4_SSPC_OnOffSta_02 "SSPC2通断状态";
CM_ SG_ 2419654688 RPDU4_B4_SSPC_DianHuErr_02 "SSPC2电弧故障状态";
CM_ SG_ 2419654688 BackUp423 "预留";
CM_ SG_ 2419654688 RPDU4_B4_SSPC_I_Load_01 "SSPC1通道电流";
CM_ SG_ 2419654688 RPDU4_B4_SSPC_TripSta_01 "SSPC1跳闸状态";
CM_ SG_ 2419654688 RPDU4_B4_SSPC_BitErr_01 "SSPC1通断周期自检状态";
CM_ SG_ 2419654688 RPDU4_B4_SSPC_OnOffSta_01 "SSPC1通断状态";
CM_ SG_ 2419654688 RPDU4_B4_SSPC_DianHuErr_01 "SSPC1电弧故障状态";
CM_ SG_ 2419654688 BackUp422 "预留";
CM_ SG_ 2419589152 BackUp421 "预留";
CM_ SG_ 2419589152 BackUp420 "预留";
CM_ SG_ 2419589152 BackUp419 "预留";
CM_ SG_ 2419589152 BackUp418 "预留";
CM_ SG_ 2419589152 RPDU4_B3_SSPC_I_Load_18 "SSPC18通道电流";
CM_ SG_ 2419589152 RPDU4_B3_SSPC_TripSta_18 "SSPC18跳闸状态";
CM_ SG_ 2419589152 RPDU4_B3_SSPC_BitErr_18 "SSPC18通断周期自检状态";
CM_ SG_ 2419589152 RPDU4_B3_SSPC_OnOffSta_18 "SSPC18通断状态";
CM_ SG_ 2419589152 RPDU4_B3_SSPC_DianHuErr_18 "SSPC18电弧故障状态";
CM_ SG_ 2419589152 BackUp417 "预留";
CM_ SG_ 2419589152 RPDU4_B3_SSPC_I_Load_17 "SSPC17通道电流";
CM_ SG_ 2419589152 RPDU4_B3_SSPC_TripSta_17 "SSPC17跳闸状态";
CM_ SG_ 2419589152 RPDU4_B3_SSPC_BitErr_17 "SSPC17通断周期自检状态";
CM_ SG_ 2419589152 RPDU4_B3_SSPC_OnOffSta_17 "SSPC17通断状态";
CM_ SG_ 2419589152 RPDU4_B3_SSPC_DianHuErr_17 "SSPC17电弧故障状态";
CM_ SG_ 2419589152 BackUp416 "预留";
CM_ SG_ 2419523616 RPDU4_B3_SSPC_I_Load_16 "SSPC16通道电流";
CM_ SG_ 2419523616 RPDU4_B3_SSPC_TripSta_16 "SSPC16跳闸状态";
CM_ SG_ 2419523616 RPDU4_B3_SSPC_BitErr_16 "SSPC16通断周期自检状态";
CM_ SG_ 2419523616 RPDU4_B3_SSPC_OnOffSta_16 "SSPC16通断状态";
CM_ SG_ 2419523616 RPDU4_B3_SSPC_DianHuErr_16 "SSPC16电弧故障状态";
CM_ SG_ 2419523616 BackUp415 "预留";
CM_ SG_ 2419523616 RPDU4_B3_SSPC_I_Load_15 "SSPC15通道电流";
CM_ SG_ 2419523616 RPDU4_B3_SSPC_TripSta_15 "SSPC15跳闸状态";
CM_ SG_ 2419523616 RPDU4_B3_SSPC_BitErr_15 "SSPC15通断周期自检状态";
CM_ SG_ 2419523616 RPDU4_B3_SSPC_OnOffSta_15 "SSPC15通断状态";
CM_ SG_ 2419523616 RPDU4_B3_SSPC_DianHuErr_15 "SSPC15电弧故障状态";
CM_ SG_ 2419523616 BackUp414 "预留";
CM_ SG_ 2419523616 RPDU4_B3_SSPC_I_Load_14 "SSPC14通道电流";
CM_ SG_ 2419523616 RPDU4_B3_SSPC_TripSta_14 "SSPC14跳闸状态";
CM_ SG_ 2419523616 RPDU4_B3_SSPC_BitErr_14 "SSPC14通断周期自检状态";
CM_ SG_ 2419523616 RPDU4_B3_SSPC_OnOffSta_14 "SSPC14通断状态";
CM_ SG_ 2419523616 RPDU4_B3_SSPC_DianHuErr_14 "SSPC14电弧故障状态";
CM_ SG_ 2419523616 BackUp413 "预留";
CM_ SG_ 2419523616 RPDU4_B3_SSPC_I_Load_13 "SSPC13通道电流";
CM_ SG_ 2419523616 RPDU4_B3_SSPC_TripSta_13 "SSPC13跳闸状态";
CM_ SG_ 2419523616 RPDU4_B3_SSPC_BitErr_13 "SSPC13通断周期自检状态";
CM_ SG_ 2419523616 RPDU4_B3_SSPC_OnOffSta_13 "SSPC13通断状态";
CM_ SG_ 2419523616 RPDU4_B3_SSPC_DianHuErr_13 "SSPC13电弧故障状态";
CM_ SG_ 2419523616 BackUp412 "预留";
CM_ SG_ 2419458080 RPDU4_B3_SSPC_I_Load_12 "SSPC12通道电流";
CM_ SG_ 2419458080 RPDU4_B3_SSPC_TripSta_12 "SSPC12跳闸状态";
CM_ SG_ 2419458080 RPDU4_B3_SSPC_BitErr_12 "SSPC12通断周期自检状态";
CM_ SG_ 2419458080 RPDU4_B3_SSPC_OnOffSta_12 "SSPC12通断状态";
CM_ SG_ 2419458080 RPDU4_B3_SSPC_DianHuErr_12 "SSPC12电弧故障状态";
CM_ SG_ 2419458080 BackUp411 "预留";
CM_ SG_ 2419458080 RPDU4_B3_SSPC_I_Load_11 "SSPC11通道电流";
CM_ SG_ 2419458080 RPDU4_B3_SSPC_TripSta_11 "SSPC11跳闸状态";
CM_ SG_ 2419458080 RPDU4_B3_SSPC_BitErr_11 "SSPC11通断周期自检状态";
CM_ SG_ 2419458080 RPDU4_B3_SSPC_OnOffSta_11 "SSPC11通断状态";
CM_ SG_ 2419458080 RPDU4_B3_SSPC_DianHuErr_11 "SSPC11电弧故障状态";
CM_ SG_ 2419458080 BackUp410 "预留";
CM_ SG_ 2419458080 RPDU4_B3_SSPC_I_Load_10 "SSPC10通道电流";
CM_ SG_ 2419458080 RPDU4_B3_SSPC_TripSta_10 "SSPC10跳闸状态";
CM_ SG_ 2419458080 RPDU4_B3_SSPC_BitErr_10 "SSPC10通断周期自检状态";
CM_ SG_ 2419458080 RPDU4_B3_SSPC_OnOffSta_10 "SSPC10通断状态";
CM_ SG_ 2419458080 RPDU4_B3_SSPC_DianHuErr_10 "SSPC10电弧故障状态";
CM_ SG_ 2419458080 BackUp409 "预留";
CM_ SG_ 2419458080 RPDU4_B3_SSPC_I_Load_09 "SSPC9通道电流";
CM_ SG_ 2419458080 RPDU4_B3_SSPC_TripSta_09 "SSPC9跳闸状态";
CM_ SG_ 2419458080 RPDU4_B3_SSPC_BitErr_09 "SSPC9通断周期自检状态";
CM_ SG_ 2419458080 RPDU4_B3_SSPC_OnOffSta_09 "SSPC9通断状态";
CM_ SG_ 2419458080 RPDU4_B3_SSPC_DianHuErr_09 "SSPC9电弧故障状态";
CM_ SG_ 2419458080 BackUp408 "预留";
CM_ SG_ 2419392544 RPDU4_B3_SSPC_I_Load_08 "SSPC8通道电流";
CM_ SG_ 2419392544 RPDU4_B3_SSPC_TripSta_08 "SSPC8跳闸状态";
CM_ SG_ 2419392544 RPDU4_B3_SSPC_BitErr_08 "SSPC8通断周期自检状态";
CM_ SG_ 2419392544 RPDU4_B3_SSPC_OnOffSta_08 "SSPC8通断状态";
CM_ SG_ 2419392544 RPDU4_B3_SSPC_DianHuErr_08 "SSPC8电弧故障状态";
CM_ SG_ 2419392544 BackUp407 "预留";
CM_ SG_ 2419392544 RPDU4_B3_SSPC_I_Load_07 "SSPC7通道电流";
CM_ SG_ 2419392544 RPDU4_B3_SSPC_TripSta_07 "SSPC7跳闸状态";
CM_ SG_ 2419392544 RPDU4_B3_SSPC_BitErr_07 "SSPC7通断周期自检状态";
CM_ SG_ 2419392544 RPDU4_B3_SSPC_OnOffSta_07 "SSPC7通断状态";
CM_ SG_ 2419392544 RPDU4_B3_SSPC_DianHuErr_07 "SSPC7电弧故障状态";
CM_ SG_ 2419392544 BackUp406 "预留";
CM_ SG_ 2419392544 RPDU4_B3_SSPC_I_Load_06 "SSPC6通道电流";
CM_ SG_ 2419392544 RPDU4_B3_SSPC_TripSta_06 "SSPC6跳闸状态";
CM_ SG_ 2419392544 RPDU4_B3_SSPC_BitErr_06 "SSPC6通断周期自检状态";
CM_ SG_ 2419392544 RPDU4_B3_SSPC_OnOffSta_06 "SSPC6通断状态";
CM_ SG_ 2419392544 RPDU4_B3_SSPC_DianHuErr_06 "SSPC6电弧故障状态";
CM_ SG_ 2419392544 BackUp405 "预留";
CM_ SG_ 2419392544 RPDU4_B3_SSPC_I_Load_05 "SSPC5通道电流";
CM_ SG_ 2419392544 RPDU4_B3_SSPC_TripSta_05 "SSPC5跳闸状态";
CM_ SG_ 2419392544 RPDU4_B3_SSPC_BitErr_05 "SSPC5通断周期自检状态";
CM_ SG_ 2419392544 RPDU4_B3_SSPC_OnOffSta_05 "SSPC5通断状态";
CM_ SG_ 2419392544 RPDU4_B3_SSPC_DianHuErr_05 "SSPC5电弧故障状态";
CM_ SG_ 2419392544 BackUp404 "预留";
CM_ SG_ 2419327008 RPDU4_B3_SSPC_I_Load_04 "SSPC4通道电流";
CM_ SG_ 2419327008 RPDU4_B3_SSPC_TripSta_04 "SSPC4跳闸状态";
CM_ SG_ 2419327008 RPDU4_B3_SSPC_BitErr_04 "SSPC4通断周期自检状态";
CM_ SG_ 2419327008 RPDU4_B3_SSPC_OnOffSta_04 "SSPC4通断状态";
CM_ SG_ 2419327008 RPDU4_B3_SSPC_DianHuErr_04 "SSPC4电弧故障状态";
CM_ SG_ 2419327008 BackUp403 "预留";
CM_ SG_ 2419327008 RPDU4_B3_SSPC_I_Load_03 "SSPC3通道电流";
CM_ SG_ 2419327008 RPDU4_B3_SSPC_TripSta_03 "SSPC3跳闸状态";
CM_ SG_ 2419327008 RPDU4_B3_SSPC_BitErr_03 "SSPC3通断周期自检状态";
CM_ SG_ 2419327008 RPDU4_B3_SSPC_OnOffSta_03 "SSPC3通断状态";
CM_ SG_ 2419327008 RPDU4_B3_SSPC_DianHuErr_03 "SSPC3电弧故障状态";
CM_ SG_ 2419327008 BackUp402 "预留";
CM_ SG_ 2419327008 RPDU4_B3_SSPC_I_Load_02 "SSPC2通道电流";
CM_ SG_ 2419327008 RPDU4_B3_SSPC_TripSta_02 "SSPC2跳闸状态";
CM_ SG_ 2419327008 RPDU4_B3_SSPC_BitErr_02 "SSPC2通断周期自检状态";
CM_ SG_ 2419327008 RPDU4_B3_SSPC_OnOffSta_02 "SSPC2通断状态";
CM_ SG_ 2419327008 RPDU4_B3_SSPC_DianHuErr_02 "SSPC2电弧故障状态";
CM_ SG_ 2419327008 BackUp401 "预留";
CM_ SG_ 2419327008 RPDU4_B3_SSPC_I_Load_01 "SSPC1通道电流";
CM_ SG_ 2419327008 RPDU4_B3_SSPC_TripSta_01 "SSPC1跳闸状态";
CM_ SG_ 2419327008 RPDU4_B3_SSPC_BitErr_01 "SSPC1通断周期自检状态";
CM_ SG_ 2419327008 RPDU4_B3_SSPC_OnOffSta_01 "SSPC1通断状态";
CM_ SG_ 2419327008 RPDU4_B3_SSPC_DianHuErr_01 "SSPC1电弧故障状态";
CM_ SG_ 2419327008 BackUp400 "预留";
CM_ SG_ 2419261472 BackUp399 "预留";
CM_ SG_ 2419261472 BackUp398 "预留";
CM_ SG_ 2419261472 BackUp397 "预留";
CM_ SG_ 2419261472 BackUp396 "预留";
CM_ SG_ 2419261472 RPDU4_B2_SSPC_I_Load_18 "SSPC18通道电流";
CM_ SG_ 2419261472 RPDU4_B2_SSPC_TripSta_18 "SSPC18跳闸状态";
CM_ SG_ 2419261472 RPDU4_B2_SSPC_BitErr_18 "SSPC18通断周期自检状态";
CM_ SG_ 2419261472 RPDU4_B2_SSPC_OnOffSta_18 "SSPC18通断状态";
CM_ SG_ 2419261472 RPDU4_B2_SSPC_DianHuErr_18 "SSPC18电弧故障状态";
CM_ SG_ 2419261472 BackUp395 "预留";
CM_ SG_ 2419261472 RPDU4_B2_SSPC_I_Load_17 "SSPC17通道电流";
CM_ SG_ 2419261472 RPDU4_B2_SSPC_TripSta_17 "SSPC17跳闸状态";
CM_ SG_ 2419261472 RPDU4_B2_SSPC_BitErr_17 "SSPC17通断周期自检状态";
CM_ SG_ 2419261472 RPDU4_B2_SSPC_OnOffSta_17 "SSPC17通断状态";
CM_ SG_ 2419261472 RPDU4_B2_SSPC_DianHuErr_17 "SSPC17电弧故障状态";
CM_ SG_ 2419261472 BackUp394 "预留";
CM_ SG_ 2419195936 RPDU4_B2_SSPC_I_Load_16 "SSPC16通道电流";
CM_ SG_ 2419195936 RPDU4_B2_SSPC_TripSta_16 "SSPC16跳闸状态";
CM_ SG_ 2419195936 RPDU4_B2_SSPC_BitErr_16 "SSPC16通断周期自检状态";
CM_ SG_ 2419195936 RPDU4_B2_SSPC_OnOffSta_16 "SSPC16通断状态";
CM_ SG_ 2419195936 RPDU4_B2_SSPC_DianHuErr_16 "SSPC16电弧故障状态";
CM_ SG_ 2419195936 BackUp393 "预留";
CM_ SG_ 2419195936 RPDU4_B2_SSPC_I_Load_15 "SSPC15通道电流";
CM_ SG_ 2419195936 RPDU4_B2_SSPC_TripSta_15 "SSPC15跳闸状态";
CM_ SG_ 2419195936 RPDU4_B2_SSPC_BitErr_15 "SSPC15通断周期自检状态";
CM_ SG_ 2419195936 RPDU4_B2_SSPC_OnOffSta_15 "SSPC15通断状态";
CM_ SG_ 2419195936 RPDU4_B2_SSPC_DianHuErr_15 "SSPC15电弧故障状态";
CM_ SG_ 2419195936 BackUp392 "预留";
CM_ SG_ 2419195936 RPDU4_B2_SSPC_I_Load_14 "SSPC14通道电流";
CM_ SG_ 2419195936 RPDU4_B2_SSPC_TripSta_14 "SSPC14跳闸状态";
CM_ SG_ 2419195936 RPDU4_B2_SSPC_BitErr_14 "SSPC14通断周期自检状态";
CM_ SG_ 2419195936 RPDU4_B2_SSPC_OnOffSta_14 "SSPC14通断状态";
CM_ SG_ 2419195936 RPDU4_B2_SSPC_DianHuErr_14 "SSPC14电弧故障状态";
CM_ SG_ 2419195936 BackUp391 "预留";
CM_ SG_ 2419195936 RPDU4_B2_SSPC_I_Load_13 "SSPC13通道电流";
CM_ SG_ 2419195936 RPDU4_B2_SSPC_TripSta_13 "SSPC13跳闸状态";
CM_ SG_ 2419195936 RPDU4_B2_SSPC_BitErr_13 "SSPC13通断周期自检状态";
CM_ SG_ 2419195936 RPDU4_B2_SSPC_OnOffSta_13 "SSPC13通断状态";
CM_ SG_ 2419195936 RPDU4_B2_SSPC_DianHuErr_13 "SSPC13电弧故障状态";
CM_ SG_ 2419195936 BackUp390 "预留";
CM_ SG_ 2419130400 RPDU4_B2_SSPC_I_Load_12 "SSPC12通道电流";
CM_ SG_ 2419130400 RPDU4_B2_SSPC_TripSta_12 "SSPC12跳闸状态";
CM_ SG_ 2419130400 RPDU4_B2_SSPC_BitErr_12 "SSPC12通断周期自检状态";
CM_ SG_ 2419130400 RPDU4_B2_SSPC_OnOffSta_12 "SSPC12通断状态";
CM_ SG_ 2419130400 RPDU4_B2_SSPC_DianHuErr_12 "SSPC12电弧故障状态";
CM_ SG_ 2419130400 BackUp389 "预留";
CM_ SG_ 2419130400 RPDU4_B2_SSPC_I_Load_11 "SSPC11通道电流";
CM_ SG_ 2419130400 RPDU4_B2_SSPC_TripSta_11 "SSPC11跳闸状态";
CM_ SG_ 2419130400 RPDU4_B2_SSPC_BitErr_11 "SSPC11通断周期自检状态";
CM_ SG_ 2419130400 RPDU4_B2_SSPC_OnOffSta_11 "SSPC11通断状态";
CM_ SG_ 2419130400 RPDU4_B2_SSPC_DianHuErr_11 "SSPC11电弧故障状态";
CM_ SG_ 2419130400 BackUp388 "预留";
CM_ SG_ 2419130400 RPDU4_B2_SSPC_I_Load_10 "SSPC10通道电流";
CM_ SG_ 2419130400 RPDU4_B2_SSPC_TripSta_10 "SSPC10跳闸状态";
CM_ SG_ 2419130400 RPDU4_B2_SSPC_BitErr_10 "SSPC10通断周期自检状态";
CM_ SG_ 2419130400 RPDU4_B2_SSPC_OnOffSta_10 "SSPC10通断状态";
CM_ SG_ 2419130400 RPDU4_B2_SSPC_DianHuErr_10 "SSPC10电弧故障状态";
CM_ SG_ 2419130400 BackUp387 "预留";
CM_ SG_ 2419130400 RPDU4_B2_SSPC_I_Load_09 "SSPC9通道电流";
CM_ SG_ 2419130400 RPDU4_B2_SSPC_TripSta_09 "SSPC9跳闸状态";
CM_ SG_ 2419130400 RPDU4_B2_SSPC_BitErr_09 "SSPC9通断周期自检状态";
CM_ SG_ 2419130400 RPDU4_B2_SSPC_OnOffSta_09 "SSPC9通断状态";
CM_ SG_ 2419130400 RPDU4_B2_SSPC_DianHuErr_09 "SSPC9电弧故障状态";
CM_ SG_ 2419130400 BackUp386 "预留";
CM_ SG_ 2419064864 RPDU4_B2_SSPC_I_Load_08 "SSPC8通道电流";
CM_ SG_ 2419064864 RPDU4_B2_SSPC_TripSta_08 "SSPC8跳闸状态";
CM_ SG_ 2419064864 RPDU4_B2_SSPC_BitErr_08 "SSPC8通断周期自检状态";
CM_ SG_ 2419064864 RPDU4_B2_SSPC_OnOffSta_08 "SSPC8通断状态";
CM_ SG_ 2419064864 RPDU4_B2_SSPC_DianHuErr_08 "SSPC8电弧故障状态";
CM_ SG_ 2419064864 BackUp385 "预留";
CM_ SG_ 2419064864 RPDU4_B2_SSPC_I_Load_07 "SSPC7通道电流";
CM_ SG_ 2419064864 RPDU4_B2_SSPC_TripSta_07 "SSPC7跳闸状态";
CM_ SG_ 2419064864 RPDU4_B2_SSPC_BitErr_07 "SSPC7通断周期自检状态";
CM_ SG_ 2419064864 RPDU4_B2_SSPC_OnOffSta_07 "SSPC7通断状态";
CM_ SG_ 2419064864 RPDU4_B2_SSPC_DianHuErr_07 "SSPC7电弧故障状态";
CM_ SG_ 2419064864 BackUp384 "预留";
CM_ SG_ 2419064864 RPDU4_B2_SSPC_I_Load_06 "SSPC6通道电流";
CM_ SG_ 2419064864 RPDU4_B2_SSPC_TripSta_06 "SSPC6跳闸状态";
CM_ SG_ 2419064864 RPDU4_B2_SSPC_BitErr_06 "SSPC6通断周期自检状态";
CM_ SG_ 2419064864 RPDU4_B2_SSPC_OnOffSta_06 "SSPC6通断状态";
CM_ SG_ 2419064864 RPDU4_B2_SSPC_DianHuErr_06 "SSPC6电弧故障状态";
CM_ SG_ 2419064864 BackUp383 "预留";
CM_ SG_ 2419064864 RPDU4_B2_SSPC_I_Load_05 "SSPC5通道电流";
CM_ SG_ 2419064864 RPDU4_B2_SSPC_TripSta_05 "SSPC5跳闸状态";
CM_ SG_ 2419064864 RPDU4_B2_SSPC_BitErr_05 "SSPC5通断周期自检状态";
CM_ SG_ 2419064864 RPDU4_B2_SSPC_OnOffSta_05 "SSPC5通断状态";
CM_ SG_ 2419064864 RPDU4_B2_SSPC_DianHuErr_05 "SSPC5电弧故障状态";
CM_ SG_ 2419064864 BackUp382 "预留";
CM_ SG_ 2418999328 RPDU4_B2_SSPC_I_Load_04 "SSPC4通道电流";
CM_ SG_ 2418999328 RPDU4_B2_SSPC_TripSta_04 "SSPC4跳闸状态";
CM_ SG_ 2418999328 RPDU4_B2_SSPC_BitErr_04 "SSPC4通断周期自检状态";
CM_ SG_ 2418999328 RPDU4_B2_SSPC_OnOffSta_04 "SSPC4通断状态";
CM_ SG_ 2418999328 RPDU4_B2_SSPC_DianHuErr_04 "SSPC4电弧故障状态";
CM_ SG_ 2418999328 BackUp381 "预留";
CM_ SG_ 2418999328 RPDU4_B2_SSPC_I_Load_03 "SSPC3通道电流";
CM_ SG_ 2418999328 RPDU4_B2_SSPC_TripSta_03 "SSPC3跳闸状态";
CM_ SG_ 2418999328 RPDU4_B2_SSPC_BitErr_03 "SSPC3通断周期自检状态";
CM_ SG_ 2418999328 RPDU4_B2_SSPC_OnOffSta_03 "SSPC3通断状态";
CM_ SG_ 2418999328 RPDU4_B2_SSPC_DianHuErr_03 "SSPC3电弧故障状态";
CM_ SG_ 2418999328 BackUp380 "预留";
CM_ SG_ 2418999328 RPDU4_B2_SSPC_I_Load_02 "SSPC2通道电流";
CM_ SG_ 2418999328 RPDU4_B2_SSPC_TripSta_02 "SSPC2跳闸状态";
CM_ SG_ 2418999328 RPDU4_B2_SSPC_BitErr_02 "SSPC2通断周期自检状态";
CM_ SG_ 2418999328 RPDU4_B2_SSPC_OnOffSta_02 "SSPC2通断状态";
CM_ SG_ 2418999328 RPDU4_B2_SSPC_DianHuErr_02 "SSPC2电弧故障状态";
CM_ SG_ 2418999328 BackUp379 "预留";
CM_ SG_ 2418999328 RPDU4_B2_SSPC_I_Load_01 "SSPC1通道电流";
CM_ SG_ 2418999328 RPDU4_B2_SSPC_TripSta_01 "SSPC1跳闸状态";
CM_ SG_ 2418999328 RPDU4_B2_SSPC_BitErr_01 "SSPC1通断周期自检状态";
CM_ SG_ 2418999328 RPDU4_B2_SSPC_OnOffSta_01 "SSPC1通断状态";
CM_ SG_ 2418999328 RPDU4_B2_SSPC_DianHuErr_01 "SSPC1电弧故障状态";
CM_ SG_ 2418999328 BackUp378 "预留";
BA_DEF_ BU_  "TimeQuantaCANFDMax" INT 4 257;
BA_DEF_ BU_  "TimeQuantaCANFDMin" INT 4 257;
BA_DEF_ BU_  "TimeQuantaMax" INT 4 257;
BA_DEF_ BU_  "TimeQuantaMin" INT 4 257;
BA_DEF_ BU_  "SSPOffsetCANFDMax" FLOAT 50 99.9;
BA_DEF_ BU_  "SSPOffsetCANFDMin" FLOAT 50 99.9;
BA_DEF_ BU_  "SamplePointCANFDMax" FLOAT 50 99.9;
BA_DEF_ BU_  "SamplePointCANFDMin" FLOAT 50 99.9;
BA_DEF_ BU_  "SyncJumpWidthCANFDMax" FLOAT 0 50;
BA_DEF_ BU_  "SyncJumpWidthCANFDMin" FLOAT 0 50;
BA_DEF_  "BaudrateCANFD" INT 1 16000000;
BA_DEF_ SG_  "GenSigSwitchedByIgnition" ENUM  "No","Yes";
BA_DEF_ SG_  "GenSigFuncType" ENUM  "NoFunction","MsgCounter","CRC-8","XOR","XOR-2","DatedBit","SW-Kl15","CHK","Constant","Protocol","CRC-8-SAE_J1850","CRC-32","DataLength","DataID","MsgCounter16","SOK-Signatur","Cluster";
BA_DEF_ BO_  "MsgType" ENUM  "Application","NM ","NMH","TP2.0","ISO-TP ","BAP","EID","KS","XCP_PRE_CONFIGURED","XCP_RUNTIME_CONFIGURED";
BA_DEF_ BU_  "NmhNode" ENUM  "No","Yes";
BA_DEF_ BU_  "ECUVariantDefault" ENUM  "No","Yes";
BA_DEF_ BU_  "GenNodAutoGenSnd" ENUM  "No","Yes";
BA_DEF_ BU_  "GenNodAutoGenDsp" ENUM  "No","Yes";
BA_DEF_  "NmhLongTimer" INT 0 65535;
BA_DEF_  "NmhPrepareBusSleepTimer" INT 0 65535;
BA_DEF_  "NmhWaitBusSleepTimer" INT 0 65535;
BA_DEF_  "NmhTimeoutTimer" INT 0 65535;
BA_DEF_  "NBTMax" INT 1 30;
BA_DEF_  "NBTMin" INT 1 30;
BA_DEF_  "SyncJumpWidthMax" INT 1 4;
BA_DEF_  "SyncJumpWidthMin" INT 1 4;
BA_DEF_  "SamplePointMax" INT 1 100;
BA_DEF_  "SamplePointMin" INT 1 100;
BA_DEF_  "Baudrate" INT 1 1000000;
BA_DEF_  "VersionYear" INT 0 99;
BA_DEF_  "VersionWeek" INT 1 52;
BA_DEF_  "VersionMonth" INT 1 12;
BA_DEF_  "VersionDay" INT 1 31;
BA_DEF_  "NmhMessageCount" INT 0 1024;
BA_DEF_  "NmhBaseAddress" HEX 0 536870911;
BA_DEF_  "Manufacturer" STRING ;
BA_DEF_  "DBName" STRING ;
BA_DEF_  "BusType" STRING ;
BA_DEF_  "GenEnvVarEndingDsp" STRING ;
BA_DEF_  "GenEnvVarEndingSnd" STRING ;
BA_DEF_  "GenEnvVarPrefix" STRING ;
BA_DEF_  "GenNWMApBusSleep" STRING ;
BA_DEF_  "GenNWMApCanNormal" STRING ;
BA_DEF_  "GenNWMApCanOff" STRING ;
BA_DEF_  "GenNWMApCanOn" STRING ;
BA_DEF_  "GenNWMApCanSleep" STRING ;
BA_DEF_  "GenNWMApCanWakeUp" STRING ;
BA_DEF_  "GenNWMGotoMode_Awake" STRING ;
BA_DEF_  "GenNWMGotoMode_BusSleep" STRING ;
BA_DEF_  "GenNWMTalkNM" STRING ;
BA_DEF_ BU_  "NodeLayerModules" STRING ;
BA_DEF_ BU_  "ILUsed" ENUM  "No","Yes";
BA_DEF_ BO_  "GenMsgILSupport" ENUM  "No","Yes";
BA_DEF_ BO_  "GenMsgCycleTime" INT 0 65535;
BA_DEF_ BO_  "GenMsgMinAcceptLength" INT 0 8;
BA_DEF_ BO_  "GenMsgSendType" ENUM  "Cyclic","CyclicAndSpontanX","Event";
BA_DEF_ BO_  "CANFD_BRS" ENUM  "0","1";
BA_DEF_ BO_  "VFrameFormat" ENUM  "StandardCAN","ExtendedCAN","reserved","reserved","reserved","reserved","reserved","reserved","reserved","reserved","reserved","reserved","reserved","reserved","StandardCAN_FD","ExtendedCAN_FD";
BA_DEF_ SG_  "GenSigEnvVarType" ENUM  "undef","int","float";
BA_DEF_ SG_  "GenSigSendType" ENUM  "Cyclic","OnWrite","OnWriteWithRepetition","OnChange","OnChangeWithRepetition","IfActive","IfActiveWithRepetition","NoSigSendType","NotUsed","NotUsed","NotUsed","NotUsed","NotUsed";
BA_DEF_ SG_  "GenSigStartValue" FLOAT 0 1215752192;
BA_DEF_DEF_  "TimeQuantaCANFDMax" 40;
BA_DEF_DEF_  "TimeQuantaCANFDMin" 40;
BA_DEF_DEF_  "TimeQuantaMax" 160;
BA_DEF_DEF_  "TimeQuantaMin" 160;
BA_DEF_DEF_  "SSPOffsetCANFDMax" 75;
BA_DEF_DEF_  "SSPOffsetCANFDMin" 75;
BA_DEF_DEF_  "SamplePointCANFDMax" 75;
BA_DEF_DEF_  "SamplePointCANFDMin" 75;
BA_DEF_DEF_  "SyncJumpWidthCANFDMax" 50;
BA_DEF_DEF_  "SyncJumpWidthCANFDMin" 50;
BA_DEF_DEF_  "BaudrateCANFD" 2000000;
BA_DEF_DEF_  "GenSigSwitchedByIgnition" "Yes";
BA_DEF_DEF_  "GenSigFuncType" "NoFunction";
BA_DEF_DEF_  "MsgType" "Application";
BA_DEF_DEF_  "NmhNode" "Yes";
BA_DEF_DEF_  "ECUVariantDefault" "Yes";
BA_DEF_DEF_  "GenNodAutoGenSnd" "Yes";
BA_DEF_DEF_  "GenNodAutoGenDsp" "Yes";
BA_DEF_DEF_  "NmhLongTimer" 0;
BA_DEF_DEF_  "NmhPrepareBusSleepTimer" 2000;
BA_DEF_DEF_  "NmhWaitBusSleepTimer" 5000;
BA_DEF_DEF_  "NmhTimeoutTimer" 2000;
BA_DEF_DEF_  "NBTMax" 20;
BA_DEF_DEF_  "NBTMin" 10;
BA_DEF_DEF_  "SyncJumpWidthMax" 1;
BA_DEF_DEF_  "SyncJumpWidthMin" 1;
BA_DEF_DEF_  "SamplePointMax" 1;
BA_DEF_DEF_  "SamplePointMin" 1;
BA_DEF_DEF_  "Baudrate" 500000;
BA_DEF_DEF_  "VersionYear" 19;
BA_DEF_DEF_  "VersionWeek" 45;
BA_DEF_DEF_  "VersionMonth" 11;
BA_DEF_DEF_  "VersionDay" 8;
BA_DEF_DEF_  "NmhMessageCount" 1;
BA_DEF_DEF_  "NmhBaseAddress" 0;
BA_DEF_DEF_  "Manufacturer" "GWM";
BA_DEF_DEF_  "DBName" "V51EV_for_PT_CANFD V1_0交流版";
BA_DEF_DEF_  "BusType" "";
BA_DEF_DEF_  "GenEnvVarEndingDsp" "_d";
BA_DEF_DEF_  "GenEnvVarEndingSnd" "_s";
BA_DEF_DEF_  "GenEnvVarPrefix" "c";
BA_DEF_DEF_  "GenNWMApBusSleep" "apBusSleep()";
BA_DEF_DEF_  "GenNWMApCanNormal" "apCanNormal()";
BA_DEF_DEF_  "GenNWMApCanOff" "apCanOff()";
BA_DEF_DEF_  "GenNWMApCanOn" "apCanOn()";
BA_DEF_DEF_  "GenNWMApCanSleep" "apCanSleep()";
BA_DEF_DEF_  "GenNWMApCanWakeUp" "apCanWakeUp()";
BA_DEF_DEF_  "GenNWMGotoMode_Awake" "GotoMode_Awake()";
BA_DEF_DEF_  "GenNWMGotoMode_BusSleep" "GotoMode_BusSleep()";
BA_DEF_DEF_  "GenNWMTalkNM" "TalkNM()";
BA_DEF_DEF_  "NodeLayerModules" "CANoeILNLVector.dll";
BA_DEF_DEF_  "ILUsed" "Yes";
BA_DEF_DEF_  "GenMsgILSupport" "Yes";
BA_DEF_DEF_  "GenMsgCycleTime" 10;
BA_DEF_DEF_  "GenMsgMinAcceptLength" 8;
BA_DEF_DEF_  "GenMsgSendType" "Cyclic";
BA_DEF_DEF_  "CANFD_BRS" "1";
BA_DEF_DEF_  "VFrameFormat" "StandardCAN";
BA_DEF_DEF_  "GenSigEnvVarType" "undef";
BA_DEF_DEF_  "GenSigSendType" "Cyclic";
BA_DEF_DEF_  "GenSigStartValue" 0;
BA_ "NmhLongTimer" 200;
BA_ "NmhPrepareBusSleepTimer" 100;
BA_ "NmhWaitBusSleepTimer" 2000;
BA_ "SyncJumpWidthMax" 4;
BA_ "SyncJumpWidthMin" 2;
BA_ "NmhMessageCount" 256;
BA_ "NmhBaseAddress" 1280;
BA_ "BusType" "CAN";
BA_ "DBName" "DBCNetWork";
BA_ "GenMsgCycleTime" BO_ 2416254976 100;
BA_ "VFrameFormat" BO_ 2416254976 1;
BA_ "GenMsgCycleTime" BO_ 2416189440 100;
BA_ "VFrameFormat" BO_ 2416189440 1;
BA_ "GenMsgCycleTime" BO_ 2416123904 100;
BA_ "VFrameFormat" BO_ 2416123904 1;
BA_ "GenMsgCycleTime" BO_ 2416058368 100;
BA_ "VFrameFormat" BO_ 2416058368 1;
BA_ "GenMsgCycleTime" BO_ 2415992832 100;
BA_ "VFrameFormat" BO_ 2415992832 1;
BA_ "GenMsgCycleTime" BO_ 2416250880 100;
BA_ "VFrameFormat" BO_ 2416250880 1;
BA_ "GenMsgCycleTime" BO_ 2416185344 100;
BA_ "VFrameFormat" BO_ 2416185344 1;
BA_ "GenMsgCycleTime" BO_ 2416119808 100;
BA_ "VFrameFormat" BO_ 2416119808 1;
BA_ "GenMsgCycleTime" BO_ 2416054272 100;
BA_ "VFrameFormat" BO_ 2416054272 1;
BA_ "GenMsgCycleTime" BO_ 2415988736 100;
BA_ "VFrameFormat" BO_ 2415988736 1;
BA_ "VFrameFormat" BO_ 2421178416 1;
BA_ "GenMsgCycleTime" BO_ 2416181296 100;
BA_ "VFrameFormat" BO_ 2416181296 1;
BA_ "GenMsgCycleTime" BO_ 2416640048 100;
BA_ "VFrameFormat" BO_ 2416640048 1;
BA_ "GenMsgCycleTime" BO_ 2416574512 100;
BA_ "VFrameFormat" BO_ 2416574512 1;
BA_ "GenMsgCycleTime" BO_ 2416508976 100;
BA_ "VFrameFormat" BO_ 2416508976 1;
BA_ "GenMsgCycleTime" BO_ 2416443440 100;
BA_ "VFrameFormat" BO_ 2416443440 1;
BA_ "GenMsgCycleTime" BO_ 2416377904 100;
BA_ "VFrameFormat" BO_ 2416377904 1;
BA_ "GenMsgCycleTime" BO_ 2416312368 100;
BA_ "VFrameFormat" BO_ 2416312368 1;
BA_ "GenMsgCycleTime" BO_ 2416246832 100;
BA_ "VFrameFormat" BO_ 2416246832 1;
BA_ "GenMsgCycleTime" BO_ 2416115760 100;
BA_ "VFrameFormat" BO_ 2416115760 1;
BA_ "GenMsgCycleTime" BO_ 2416050224 100;
BA_ "VFrameFormat" BO_ 2416050224 1;
BA_ "GenMsgCycleTime" BO_ 2415984688 100;
BA_ "VFrameFormat" BO_ 2415984688 1;
BA_ "VFrameFormat" BO_ 2421178400 1;
BA_ "GenMsgCycleTime" BO_ 2420244512 400;
BA_ "VFrameFormat" BO_ 2420244512 1;
BA_ "GenMsgCycleTime" BO_ 2420178976 400;
BA_ "VFrameFormat" BO_ 2420178976 1;
BA_ "GenMsgCycleTime" BO_ 2420113440 400;
BA_ "VFrameFormat" BO_ 2420113440 1;
BA_ "GenMsgCycleTime" BO_ 2420047904 400;
BA_ "VFrameFormat" BO_ 2420047904 1;
BA_ "GenMsgCycleTime" BO_ 2419982368 400;
BA_ "VFrameFormat" BO_ 2419982368 1;
BA_ "GenMsgCycleTime" BO_ 2419916832 400;
BA_ "VFrameFormat" BO_ 2419916832 1;
BA_ "GenMsgCycleTime" BO_ 2419851296 400;
BA_ "VFrameFormat" BO_ 2419851296 1;
BA_ "GenMsgCycleTime" BO_ 2419785760 400;
BA_ "VFrameFormat" BO_ 2419785760 1;
BA_ "GenMsgCycleTime" BO_ 2419720224 400;
BA_ "VFrameFormat" BO_ 2419720224 1;
BA_ "GenMsgCycleTime" BO_ 2419654688 400;
BA_ "VFrameFormat" BO_ 2419654688 1;
BA_ "GenMsgCycleTime" BO_ 2419589152 400;
BA_ "VFrameFormat" BO_ 2419589152 1;
BA_ "GenMsgCycleTime" BO_ 2419523616 400;
BA_ "VFrameFormat" BO_ 2419523616 1;
BA_ "GenMsgCycleTime" BO_ 2419458080 400;
BA_ "VFrameFormat" BO_ 2419458080 1;
BA_ "GenMsgCycleTime" BO_ 2419392544 400;
BA_ "VFrameFormat" BO_ 2419392544 1;
BA_ "GenMsgCycleTime" BO_ 2419327008 400;
BA_ "VFrameFormat" BO_ 2419327008 1;
BA_ "GenMsgCycleTime" BO_ 2419261472 400;
BA_ "VFrameFormat" BO_ 2419261472 1;
BA_ "GenMsgCycleTime" BO_ 2419195936 400;
BA_ "VFrameFormat" BO_ 2419195936 1;
BA_ "GenMsgCycleTime" BO_ 2419130400 400;
BA_ "VFrameFormat" BO_ 2419130400 1;
BA_ "GenMsgCycleTime" BO_ 2419064864 400;
BA_ "VFrameFormat" BO_ 2419064864 1;
BA_ "GenMsgCycleTime" BO_ 2418999328 400;
BA_ "VFrameFormat" BO_ 2418999328 1;
BA_ "GenSigStartValue" SG_ 2416254976 SSPC_Num_R 1;
BA_ "GenSigStartValue" SG_ 2416254976 Board_Num_R 1;
BA_ "GenSigStartValue" SG_ 2416254976 RPDU_Num_R 1;
BA_ "GenSigStartValue" SG_ 2416250880 SSPC_Num_L 1;
BA_ "GenSigStartValue" SG_ 2416250880 Board_Num_L 1;
BA_ "GenSigStartValue" SG_ 2416250880 RPDU_Num_L 1;
BA_ "GenSigStartValue" SG_ 2416312368 E_ECU_Ver_Day 1;
BA_ "GenSigStartValue" SG_ 2416312368 E_ECU_Ver_Month 1;
VAL_ 2416254976 LED_JiZhong_24 1 "接通" 0 "断开" ;
VAL_ 2416254976 SSPC_Reset_R 0 "不复位" 1 "复位" ;
VAL_ 2416254976 SSPC_Num_R 1 "SSPC1" 2 "SSPC2" 3 "SSPC3" 4 "SSPC4" 5 "SSPC5" 6 "SSPC6" 7 "SSPC7" 8 "SSPC8" 9 "SSPC9" 10 "SSPC10" 11 "SSPC11" 12 "SSPC12" 13 "SSPC13" 14 "SSPC14" 15 "SSPC15" 16 "SSPC16" 17 "SSPC17" 18 "SSPC18" ;
VAL_ 2416254976 Board_Num_R 1 "1号板卡" 2 "2号板卡" 3 "3号板卡" 4 "4号板卡" 5 "5号板卡" 6 "6号板卡" ;
VAL_ 2416254976 RPDU_Num_R 1 "RPDU1" 2 "RPDU2" 3 "RPDU3" 4 "RPUD4" ;
VAL_ 2416189440 RPDU4_B6_SSPC_Order_07 1 "接通" 0 "断开" ;
VAL_ 2416189440 RPDU4_B6_SSPC_Order_06 1 "接通" 0 "断开" ;
VAL_ 2416189440 RPDU4_B6_SSPC_Order_05 1 "接通" 0 "断开" ;
VAL_ 2416189440 RPDU4_B6_SSPC_Order_04 1 "接通" 0 "断开" ;
VAL_ 2416189440 RPDU4_B6_SSPC_Order_03 1 "接通" 0 "断开" ;
VAL_ 2416189440 RPDU4_B6_SSPC_Order_02 1 "接通" 0 "断开" ;
VAL_ 2416189440 RPDU4_B6_SSPC_Order_01 1 "接通" 0 "断开" ;
VAL_ 2416189440 RPDU4_B4_SSPC_Order_18 1 "接通" 0 "断开" ;
VAL_ 2416189440 RPDU4_B4_SSPC_Order_17 1 "接通" 0 "断开" ;
VAL_ 2416189440 RPDU4_B4_SSPC_Order_16 1 "接通" 0 "断开" ;
VAL_ 2416189440 RPDU4_B4_SSPC_Order_15 1 "接通" 0 "断开" ;
VAL_ 2416189440 RPDU4_B4_SSPC_Order_14 1 "接通" 0 "断开" ;
VAL_ 2416189440 RPDU4_B4_SSPC_Order_13 1 "接通" 0 "断开" ;
VAL_ 2416189440 RPDU4_B4_SSPC_Order_12 1 "接通" 0 "断开" ;
VAL_ 2416189440 RPDU4_B4_SSPC_Order_11 1 "接通" 0 "断开" ;
VAL_ 2416189440 RPDU4_B4_SSPC_Order_10 1 "接通" 0 "断开" ;
VAL_ 2416189440 RPDU4_B4_SSPC_Order_09 1 "接通" 0 "断开" ;
VAL_ 2416189440 RPDU4_B4_SSPC_Order_08 1 "接通" 0 "断开" ;
VAL_ 2416189440 RPDU4_B4_SSPC_Order_07 1 "接通" 0 "断开" ;
VAL_ 2416189440 RPDU4_B4_SSPC_Order_06 1 "接通" 0 "断开" ;
VAL_ 2416189440 RPDU4_B4_SSPC_Order_05 1 "接通" 0 "断开" ;
VAL_ 2416189440 RPDU4_B4_SSPC_Order_04 1 "接通" 0 "断开" ;
VAL_ 2416189440 RPDU4_B4_SSPC_Order_03 1 "接通" 0 "断开" ;
VAL_ 2416189440 RPDU4_B4_SSPC_Order_02 1 "接通" 0 "断开" ;
VAL_ 2416189440 RPDU4_B4_SSPC_Order_01 1 "接通" 0 "断开" ;
VAL_ 2416189440 RPDU4_B2_SSPC_Order_18 1 "接通" 0 "断开" ;
VAL_ 2416189440 RPDU4_B2_SSPC_Order_17 1 "接通" 0 "断开" ;
VAL_ 2416189440 RPDU4_B2_SSPC_Order_16 1 "接通" 0 "断开" ;
VAL_ 2416189440 RPDU4_B2_SSPC_Order_15 1 "接通" 0 "断开" ;
VAL_ 2416189440 RPDU4_B2_SSPC_Order_14 1 "接通" 0 "断开" ;
VAL_ 2416189440 RPDU4_B2_SSPC_Order_13 1 "接通" 0 "断开" ;
VAL_ 2416189440 RPDU4_B2_SSPC_Order_12 1 "接通" 0 "断开" ;
VAL_ 2416189440 RPDU4_B2_SSPC_Order_11 1 "接通" 0 "断开" ;
VAL_ 2416189440 RPDU4_B2_SSPC_Order_10 1 "接通" 0 "断开" ;
VAL_ 2416189440 RPDU4_B2_SSPC_Order_09 1 "接通" 0 "断开" ;
VAL_ 2416189440 RPDU4_B2_SSPC_Order_08 1 "接通" 0 "断开" ;
VAL_ 2416189440 RPDU4_B2_SSPC_Order_07 1 "接通" 0 "断开" ;
VAL_ 2416189440 RPDU4_B2_SSPC_Order_06 1 "接通" 0 "断开" ;
VAL_ 2416189440 RPDU4_B2_SSPC_Order_05 1 "接通" 0 "断开" ;
VAL_ 2416189440 RPDU4_B2_SSPC_Order_04 1 "接通" 0 "断开" ;
VAL_ 2416189440 RPDU4_B2_SSPC_Order_03 1 "接通" 0 "断开" ;
VAL_ 2416189440 RPDU4_B2_SSPC_Order_02 1 "接通" 0 "断开" ;
VAL_ 2416189440 RPDU4_B2_SSPC_Order_01 1 "接通" 0 "断开" ;
VAL_ 2416123904 RPDU4_B5_SSPC_Order_07 1 "接通" 0 "断开" ;
VAL_ 2416123904 RPDU4_B5_SSPC_Order_06 1 "接通" 0 "断开" ;
VAL_ 2416123904 RPDU4_B5_SSPC_Order_05 1 "接通" 0 "断开" ;
VAL_ 2416123904 RPDU4_B5_SSPC_Order_04 1 "接通" 0 "断开" ;
VAL_ 2416123904 RPDU4_B5_SSPC_Order_03 1 "接通" 0 "断开" ;
VAL_ 2416123904 RPDU4_B5_SSPC_Order_02 1 "接通" 0 "断开" ;
VAL_ 2416123904 RPDU4_B5_SSPC_Order_01 1 "接通" 0 "断开" ;
VAL_ 2416123904 RPDU4_B3_SSPC_Order_18 1 "接通" 0 "断开" ;
VAL_ 2416123904 RPDU4_B3_SSPC_Order_17 1 "接通" 0 "断开" ;
VAL_ 2416123904 RPDU4_B3_SSPC_Order_16 1 "接通" 0 "断开" ;
VAL_ 2416123904 RPDU4_B3_SSPC_Order_15 1 "接通" 0 "断开" ;
VAL_ 2416123904 RPDU4_B3_SSPC_Order_14 1 "接通" 0 "断开" ;
VAL_ 2416123904 RPDU4_B3_SSPC_Order_13 1 "接通" 0 "断开" ;
VAL_ 2416123904 RPDU4_B3_SSPC_Order_12 1 "接通" 0 "断开" ;
VAL_ 2416123904 RPDU4_B3_SSPC_Order_11 1 "接通" 0 "断开" ;
VAL_ 2416123904 RPDU4_B3_SSPC_Order_10 1 "接通" 0 "断开" ;
VAL_ 2416123904 RPDU4_B3_SSPC_Order_09 1 "接通" 0 "断开" ;
VAL_ 2416123904 RPDU4_B3_SSPC_Order_08 1 "接通" 0 "断开" ;
VAL_ 2416123904 RPDU4_B3_SSPC_Order_07 1 "接通" 0 "断开" ;
VAL_ 2416123904 RPDU4_B3_SSPC_Order_06 1 "接通" 0 "断开" ;
VAL_ 2416123904 RPDU4_B3_SSPC_Order_05 1 "接通" 0 "断开" ;
VAL_ 2416123904 RPDU4_B3_SSPC_Order_04 1 "接通" 0 "断开" ;
VAL_ 2416123904 RPDU4_B3_SSPC_Order_03 1 "接通" 0 "断开" ;
VAL_ 2416123904 RPDU4_B3_SSPC_Order_02 1 "接通" 0 "断开" ;
VAL_ 2416123904 RPDU4_B3_SSPC_Order_01 1 "接通" 0 "断开" ;
VAL_ 2416123904 RPDU4_B1_SSPC_Order_18 1 "接通" 0 "断开" ;
VAL_ 2416123904 RPDU4_B1_SSPC_Order_17 1 "接通" 0 "断开" ;
VAL_ 2416123904 RPDU4_B1_SSPC_Order_16 1 "接通" 0 "断开" ;
VAL_ 2416123904 RPDU4_B1_SSPC_Order_15 1 "接通" 0 "断开" ;
VAL_ 2416123904 RPDU4_B1_SSPC_Order_14 1 "接通" 0 "断开" ;
VAL_ 2416123904 RPDU4_B1_SSPC_Order_13 1 "接通" 0 "断开" ;
VAL_ 2416123904 RPDU4_B1_SSPC_Order_12 1 "接通" 0 "断开" ;
VAL_ 2416123904 RPDU4_B1_SSPC_Order_11 1 "接通" 0 "断开" ;
VAL_ 2416123904 RPDU4_B1_SSPC_Order_10 1 "接通" 0 "断开" ;
VAL_ 2416123904 RPDU4_B1_SSPC_Order_09 1 "接通" 0 "断开" ;
VAL_ 2416123904 RPDU4_B1_SSPC_Order_08 1 "接通" 0 "断开" ;
VAL_ 2416123904 RPDU4_B1_SSPC_Order_07 1 "接通" 0 "断开" ;
VAL_ 2416123904 RPDU4_B1_SSPC_Order_06 1 "接通" 0 "断开" ;
VAL_ 2416123904 RPDU4_B1_SSPC_Order_05 1 "接通" 0 "断开" ;
VAL_ 2416123904 RPDU4_B1_SSPC_Order_04 1 "接通" 0 "断开" ;
VAL_ 2416123904 RPDU4_B1_SSPC_Order_03 1 "接通" 0 "断开" ;
VAL_ 2416123904 RPDU4_B1_SSPC_Order_02 1 "接通" 0 "断开" ;
VAL_ 2416123904 RPDU4_B1_SSPC_Order_01 1 "接通" 0 "断开" ;
VAL_ 2416058368 RPDU2_B6_SSPC_Order_07 1 "接通" 0 "断开" ;
VAL_ 2416058368 RPDU2_B6_SSPC_Order_06 1 "接通" 0 "断开" ;
VAL_ 2416058368 RPDU2_B6_SSPC_Order_05 1 "接通" 0 "断开" ;
VAL_ 2416058368 RPDU2_B6_SSPC_Order_04 1 "接通" 0 "断开" ;
VAL_ 2416058368 RPDU2_B6_SSPC_Order_03 1 "接通" 0 "断开" ;
VAL_ 2416058368 RPDU2_B6_SSPC_Order_02 1 "接通" 0 "断开" ;
VAL_ 2416058368 RPDU2_B6_SSPC_Order_01 1 "接通" 0 "断开" ;
VAL_ 2416058368 RPDU2_B4_SSPC_Order_18 1 "接通" 0 "断开" ;
VAL_ 2416058368 RPDU2_B4_SSPC_Order_17 1 "接通" 0 "断开" ;
VAL_ 2416058368 RPDU2_B4_SSPC_Order_16 1 "接通" 0 "断开" ;
VAL_ 2416058368 RPDU2_B4_SSPC_Order_15 1 "接通" 0 "断开" ;
VAL_ 2416058368 RPDU2_B4_SSPC_Order_14 1 "接通" 0 "断开" ;
VAL_ 2416058368 RPDU2_B4_SSPC_Order_13 1 "接通" 0 "断开" ;
VAL_ 2416058368 RPDU2_B4_SSPC_Order_12 1 "接通" 0 "断开" ;
VAL_ 2416058368 RPDU2_B4_SSPC_Order_11 1 "接通" 0 "断开" ;
VAL_ 2416058368 RPDU2_B4_SSPC_Order_10 1 "接通" 0 "断开" ;
VAL_ 2416058368 RPDU2_B4_SSPC_Order_09 1 "接通" 0 "断开" ;
VAL_ 2416058368 RPDU2_B4_SSPC_Order_08 1 "接通" 0 "断开" ;
VAL_ 2416058368 RPDU2_B4_SSPC_Order_07 1 "接通" 0 "断开" ;
VAL_ 2416058368 RPDU2_B4_SSPC_Order_06 1 "接通" 0 "断开" ;
VAL_ 2416058368 RPDU2_B4_SSPC_Order_05 1 "接通" 0 "断开" ;
VAL_ 2416058368 RPDU2_B4_SSPC_Order_04 1 "接通" 0 "断开" ;
VAL_ 2416058368 RPDU2_B4_SSPC_Order_03 1 "接通" 0 "断开" ;
VAL_ 2416058368 RPDU2_B4_SSPC_Order_02 1 "接通" 0 "断开" ;
VAL_ 2416058368 RPDU2_B4_SSPC_Order_01 1 "接通" 0 "断开" ;
VAL_ 2416058368 RPDU2_B2_SSPC_Order_18 1 "接通" 0 "断开" ;
VAL_ 2416058368 RPDU2_B2_SSPC_Order_17 1 "接通" 0 "断开" ;
VAL_ 2416058368 RPDU2_B2_SSPC_Order_16 1 "接通" 0 "断开" ;
VAL_ 2416058368 RPDU2_B2_SSPC_Order_15 1 "接通" 0 "断开" ;
VAL_ 2416058368 RPDU2_B2_SSPC_Order_14 1 "接通" 0 "断开" ;
VAL_ 2416058368 RPDU2_B2_SSPC_Order_13 1 "接通" 0 "断开" ;
VAL_ 2416058368 RPDU2_B2_SSPC_Order_12 1 "接通" 0 "断开" ;
VAL_ 2416058368 RPDU2_B2_SSPC_Order_11 1 "接通" 0 "断开" ;
VAL_ 2416058368 RPDU2_B2_SSPC_Order_10 1 "接通" 0 "断开" ;
VAL_ 2416058368 RPDU2_B2_SSPC_Order_09 1 "接通" 0 "断开" ;
VAL_ 2416058368 RPDU2_B2_SSPC_Order_08 1 "接通" 0 "断开" ;
VAL_ 2416058368 RPDU2_B2_SSPC_Order_07 1 "接通" 0 "断开" ;
VAL_ 2416058368 RPDU2_B2_SSPC_Order_06 1 "接通" 0 "断开" ;
VAL_ 2416058368 RPDU2_B2_SSPC_Order_05 1 "接通" 0 "断开" ;
VAL_ 2416058368 RPDU2_B2_SSPC_Order_04 1 "接通" 0 "断开" ;
VAL_ 2416058368 RPDU2_B2_SSPC_Order_03 1 "接通" 0 "断开" ;
VAL_ 2416058368 RPDU2_B2_SSPC_Order_02 1 "接通" 0 "断开" ;
VAL_ 2416058368 RPDU2_B2_SSPC_Order_01 1 "接通" 0 "断开" ;
VAL_ 2415992832 RPDU2_B5_SSPC_Order_07 1 "接通" 0 "断开" ;
VAL_ 2415992832 RPDU2_B5_SSPC_Order_06 1 "接通" 0 "断开" ;
VAL_ 2415992832 RPDU2_B5_SSPC_Order_05 1 "接通" 0 "断开" ;
VAL_ 2415992832 RPDU2_B5_SSPC_Order_04 1 "接通" 0 "断开" ;
VAL_ 2415992832 RPDU2_B5_SSPC_Order_03 1 "接通" 0 "断开" ;
VAL_ 2415992832 RPDU2_B5_SSPC_Order_02 1 "接通" 0 "断开" ;
VAL_ 2415992832 RPDU2_B5_SSPC_Order_01 1 "接通" 0 "断开" ;
VAL_ 2415992832 RPDU2_B3_SSPC_Order_18 1 "接通" 0 "断开" ;
VAL_ 2415992832 RPDU2_B3_SSPC_Order_17 1 "接通" 0 "断开" ;
VAL_ 2415992832 RPDU2_B3_SSPC_Order_16 1 "接通" 0 "断开" ;
VAL_ 2415992832 RPDU2_B3_SSPC_Order_15 1 "接通" 0 "断开" ;
VAL_ 2415992832 RPDU2_B3_SSPC_Order_14 1 "接通" 0 "断开" ;
VAL_ 2415992832 RPDU2_B3_SSPC_Order_13 1 "接通" 0 "断开" ;
VAL_ 2415992832 RPDU2_B3_SSPC_Order_12 1 "接通" 0 "断开" ;
VAL_ 2415992832 RPDU2_B3_SSPC_Order_11 1 "接通" 0 "断开" ;
VAL_ 2415992832 RPDU2_B3_SSPC_Order_10 1 "接通" 0 "断开" ;
VAL_ 2415992832 RPDU2_B3_SSPC_Order_09 1 "接通" 0 "断开" ;
VAL_ 2415992832 RPDU2_B3_SSPC_Order_08 1 "接通" 0 "断开" ;
VAL_ 2415992832 RPDU2_B3_SSPC_Order_07 1 "接通" 0 "断开" ;
VAL_ 2415992832 RPDU2_B3_SSPC_Order_06 1 "接通" 0 "断开" ;
VAL_ 2415992832 RPDU2_B3_SSPC_Order_05 1 "接通" 0 "断开" ;
VAL_ 2415992832 RPDU2_B3_SSPC_Order_04 1 "接通" 0 "断开" ;
VAL_ 2415992832 RPDU2_B3_SSPC_Order_03 1 "接通" 0 "断开" ;
VAL_ 2415992832 RPDU2_B3_SSPC_Order_02 1 "接通" 0 "断开" ;
VAL_ 2415992832 RPDU2_B3_SSPC_Order_01 1 "接通" 0 "断开" ;
VAL_ 2415992832 RPDU2_B1_SSPC_Order_18 1 "接通" 0 "断开" ;
VAL_ 2415992832 RPDU2_B1_SSPC_Order_17 1 "接通" 0 "断开" ;
VAL_ 2415992832 RPDU2_B1_SSPC_Order_16 1 "接通" 0 "断开" ;
VAL_ 2415992832 RPDU2_B1_SSPC_Order_15 1 "接通" 0 "断开" ;
VAL_ 2415992832 RPDU2_B1_SSPC_Order_14 1 "接通" 0 "断开" ;
VAL_ 2415992832 RPDU2_B1_SSPC_Order_13 1 "接通" 0 "断开" ;
VAL_ 2415992832 RPDU2_B1_SSPC_Order_12 1 "接通" 0 "断开" ;
VAL_ 2415992832 RPDU2_B1_SSPC_Order_11 1 "接通" 0 "断开" ;
VAL_ 2415992832 RPDU2_B1_SSPC_Order_10 1 "接通" 0 "断开" ;
VAL_ 2415992832 RPDU2_B1_SSPC_Order_09 1 "接通" 0 "断开" ;
VAL_ 2415992832 RPDU2_B1_SSPC_Order_08 1 "接通" 0 "断开" ;
VAL_ 2415992832 RPDU2_B1_SSPC_Order_07 1 "接通" 0 "断开" ;
VAL_ 2415992832 RPDU2_B1_SSPC_Order_06 1 "接通" 0 "断开" ;
VAL_ 2415992832 RPDU2_B1_SSPC_Order_05 1 "接通" 0 "断开" ;
VAL_ 2415992832 RPDU2_B1_SSPC_Order_04 1 "接通" 0 "断开" ;
VAL_ 2415992832 RPDU2_B1_SSPC_Order_03 1 "接通" 0 "断开" ;
VAL_ 2415992832 RPDU2_B1_SSPC_Order_02 1 "接通" 0 "断开" ;
VAL_ 2415992832 RPDU2_B1_SSPC_Order_01 1 "接通" 0 "断开" ;
VAL_ 2416250880 LED_JiZhong_13 1 "接通" 0 "断开" ;
VAL_ 2416250880 SSPC_Reset_L 0 "不复位" 1 "复位" ;
VAL_ 2416250880 SSPC_Num_L 1 "SSPC1" 2 "SSPC2" 3 "SSPC3" 4 "SSPC4" 5 "SSPC5" 6 "SSPC6" 7 "SSPC7" 8 "SSPC8" 9 "SSPC9" 10 "SSPC10" 11 "SSPC11" 12 "SSPC12" 13 "SSPC13" 14 "SSPC14" 15 "SSPC15" 16 "SSPC16" 17 "SSPC17" 18 "SSPC18" ;
VAL_ 2416250880 Board_Num_L 1 "1号板卡" 2 "2号板卡" 3 "3号板卡" 4 "4号板卡" 5 "5号板卡" 6 "6号板卡" ;
VAL_ 2416250880 RPDU_Num_L 1 "RPDU1" 2 "RPDU2" 3 "RPDU3" 4 "RPUD4" ;
VAL_ 2416185344 RPDU3_B6_SSPC_Order_07 1 "接通" 0 "断开" ;
VAL_ 2416185344 RPDU3_B6_SSPC_Order_06 1 "接通" 0 "断开" ;
VAL_ 2416185344 RPDU3_B6_SSPC_Order_05 1 "接通" 0 "断开" ;
VAL_ 2416185344 RPDU3_B6_SSPC_Order_04 1 "接通" 0 "断开" ;
VAL_ 2416185344 RPDU3_B6_SSPC_Order_03 1 "接通" 0 "断开" ;
VAL_ 2416185344 RPDU3_B6_SSPC_Order_02 1 "接通" 0 "断开" ;
VAL_ 2416185344 RPDU3_B6_SSPC_Order_01 1 "接通" 0 "断开" ;
VAL_ 2416185344 RPDU3_B4_SSPC_Order_18 1 "接通" 0 "断开" ;
VAL_ 2416185344 RPDU3_B4_SSPC_Order_17 1 "接通" 0 "断开" ;
VAL_ 2416185344 RPDU3_B4_SSPC_Order_16 1 "接通" 0 "断开" ;
VAL_ 2416185344 RPDU3_B4_SSPC_Order_15 1 "接通" 0 "断开" ;
VAL_ 2416185344 RPDU3_B4_SSPC_Order_14 1 "接通" 0 "断开" ;
VAL_ 2416185344 RPDU3_B4_SSPC_Order_13 1 "接通" 0 "断开" ;
VAL_ 2416185344 RPDU3_B4_SSPC_Order_12 1 "接通" 0 "断开" ;
VAL_ 2416185344 RPDU3_B4_SSPC_Order_11 1 "接通" 0 "断开" ;
VAL_ 2416185344 RPDU3_B4_SSPC_Order_10 1 "接通" 0 "断开" ;
VAL_ 2416185344 RPDU3_B4_SSPC_Order_09 1 "接通" 0 "断开" ;
VAL_ 2416185344 RPDU3_B4_SSPC_Order_08 1 "接通" 0 "断开" ;
VAL_ 2416185344 RPDU3_B4_SSPC_Order_07 1 "接通" 0 "断开" ;
VAL_ 2416185344 RPDU3_B4_SSPC_Order_06 1 "接通" 0 "断开" ;
VAL_ 2416185344 RPDU3_B4_SSPC_Order_05 1 "接通" 0 "断开" ;
VAL_ 2416185344 RPDU3_B4_SSPC_Order_04 1 "接通" 0 "断开" ;
VAL_ 2416185344 RPDU3_B4_SSPC_Order_03 1 "接通" 0 "断开" ;
VAL_ 2416185344 RPDU3_B4_SSPC_Order_02 1 "接通" 0 "断开" ;
VAL_ 2416185344 RPDU3_B4_SSPC_Order_01 1 "接通" 0 "断开" ;
VAL_ 2416185344 RPDU3_B2_SSPC_Order_18 1 "接通" 0 "断开" ;
VAL_ 2416185344 RPDU3_B2_SSPC_Order_17 1 "接通" 0 "断开" ;
VAL_ 2416185344 RPDU3_B2_SSPC_Order_16 1 "接通" 0 "断开" ;
VAL_ 2416185344 RPDU3_B2_SSPC_Order_15 1 "接通" 0 "断开" ;
VAL_ 2416185344 RPDU3_B2_SSPC_Order_14 1 "接通" 0 "断开" ;
VAL_ 2416185344 RPDU3_B2_SSPC_Order_13 1 "接通" 0 "断开" ;
VAL_ 2416185344 RPDU3_B2_SSPC_Order_12 1 "接通" 0 "断开" ;
VAL_ 2416185344 RPDU3_B2_SSPC_Order_11 1 "接通" 0 "断开" ;
VAL_ 2416185344 RPDU3_B2_SSPC_Order_10 1 "接通" 0 "断开" ;
VAL_ 2416185344 RPDU3_B2_SSPC_Order_09 1 "接通" 0 "断开" ;
VAL_ 2416185344 RPDU3_B2_SSPC_Order_08 1 "接通" 0 "断开" ;
VAL_ 2416185344 RPDU3_B2_SSPC_Order_07 1 "接通" 0 "断开" ;
VAL_ 2416185344 RPDU3_B2_SSPC_Order_06 1 "接通" 0 "断开" ;
VAL_ 2416185344 RPDU3_B2_SSPC_Order_05 1 "接通" 0 "断开" ;
VAL_ 2416185344 RPDU3_B2_SSPC_Order_04 1 "接通" 0 "断开" ;
VAL_ 2416185344 RPDU3_B2_SSPC_Order_03 1 "接通" 0 "断开" ;
VAL_ 2416185344 RPDU3_B2_SSPC_Order_02 1 "接通" 0 "断开" ;
VAL_ 2416185344 RPDU3_B2_SSPC_Order_01 1 "接通" 0 "断开" ;
VAL_ 2416119808 RPDU3_B5_SSPC_Order_07 1 "接通" 0 "断开" ;
VAL_ 2416119808 RPDU3_B5_SSPC_Order_06 1 "接通" 0 "断开" ;
VAL_ 2416119808 RPDU3_B5_SSPC_Order_05 1 "接通" 0 "断开" ;
VAL_ 2416119808 RPDU3_B5_SSPC_Order_04 1 "接通" 0 "断开" ;
VAL_ 2416119808 RPDU3_B5_SSPC_Order_03 1 "接通" 0 "断开" ;
VAL_ 2416119808 RPDU3_B5_SSPC_Order_02 1 "接通" 0 "断开" ;
VAL_ 2416119808 RPDU3_B5_SSPC_Order_01 1 "接通" 0 "断开" ;
VAL_ 2416119808 RPDU3_B3_SSPC_Order_18 1 "接通" 0 "断开" ;
VAL_ 2416119808 RPDU3_B3_SSPC_Order_17 1 "接通" 0 "断开" ;
VAL_ 2416119808 RPDU3_B3_SSPC_Order_16 1 "接通" 0 "断开" ;
VAL_ 2416119808 RPDU3_B3_SSPC_Order_15 1 "接通" 0 "断开" ;
VAL_ 2416119808 RPDU3_B3_SSPC_Order_14 1 "接通" 0 "断开" ;
VAL_ 2416119808 RPDU3_B3_SSPC_Order_13 1 "接通" 0 "断开" ;
VAL_ 2416119808 RPDU3_B3_SSPC_Order_12 1 "接通" 0 "断开" ;
VAL_ 2416119808 RPDU3_B3_SSPC_Order_11 1 "接通" 0 "断开" ;
VAL_ 2416119808 RPDU3_B3_SSPC_Order_10 1 "接通" 0 "断开" ;
VAL_ 2416119808 RPDU3_B3_SSPC_Order_09 1 "接通" 0 "断开" ;
VAL_ 2416119808 RPDU3_B3_SSPC_Order_08 1 "接通" 0 "断开" ;
VAL_ 2416119808 RPDU3_B3_SSPC_Order_07 1 "接通" 0 "断开" ;
VAL_ 2416119808 RPDU3_B3_SSPC_Order_06 1 "接通" 0 "断开" ;
VAL_ 2416119808 RPDU3_B3_SSPC_Order_05 1 "接通" 0 "断开" ;
VAL_ 2416119808 RPDU3_B3_SSPC_Order_04 1 "接通" 0 "断开" ;
VAL_ 2416119808 RPDU3_B3_SSPC_Order_03 1 "接通" 0 "断开" ;
VAL_ 2416119808 RPDU3_B3_SSPC_Order_02 1 "接通" 0 "断开" ;
VAL_ 2416119808 RPDU3_B3_SSPC_Order_01 1 "接通" 0 "断开" ;
VAL_ 2416119808 RPDU3_B1_SSPC_Order_18 1 "接通" 0 "断开" ;
VAL_ 2416119808 RPDU3_B1_SSPC_Order_17 1 "接通" 0 "断开" ;
VAL_ 2416119808 RPDU3_B1_SSPC_Order_16 1 "接通" 0 "断开" ;
VAL_ 2416119808 RPDU3_B1_SSPC_Order_15 1 "接通" 0 "断开" ;
VAL_ 2416119808 RPDU3_B1_SSPC_Order_14 1 "接通" 0 "断开" ;
VAL_ 2416119808 RPDU3_B1_SSPC_Order_13 1 "接通" 0 "断开" ;
VAL_ 2416119808 RPDU3_B1_SSPC_Order_12 1 "接通" 0 "断开" ;
VAL_ 2416119808 RPDU3_B1_SSPC_Order_11 1 "接通" 0 "断开" ;
VAL_ 2416119808 RPDU3_B1_SSPC_Order_10 1 "接通" 0 "断开" ;
VAL_ 2416119808 RPDU3_B1_SSPC_Order_09 1 "接通" 0 "断开" ;
VAL_ 2416119808 RPDU3_B1_SSPC_Order_08 1 "接通" 0 "断开" ;
VAL_ 2416119808 RPDU3_B1_SSPC_Order_07 1 "接通" 0 "断开" ;
VAL_ 2416119808 RPDU3_B1_SSPC_Order_06 1 "接通" 0 "断开" ;
VAL_ 2416119808 RPDU3_B1_SSPC_Order_05 1 "接通" 0 "断开" ;
VAL_ 2416119808 RPDU3_B1_SSPC_Order_04 1 "接通" 0 "断开" ;
VAL_ 2416119808 RPDU3_B1_SSPC_Order_03 1 "接通" 0 "断开" ;
VAL_ 2416119808 RPDU3_B1_SSPC_Order_02 1 "接通" 0 "断开" ;
VAL_ 2416119808 RPDU3_B1_SSPC_Order_01 1 "接通" 0 "断开" ;
VAL_ 2416054272 RPDU1_B6_SSPC_Order_07 1 "接通" 0 "断开" ;
VAL_ 2416054272 RPDU1_B6_SSPC_Order_06 1 "接通" 0 "断开" ;
VAL_ 2416054272 RPDU1_B6_SSPC_Order_05 1 "接通" 0 "断开" ;
VAL_ 2416054272 RPDU1_B6_SSPC_Order_04 1 "接通" 0 "断开" ;
VAL_ 2416054272 RPDU1_B6_SSPC_Order_03 1 "接通" 0 "断开" ;
VAL_ 2416054272 RPDU1_B6_SSPC_Order_02 1 "接通" 0 "断开" ;
VAL_ 2416054272 RPDU1_B6_SSPC_Order_01 1 "接通" 0 "断开" ;
VAL_ 2416054272 RPDU1_B4_SSPC_Order_18 1 "接通" 0 "断开" ;
VAL_ 2416054272 RPDU1_B4_SSPC_Order_17 1 "接通" 0 "断开" ;
VAL_ 2416054272 RPDU1_B4_SSPC_Order_16 1 "接通" 0 "断开" ;
VAL_ 2416054272 RPDU1_B4_SSPC_Order_15 1 "接通" 0 "断开" ;
VAL_ 2416054272 RPDU1_B4_SSPC_Order_14 1 "接通" 0 "断开" ;
VAL_ 2416054272 RPDU1_B4_SSPC_Order_13 1 "接通" 0 "断开" ;
VAL_ 2416054272 RPDU1_B4_SSPC_Order_12 1 "接通" 0 "断开" ;
VAL_ 2416054272 RPDU1_B4_SSPC_Order_11 1 "接通" 0 "断开" ;
VAL_ 2416054272 RPDU1_B4_SSPC_Order_10 1 "接通" 0 "断开" ;
VAL_ 2416054272 RPDU1_B4_SSPC_Order_09 1 "接通" 0 "断开" ;
VAL_ 2416054272 RPDU1_B4_SSPC_Order_08 1 "接通" 0 "断开" ;
VAL_ 2416054272 RPDU1_B4_SSPC_Order_07 1 "接通" 0 "断开" ;
VAL_ 2416054272 RPDU1_B4_SSPC_Order_06 1 "接通" 0 "断开" ;
VAL_ 2416054272 RPDU1_B4_SSPC_Order_05 1 "接通" 0 "断开" ;
VAL_ 2416054272 RPDU1_B4_SSPC_Order_04 1 "接通" 0 "断开" ;
VAL_ 2416054272 RPDU1_B4_SSPC_Order_03 1 "接通" 0 "断开" ;
VAL_ 2416054272 RPDU1_B4_SSPC_Order_02 1 "接通" 0 "断开" ;
VAL_ 2416054272 RPDU1_B4_SSPC_Order_01 1 "接通" 0 "断开" ;
VAL_ 2416054272 RPDU1_B2_SSPC_Order_18 1 "接通" 0 "断开" ;
VAL_ 2416054272 RPDU1_B2_SSPC_Order_17 1 "接通" 0 "断开" ;
VAL_ 2416054272 RPDU1_B2_SSPC_Order_16 1 "接通" 0 "断开" ;
VAL_ 2416054272 RPDU1_B2_SSPC_Order_15 1 "接通" 0 "断开" ;
VAL_ 2416054272 RPDU1_B2_SSPC_Order_14 1 "接通" 0 "断开" ;
VAL_ 2416054272 RPDU1_B2_SSPC_Order_13 1 "接通" 0 "断开" ;
VAL_ 2416054272 RPDU1_B2_SSPC_Order_12 1 "接通" 0 "断开" ;
VAL_ 2416054272 RPDU1_B2_SSPC_Order_11 1 "接通" 0 "断开" ;
VAL_ 2416054272 RPDU1_B2_SSPC_Order_10 1 "接通" 0 "断开" ;
VAL_ 2416054272 RPDU1_B2_SSPC_Order_09 1 "接通" 0 "断开" ;
VAL_ 2416054272 RPDU1_B2_SSPC_Order_08 1 "接通" 0 "断开" ;
VAL_ 2416054272 RPDU1_B2_SSPC_Order_07 1 "接通" 0 "断开" ;
VAL_ 2416054272 RPDU1_B2_SSPC_Order_06 1 "接通" 0 "断开" ;
VAL_ 2416054272 RPDU1_B2_SSPC_Order_05 1 "接通" 0 "断开" ;
VAL_ 2416054272 RPDU1_B2_SSPC_Order_04 1 "接通" 0 "断开" ;
VAL_ 2416054272 RPDU1_B2_SSPC_Order_03 1 "接通" 0 "断开" ;
VAL_ 2416054272 RPDU1_B2_SSPC_Order_02 1 "接通" 0 "断开" ;
VAL_ 2416054272 RPDU1_B2_SSPC_Order_01 1 "接通" 0 "断开" ;
VAL_ 2415988736 RPDU1_B5_SSPC_Order_07 1 "接通" 0 "断开" ;
VAL_ 2415988736 RPDU1_B5_SSPC_Order_06 1 "接通" 0 "断开" ;
VAL_ 2415988736 RPDU1_B5_SSPC_Order_05 1 "接通" 0 "断开" ;
VAL_ 2415988736 RPDU1_B5_SSPC_Order_04 1 "接通" 0 "断开" ;
VAL_ 2415988736 RPDU1_B5_SSPC_Order_03 1 "接通" 0 "断开" ;
VAL_ 2415988736 RPDU1_B5_SSPC_Order_02 1 "接通" 0 "断开" ;
VAL_ 2415988736 RPDU1_B5_SSPC_Order_01 1 "接通" 0 "断开" ;
VAL_ 2415988736 RPDU1_B3_SSPC_Order_18 1 "接通" 0 "断开" ;
VAL_ 2415988736 RPDU1_B3_SSPC_Order_17 1 "接通" 0 "断开" ;
VAL_ 2415988736 RPDU1_B3_SSPC_Order_16 1 "接通" 0 "断开" ;
VAL_ 2415988736 RPDU1_B3_SSPC_Order_15 1 "接通" 0 "断开" ;
VAL_ 2415988736 RPDU1_B3_SSPC_Order_14 1 "接通" 0 "断开" ;
VAL_ 2415988736 RPDU1_B3_SSPC_Order_13 1 "接通" 0 "断开" ;
VAL_ 2415988736 RPDU1_B3_SSPC_Order_12 1 "接通" 0 "断开" ;
VAL_ 2415988736 RPDU1_B3_SSPC_Order_11 1 "接通" 0 "断开" ;
VAL_ 2415988736 RPDU1_B3_SSPC_Order_10 1 "接通" 0 "断开" ;
VAL_ 2415988736 RPDU1_B3_SSPC_Order_09 1 "接通" 0 "断开" ;
VAL_ 2415988736 RPDU1_B3_SSPC_Order_08 1 "接通" 0 "断开" ;
VAL_ 2415988736 RPDU1_B3_SSPC_Order_07 1 "接通" 0 "断开" ;
VAL_ 2415988736 RPDU1_B3_SSPC_Order_06 1 "接通" 0 "断开" ;
VAL_ 2415988736 RPDU1_B3_SSPC_Order_05 1 "接通" 0 "断开" ;
VAL_ 2415988736 RPDU1_B3_SSPC_Order_04 1 "接通" 0 "断开" ;
VAL_ 2415988736 RPDU1_B3_SSPC_Order_03 1 "接通" 0 "断开" ;
VAL_ 2415988736 RPDU1_B3_SSPC_Order_02 1 "接通" 0 "断开" ;
VAL_ 2415988736 RPDU1_B3_SSPC_Order_01 1 "接通" 0 "断开" ;
VAL_ 2415988736 RPDU1_B1_SSPC_Order_18 1 "接通" 0 "断开" ;
VAL_ 2415988736 RPDU1_B1_SSPC_Order_17 1 "接通" 0 "断开" ;
VAL_ 2415988736 RPDU1_B1_SSPC_Order_16 1 "接通" 0 "断开" ;
VAL_ 2415988736 RPDU1_B1_SSPC_Order_15 1 "接通" 0 "断开" ;
VAL_ 2415988736 RPDU1_B1_SSPC_Order_14 1 "接通" 0 "断开" ;
VAL_ 2415988736 RPDU1_B1_SSPC_Order_13 1 "接通" 0 "断开" ;
VAL_ 2415988736 RPDU1_B1_SSPC_Order_12 1 "接通" 0 "断开" ;
VAL_ 2415988736 RPDU1_B1_SSPC_Order_11 1 "接通" 0 "断开" ;
VAL_ 2415988736 RPDU1_B1_SSPC_Order_10 1 "接通" 0 "断开" ;
VAL_ 2415988736 RPDU1_B1_SSPC_Order_09 1 "接通" 0 "断开" ;
VAL_ 2415988736 RPDU1_B1_SSPC_Order_08 1 "接通" 0 "断开" ;
VAL_ 2415988736 RPDU1_B1_SSPC_Order_07 1 "接通" 0 "断开" ;
VAL_ 2415988736 RPDU1_B1_SSPC_Order_06 1 "接通" 0 "断开" ;
VAL_ 2415988736 RPDU1_B1_SSPC_Order_05 1 "接通" 0 "断开" ;
VAL_ 2415988736 RPDU1_B1_SSPC_Order_04 1 "接通" 0 "断开" ;
VAL_ 2415988736 RPDU1_B1_SSPC_Order_03 1 "接通" 0 "断开" ;
VAL_ 2415988736 RPDU1_B1_SSPC_Order_02 1 "接通" 0 "断开" ;
VAL_ 2415988736 RPDU1_B1_SSPC_Order_01 1 "接通" 0 "断开" ;
VAL_ 2421178416 EPC_Ctrl 0 "接通" 1 "断开" ;
VAL_ 2421178416 CPC_A_STA_ChongGou 0 "接通" 1 "断开" ;
VAL_ 2421178416 EDC1_Ctrl 0 "接通" 1 "断开" ;
VAL_ 2421178416 E_HLT28IOver_ChongGou 0 "不过流" 1 "过流" ;
VAL_ 2421178416 E_HLT270IOver_ChongGou 0 "不过流" 1 "过流" ;
VAL_ 2416181296 E_DuanLuQi_Sta_48 0 "接通" 1 "断开" ;
VAL_ 2416181296 E_DuanLuQi_Sta_47 0 "接通" 1 "断开" ;
VAL_ 2416181296 E_DuanLuQi_Sta_46 0 "接通" 1 "断开" ;
VAL_ 2416181296 E_DuanLuQi_Sta_45 0 "接通" 1 "断开" ;
VAL_ 2416181296 E_DuanLuQi_Sta_44 0 "接通" 1 "断开" ;
VAL_ 2416181296 E_DuanLuQi_Sta_43 0 "接通" 1 "断开" ;
VAL_ 2416181296 E_DuanLuQi_Sta_42 0 "接通" 1 "断开" ;
VAL_ 2416181296 E_DuanLuQi_Sta_41 0 "接通" 1 "断开" ;
VAL_ 2416181296 E_DuanLuQi_Sta_40 0 "接通" 1 "断开" ;
VAL_ 2416181296 E_DuanLuQi_Sta_39 0 "接通" 1 "断开" ;
VAL_ 2416181296 E_DuanLuQi_Sta_38 0 "接通" 1 "断开" ;
VAL_ 2416181296 E_DuanLuQi_Sta_37 0 "接通" 1 "断开" ;
VAL_ 2416181296 E_DuanLuQi_Sta_36 0 "接通" 1 "断开" ;
VAL_ 2416181296 E_DuanLuQi_Sta_35 0 "接通" 1 "断开" ;
VAL_ 2416181296 E_DuanLuQi_Sta_34 0 "接通" 1 "断开" ;
VAL_ 2416181296 E_DuanLuQi_Sta_33 0 "接通" 1 "断开" ;
VAL_ 2416181296 E_DuanLuQi_Sta_32 0 "接通" 1 "断开" ;
VAL_ 2416181296 E_DuanLuQi_Sta_31 0 "接通" 1 "断开" ;
VAL_ 2416181296 E_DuanLuQi_Sta_30 0 "接通" 1 "断开" ;
VAL_ 2416181296 E_DuanLuQi_Sta_29 0 "接通" 1 "断开" ;
VAL_ 2416181296 E_DuanLuQi_Sta_28 0 "接通" 1 "断开" ;
VAL_ 2416181296 E_DuanLuQi_Sta_27 0 "接通" 1 "断开" ;
VAL_ 2416181296 E_DuanLuQi_Sta_26 0 "接通" 1 "断开" ;
VAL_ 2416181296 E_DuanLuQi_Sta_25 0 "接通" 1 "断开" ;
VAL_ 2416181296 E_DuanLuQi_Sta_24 0 "接通" 1 "断开" ;
VAL_ 2416181296 E_DuanLuQi_Sta_23 0 "接通" 1 "断开" ;
VAL_ 2416181296 E_DuanLuQi_Sta_22 0 "接通" 1 "断开" ;
VAL_ 2416181296 E_DuanLuQi_Sta_21 0 "接通" 1 "断开" ;
VAL_ 2416181296 E_DuanLuQi_Sta_20 0 "接通" 1 "断开" ;
VAL_ 2416181296 E_DuanLuQi_Sta_19 0 "接通" 1 "断开" ;
VAL_ 2416181296 E_DuanLuQi_Sta_18 0 "接通" 1 "断开" ;
VAL_ 2416181296 E_DuanLuQi_Sta_17 0 "接通" 1 "断开" ;
VAL_ 2416181296 E_DuanLuQi_Sta_16 0 "接通" 1 "断开" ;
VAL_ 2416181296 E_DuanLuQi_Sta_15 0 "接通" 1 "断开" ;
VAL_ 2416181296 E_DuanLuQi_Sta_14 0 "接通" 1 "断开" ;
VAL_ 2416181296 E_DuanLuQi_Sta_13 0 "接通" 1 "断开" ;
VAL_ 2416181296 E_DuanLuQi_Sta_12 0 "接通" 1 "断开" ;
VAL_ 2416181296 E_DuanLuQi_Sta_11 0 "接通" 1 "断开" ;
VAL_ 2416181296 E_DuanLuQi_Sta_10 0 "接通" 1 "断开" ;
VAL_ 2416181296 E_DuanLuQi_Sta_09 0 "接通" 1 "断开" ;
VAL_ 2416181296 E_DuanLuQi_Sta_08 0 "接通" 1 "断开" ;
VAL_ 2416181296 E_DuanLuQi_Sta_07 0 "接通" 1 "断开" ;
VAL_ 2416181296 E_DuanLuQi_Sta_06 0 "接通" 1 "断开" ;
VAL_ 2416181296 E_DuanLuQi_Sta_05 0 "接通" 1 "断开" ;
VAL_ 2416181296 E_DuanLuQi_Sta_04 0 "接通" 1 "断开" ;
VAL_ 2416181296 E_DuanLuQi_Sta_03 0 "接通" 1 "断开" ;
VAL_ 2416181296 E_DuanLuQi_Sta_02 0 "接通" 1 "断开" ;
VAL_ 2416181296 E_DuanLuQi_Sta_01 0 "接通" 1 "断开" ;
VAL_ 2416640048 E_TouChuan_DCDC_DDCSta 0 "断开" 1 "接通" ;
VAL_ 2416640048 E_TouChuan_DCDC_DDCCtrl 0 "断开" 1 "接通" ;
VAL_ 2416640048 E_TouChuan_DCDC_FanWarn 0 "正常" 1 "故障" ;
VAL_ 2416640048 E_TouChuan_DCDC_ConnStaErr 0 "正常" 1 "故障" ;
VAL_ 2416640048 E_TouChuan_DCDC_HardOutOverErr 0 "正常" 1 "故障" ;
VAL_ 2416640048 E_TouChuan_DCDC_TOverErr 0 "正常" 1 "故障" ;
VAL_ 2416640048 E_TouChuan_DCDC_TOverWarn 0 "正常" 1 "故障" ;
VAL_ 2416640048 E_TouChuan_DCDC_OutILimitErr 0 "正常" 1 "故障" ;
VAL_ 2416640048 E_TouChuan_DCDC_OutIOverErr 0 "正常" 1 "故障" ;
VAL_ 2416640048 E_TouChuan_DCDC_OutPowOverErr 0 "正常" 1 "故障" ;
VAL_ 2416640048 E_TouChuan_DCDC_OutPowLowErr 0 "正常" 1 "故障" ;
VAL_ 2416640048 E_TouChuan_DCDC_OutPowLowWarn 0 "正常" 1 "故障" ;
VAL_ 2416640048 E_TouChuan_DCDC_InPowLowErr 0 "正常" 1 "故障" ;
VAL_ 2416246832 E_HLT28IOver 0 "不过流" 1 "过流" ;
VAL_ 2416246832 E_WaiBu270IOver 0 "不过流" 1 "过流" ;
VAL_ 2416246832 E_HLT270IOver 0 "不过流" 1 "过流" ;
VAL_ 2416246832 E_HLT28USta 0 "正常" 1 "欠压" 2 "过压" 3 "无定义" ;
VAL_ 2416246832 E_DCDC28OutUSta 0 "正常" 1 "欠压" 2 "过压" 3 "无定义" ;
VAL_ 2416246832 E_DCDC270InUSta 0 "正常" 1 "欠压" 2 "过压" 3 "无定义" ;
VAL_ 2416246832 E_HLT270USta 0 "正常" 1 "欠压" 2 "过压" 3 "无定义" ;
VAL_ 2416246832 E_ChongDianUSta 0 "正常" 1 "欠压" 2 "过压" 3 "无定义" ;
VAL_ 2416246832 E_WaiBu270USta 0 "正常" 1 "欠压" 2 "过压" 3 "无定义" ;
VAL_ 2416246832 E_Batter270USta 0 "正常" 1 "欠压" 2 "过压" 3 "无定义" ;
VAL_ 2416246832 E_ADCIN_BIT 0 "正常" 1 "故障" ;
VAL_ 2416246832 E_GpioIN_BIT 0 "正常" 1 "故障" ;
VAL_ 2416246832 E_Flash_BIT 0 "正常" 1 "故障" ;
VAL_ 2416246832 E_UART_BIT 0 "正常" 1 "故障" ;
VAL_ 2416246832 E_ExtCAN2_BIT 0 "正常" 1 "故障" ;
VAL_ 2416246832 E_ExtCAN1_BIT 0 "正常" 1 "故障" ;
VAL_ 2416246832 E_CPU_BIT 0 "正常" 1 "故障" ;
VAL_ 2416246832 E_Pow_BIT 0 "正常" 1 "故障" ;
VAL_ 2416115760 CPC_B_STA 0 "接通正常" 1 "接通故障" 3 "断开正常" 2 "断开故障" ;
VAL_ 2416115760 CPC_A_STA 0 "接通正常" 1 "接通故障" 3 "断开正常" 2 "断开故障" ;
VAL_ 2416115760 EPC_STA 0 "接通正常" 1 "接通故障" 3 "断开正常" 2 "断开故障" ;
VAL_ 2421178400 RETC1_ChongGou_ChangJing 0 "无控制或断开" 1 "右欠压,E正常" 2 "右正常,E欠压" 3 "右欠压,E欠压" ;
VAL_ 2421178400 RETC1_STA_ChongGou 0 "接通正常" 1 "接通故障" 3 "断开正常" 2 "断开故障" ;
VAL_ 2421178400 RDC2_Ctrl 0 "接通" 1 "断开" ;
VAL_ 2421178400 RDC1_Ctrl 0 "接通" 1 "断开" ;
VAL_ 2421178400 BTC1_ChongGou_ChangJing 0 "无控制" 1 "左欠压,右正常" 2 "左正常,右欠压" 3 "无定义" ;
VAL_ 2421178400 RETC1_ReSta 0 "接通" 1 "断开" ;
VAL_ 2421178400 R_HLT282IOver_ChongGou 0 "不过流" 1 "过流" ;
VAL_ 2421178400 R_HLT281IOver_ChongGou 0 "不过流" 1 "过流" ;
VAL_ 2421178400 R_HLT270IOver_ChongGou 0 "不过流" 1 "过流" ;
VAL_ 2420178976 RPDU4_B6_SSPC_TripSta_07 1 "短路跳闸" 2 "过流跳闸" 0 "正常" 3 "无定义" ;
VAL_ 2420178976 RPDU4_B6_SSPC_BitErr_07 1 "故障" 0 "正常" ;
VAL_ 2420178976 RPDU4_B6_SSPC_OnOffSta_07 1 "接通" 0 "断开" ;
VAL_ 2420178976 RPDU4_B6_SSPC_DianHuErr_07 1 "有故障" 0 "无故障" ;
VAL_ 2420178976 RPDU4_B6_SSPC_TripSta_06 1 "短路跳闸" 2 "过流跳闸" 0 "正常" 3 "无定义" ;
VAL_ 2420178976 RPDU4_B6_SSPC_BitErr_06 1 "故障" 0 "正常" ;
VAL_ 2420178976 RPDU4_B6_SSPC_OnOffSta_06 1 "接通" 0 "断开" ;
VAL_ 2420178976 RPDU4_B6_SSPC_DianHuErr_06 1 "有故障" 0 "无故障" ;
VAL_ 2420178976 RPDU4_B6_SSPC_TripSta_05 1 "短路跳闸" 2 "过流跳闸" 0 "正常" 3 "无定义" ;
VAL_ 2420178976 RPDU4_B6_SSPC_BitErr_05 1 "故障" 0 "正常" ;
VAL_ 2420178976 RPDU4_B6_SSPC_OnOffSta_05 1 "接通" 0 "断开" ;
VAL_ 2420178976 RPDU4_B6_SSPC_DianHuErr_05 1 "有故障" 0 "无故障" ;
VAL_ 2420113440 RPDU4_B6_SSPC_TripSta_04 1 "短路跳闸" 2 "过流跳闸" 0 "正常" 3 "无定义" ;
VAL_ 2420113440 RPDU4_B6_SSPC_BitErr_04 1 "故障" 0 "正常" ;
VAL_ 2420113440 RPDU4_B6_SSPC_OnOffSta_04 1 "接通" 0 "断开" ;
VAL_ 2420113440 RPDU4_B6_SSPC_DianHuErr_04 1 "有故障" 0 "无故障" ;
VAL_ 2420113440 RPDU4_B6_SSPC_TripSta_03 1 "短路跳闸" 2 "过流跳闸" 0 "正常" 3 "无定义" ;
VAL_ 2420113440 RPDU4_B6_SSPC_BitErr_03 1 "故障" 0 "正常" ;
VAL_ 2420113440 RPDU4_B6_SSPC_OnOffSta_03 1 "接通" 0 "断开" ;
VAL_ 2420113440 RPDU4_B6_SSPC_DianHuErr_03 1 "有故障" 0 "无故障" ;
VAL_ 2420113440 RPDU4_B6_SSPC_TripSta_02 1 "短路跳闸" 2 "过流跳闸" 0 "正常" 3 "无定义" ;
VAL_ 2420113440 RPDU4_B6_SSPC_BitErr_02 1 "故障" 0 "正常" ;
VAL_ 2420113440 RPDU4_B6_SSPC_OnOffSta_02 1 "接通" 0 "断开" ;
VAL_ 2420113440 RPDU4_B6_SSPC_DianHuErr_02 1 "有故障" 0 "无故障" ;
VAL_ 2420113440 RPDU4_B6_SSPC_TripSta_01 1 "短路跳闸" 2 "过流跳闸" 0 "正常" 3 "无定义" ;
VAL_ 2420113440 RPDU4_B6_SSPC_BitErr_01 1 "故障" 0 "正常" ;
VAL_ 2420113440 RPDU4_B6_SSPC_OnOffSta_01 1 "接通" 0 "断开" ;
VAL_ 2420113440 RPDU4_B6_SSPC_DianHuErr_01 1 "有故障" 0 "无故障" ;
VAL_ 2420047904 RPDU4_B5_SSPC_TripSta_07 1 "短路跳闸" 2 "过流跳闸" 0 "正常" 3 "无定义" ;
VAL_ 2420047904 RPDU4_B5_SSPC_BitErr_07 1 "故障" 0 "正常" ;
VAL_ 2420047904 RPDU4_B5_SSPC_OnOffSta_07 1 "接通" 0 "断开" ;
VAL_ 2420047904 RPDU4_B5_SSPC_DianHuErr_07 1 "有故障" 0 "无故障" ;
VAL_ 2420047904 RPDU4_B5_SSPC_TripSta_06 1 "短路跳闸" 2 "过流跳闸" 0 "正常" 3 "无定义" ;
VAL_ 2420047904 RPDU4_B5_SSPC_BitErr_06 1 "故障" 0 "正常" ;
VAL_ 2420047904 RPDU4_B5_SSPC_OnOffSta_06 1 "接通" 0 "断开" ;
VAL_ 2420047904 RPDU4_B5_SSPC_DianHuErr_06 1 "有故障" 0 "无故障" ;
VAL_ 2420047904 RPDU4_B5_SSPC_TripSta_05 1 "短路跳闸" 2 "过流跳闸" 0 "正常" 3 "无定义" ;
VAL_ 2420047904 RPDU4_B5_SSPC_BitErr_05 1 "故障" 0 "正常" ;
VAL_ 2420047904 RPDU4_B5_SSPC_OnOffSta_05 1 "接通" 0 "断开" ;
VAL_ 2420047904 RPDU4_B5_SSPC_DianHuErr_05 1 "有故障" 0 "无故障" ;
VAL_ 2419982368 RPDU4_B5_SSPC_TripSta_04 1 "短路跳闸" 2 "过流跳闸" 0 "正常" 3 "无定义" ;
VAL_ 2419982368 RPDU4_B5_SSPC_BitErr_04 1 "故障" 0 "正常" ;
VAL_ 2419982368 RPDU4_B5_SSPC_OnOffSta_04 1 "接通" 0 "断开" ;
VAL_ 2419982368 RPDU4_B5_SSPC_DianHuErr_04 1 "有故障" 0 "无故障" ;
VAL_ 2419982368 RPDU4_B5_SSPC_TripSta_03 1 "短路跳闸" 2 "过流跳闸" 0 "正常" 3 "无定义" ;
VAL_ 2419982368 RPDU4_B5_SSPC_BitErr_03 1 "故障" 0 "正常" ;
VAL_ 2419982368 RPDU4_B5_SSPC_OnOffSta_03 1 "接通" 0 "断开" ;
VAL_ 2419982368 RPDU4_B5_SSPC_DianHuErr_03 1 "有故障" 0 "无故障" ;
VAL_ 2419982368 RPDU4_B5_SSPC_TripSta_02 1 "短路跳闸" 2 "过流跳闸" 0 "正常" 3 "无定义" ;
VAL_ 2419982368 RPDU4_B5_SSPC_BitErr_02 1 "故障" 0 "正常" ;
VAL_ 2419982368 RPDU4_B5_SSPC_OnOffSta_02 1 "接通" 0 "断开" ;
VAL_ 2419982368 RPDU4_B5_SSPC_DianHuErr_02 1 "有故障" 0 "无故障" ;
VAL_ 2419982368 RPDU4_B5_SSPC_TripSta_01 1 "短路跳闸" 2 "过流跳闸" 0 "正常" 3 "无定义" ;
VAL_ 2419982368 RPDU4_B5_SSPC_BitErr_01 1 "故障" 0 "正常" ;
VAL_ 2419982368 RPDU4_B5_SSPC_OnOffSta_01 1 "接通" 0 "断开" ;
VAL_ 2419982368 RPDU4_B5_SSPC_DianHuErr_01 1 "有故障" 0 "无故障" ;
VAL_ 2419916832 RPDU4_B4_SSPC_TripSta_18 1 "短路跳闸" 2 "过流跳闸" 0 "正常" 3 "无定义" ;
VAL_ 2419916832 RPDU4_B4_SSPC_BitErr_18 1 "故障" 0 "正常" ;
VAL_ 2419916832 RPDU4_B4_SSPC_OnOffSta_18 1 "接通" 0 "断开" ;
VAL_ 2419916832 RPDU4_B4_SSPC_DianHuErr_18 1 "有故障" 0 "无故障" ;
VAL_ 2419916832 RPDU4_B4_SSPC_TripSta_17 1 "短路跳闸" 2 "过流跳闸" 0 "正常" 3 "无定义" ;
VAL_ 2419916832 RPDU4_B4_SSPC_BitErr_17 1 "故障" 0 "正常" ;
VAL_ 2419916832 RPDU4_B4_SSPC_OnOffSta_17 1 "接通" 0 "断开" ;
VAL_ 2419916832 RPDU4_B4_SSPC_DianHuErr_17 1 "有故障" 0 "无故障" ;
VAL_ 2419851296 RPDU4_B4_SSPC_TripSta_16 1 "短路跳闸" 2 "过流跳闸" 0 "正常" 3 "无定义" ;
VAL_ 2419851296 RPDU4_B4_SSPC_BitErr_16 1 "故障" 0 "正常" ;
VAL_ 2419851296 RPDU4_B4_SSPC_OnOffSta_16 1 "接通" 0 "断开" ;
VAL_ 2419851296 RPDU4_B4_SSPC_DianHuErr_16 1 "有故障" 0 "无故障" ;
VAL_ 2419851296 RPDU4_B4_SSPC_TripSta_15 1 "短路跳闸" 2 "过流跳闸" 0 "正常" 3 "无定义" ;
VAL_ 2419851296 RPDU4_B4_SSPC_BitErr_15 1 "故障" 0 "正常" ;
VAL_ 2419851296 RPDU4_B4_SSPC_OnOffSta_15 1 "接通" 0 "断开" ;
VAL_ 2419851296 RPDU4_B4_SSPC_DianHuErr_15 1 "有故障" 0 "无故障" ;
VAL_ 2419851296 RPDU4_B4_SSPC_TripSta_14 1 "短路跳闸" 2 "过流跳闸" 0 "正常" 3 "无定义" ;
VAL_ 2419851296 RPDU4_B4_SSPC_BitErr_14 1 "故障" 0 "正常" ;
VAL_ 2419851296 RPDU4_B4_SSPC_OnOffSta_14 1 "接通" 0 "断开" ;
VAL_ 2419851296 RPDU4_B4_SSPC_DianHuErr_14 1 "有故障" 0 "无故障" ;
VAL_ 2419851296 RPDU4_B4_SSPC_TripSta_13 1 "短路跳闸" 2 "过流跳闸" 0 "正常" 3 "无定义" ;
VAL_ 2419851296 RPDU4_B4_SSPC_BitErr_13 1 "故障" 0 "正常" ;
VAL_ 2419851296 RPDU4_B4_SSPC_OnOffSta_13 1 "接通" 0 "断开" ;
VAL_ 2419851296 RPDU4_B4_SSPC_DianHuErr_13 1 "有故障" 0 "无故障" ;
VAL_ 2419785760 RPDU4_B4_SSPC_TripSta_12 1 "短路跳闸" 2 "过流跳闸" 0 "正常" 3 "无定义" ;
VAL_ 2419785760 RPDU4_B4_SSPC_BitErr_12 1 "故障" 0 "正常" ;
VAL_ 2419785760 RPDU4_B4_SSPC_OnOffSta_12 1 "接通" 0 "断开" ;
VAL_ 2419785760 RPDU4_B4_SSPC_DianHuErr_12 1 "有故障" 0 "无故障" ;
VAL_ 2419785760 RPDU4_B4_SSPC_TripSta_11 1 "短路跳闸" 2 "过流跳闸" 0 "正常" 3 "无定义" ;
VAL_ 2419785760 RPDU4_B4_SSPC_BitErr_11 1 "故障" 0 "正常" ;
VAL_ 2419785760 RPDU4_B4_SSPC_OnOffSta_11 1 "接通" 0 "断开" ;
VAL_ 2419785760 RPDU4_B4_SSPC_DianHuErr_11 1 "有故障" 0 "无故障" ;
VAL_ 2419785760 RPDU4_B4_SSPC_TripSta_10 1 "短路跳闸" 2 "过流跳闸" 0 "正常" 3 "无定义" ;
VAL_ 2419785760 RPDU4_B4_SSPC_BitErr_10 1 "故障" 0 "正常" ;
VAL_ 2419785760 RPDU4_B4_SSPC_OnOffSta_10 1 "接通" 0 "断开" ;
VAL_ 2419785760 RPDU4_B4_SSPC_DianHuErr_10 1 "有故障" 0 "无故障" ;
VAL_ 2419785760 RPDU4_B4_SSPC_TripSta_09 1 "短路跳闸" 2 "过流跳闸" 0 "正常" 3 "无定义" ;
VAL_ 2419785760 RPDU4_B4_SSPC_BitErr_09 1 "故障" 0 "正常" ;
VAL_ 2419785760 RPDU4_B4_SSPC_OnOffSta_09 1 "接通" 0 "断开" ;
VAL_ 2419785760 RPDU4_B4_SSPC_DianHuErr_09 1 "有故障" 0 "无故障" ;
VAL_ 2419720224 RPDU4_B4_SSPC_TripSta_08 1 "短路跳闸" 2 "过流跳闸" 0 "正常" 3 "无定义" ;
VAL_ 2419720224 RPDU4_B4_SSPC_BitErr_08 1 "故障" 0 "正常" ;
VAL_ 2419720224 RPDU4_B4_SSPC_OnOffSta_08 1 "接通" 0 "断开" ;
VAL_ 2419720224 RPDU4_B4_SSPC_DianHuErr_08 1 "有故障" 0 "无故障" ;
VAL_ 2419720224 RPDU4_B4_SSPC_TripSta_07 1 "短路跳闸" 2 "过流跳闸" 0 "正常" 3 "无定义" ;
VAL_ 2419720224 RPDU4_B4_SSPC_BitErr_07 1 "故障" 0 "正常" ;
VAL_ 2419720224 RPDU4_B4_SSPC_OnOffSta_07 1 "接通" 0 "断开" ;
VAL_ 2419720224 RPDU4_B4_SSPC_DianHuErr_07 1 "有故障" 0 "无故障" ;
VAL_ 2419720224 RPDU4_B4_SSPC_TripSta_06 1 "短路跳闸" 2 "过流跳闸" 0 "正常" 3 "无定义" ;
VAL_ 2419720224 RPDU4_B4_SSPC_BitErr_06 1 "故障" 0 "正常" ;
VAL_ 2419720224 RPDU4_B4_SSPC_OnOffSta_06 1 "接通" 0 "断开" ;
VAL_ 2419720224 RPDU4_B4_SSPC_DianHuErr_06 1 "有故障" 0 "无故障" ;
VAL_ 2419720224 RPDU4_B4_SSPC_TripSta_05 1 "短路跳闸" 2 "过流跳闸" 0 "正常" 3 "无定义" ;
VAL_ 2419720224 RPDU4_B4_SSPC_BitErr_05 1 "故障" 0 "正常" ;
VAL_ 2419720224 RPDU4_B4_SSPC_OnOffSta_05 1 "接通" 0 "断开" ;
VAL_ 2419720224 RPDU4_B4_SSPC_DianHuErr_05 1 "有故障" 0 "无故障" ;
VAL_ 2419654688 RPDU4_B4_SSPC_TripSta_04 1 "短路跳闸" 2 "过流跳闸" 0 "正常" 3 "无定义" ;
VAL_ 2419654688 RPDU4_B4_SSPC_BitErr_04 1 "故障" 0 "正常" ;
VAL_ 2419654688 RPDU4_B4_SSPC_OnOffSta_04 1 "接通" 0 "断开" ;
VAL_ 2419654688 RPDU4_B4_SSPC_DianHuErr_04 1 "有故障" 0 "无故障" ;
VAL_ 2419654688 RPDU4_B4_SSPC_TripSta_03 1 "短路跳闸" 2 "过流跳闸" 0 "正常" 3 "无定义" ;
VAL_ 2419654688 RPDU4_B4_SSPC_BitErr_03 1 "故障" 0 "正常" ;
VAL_ 2419654688 RPDU4_B4_SSPC_OnOffSta_03 1 "接通" 0 "断开" ;
VAL_ 2419654688 RPDU4_B4_SSPC_DianHuErr_03 1 "有故障" 0 "无故障" ;
VAL_ 2419654688 RPDU4_B4_SSPC_TripSta_02 1 "短路跳闸" 2 "过流跳闸" 0 "正常" 3 "无定义" ;
VAL_ 2419654688 RPDU4_B4_SSPC_BitErr_02 1 "故障" 0 "正常" ;
VAL_ 2419654688 RPDU4_B4_SSPC_OnOffSta_02 1 "接通" 0 "断开" ;
VAL_ 2419654688 RPDU4_B4_SSPC_DianHuErr_02 1 "有故障" 0 "无故障" ;
VAL_ 2419654688 RPDU4_B4_SSPC_TripSta_01 1 "短路跳闸" 2 "过流跳闸" 0 "正常" 3 "无定义" ;
VAL_ 2419654688 RPDU4_B4_SSPC_BitErr_01 1 "故障" 0 "正常" ;
VAL_ 2419654688 RPDU4_B4_SSPC_OnOffSta_01 1 "接通" 0 "断开" ;
VAL_ 2419654688 RPDU4_B4_SSPC_DianHuErr_01 1 "有故障" 0 "无故障" ;
VAL_ 2419589152 RPDU4_B3_SSPC_TripSta_18 1 "短路跳闸" 2 "过流跳闸" 0 "正常" 3 "无定义" ;
VAL_ 2419589152 RPDU4_B3_SSPC_BitErr_18 1 "故障" 0 "正常" ;
VAL_ 2419589152 RPDU4_B3_SSPC_OnOffSta_18 1 "接通" 0 "断开" ;
VAL_ 2419589152 RPDU4_B3_SSPC_DianHuErr_18 1 "有故障" 0 "无故障" ;
VAL_ 2419589152 RPDU4_B3_SSPC_TripSta_17 1 "短路跳闸" 2 "过流跳闸" 0 "正常" 3 "无定义" ;
VAL_ 2419589152 RPDU4_B3_SSPC_BitErr_17 1 "故障" 0 "正常" ;
VAL_ 2419589152 RPDU4_B3_SSPC_OnOffSta_17 1 "接通" 0 "断开" ;
VAL_ 2419589152 RPDU4_B3_SSPC_DianHuErr_17 1 "有故障" 0 "无故障" ;
VAL_ 2419523616 RPDU4_B3_SSPC_TripSta_16 1 "短路跳闸" 2 "过流跳闸" 0 "正常" 3 "无定义" ;
VAL_ 2419523616 RPDU4_B3_SSPC_BitErr_16 1 "故障" 0 "正常" ;
VAL_ 2419523616 RPDU4_B3_SSPC_OnOffSta_16 1 "接通" 0 "断开" ;
VAL_ 2419523616 RPDU4_B3_SSPC_DianHuErr_16 1 "有故障" 0 "无故障" ;
VAL_ 2419523616 RPDU4_B3_SSPC_TripSta_15 1 "短路跳闸" 2 "过流跳闸" 0 "正常" 3 "无定义" ;
VAL_ 2419523616 RPDU4_B3_SSPC_BitErr_15 1 "故障" 0 "正常" ;
VAL_ 2419523616 RPDU4_B3_SSPC_OnOffSta_15 1 "接通" 0 "断开" ;
VAL_ 2419523616 RPDU4_B3_SSPC_DianHuErr_15 1 "有故障" 0 "无故障" ;
VAL_ 2419523616 RPDU4_B3_SSPC_TripSta_14 1 "短路跳闸" 2 "过流跳闸" 0 "正常" 3 "无定义" ;
VAL_ 2419523616 RPDU4_B3_SSPC_BitErr_14 1 "故障" 0 "正常" ;
VAL_ 2419523616 RPDU4_B3_SSPC_OnOffSta_14 1 "接通" 0 "断开" ;
VAL_ 2419523616 RPDU4_B3_SSPC_DianHuErr_14 1 "有故障" 0 "无故障" ;
VAL_ 2419523616 RPDU4_B3_SSPC_TripSta_13 1 "短路跳闸" 2 "过流跳闸" 0 "正常" 3 "无定义" ;
VAL_ 2419523616 RPDU4_B3_SSPC_BitErr_13 1 "故障" 0 "正常" ;
VAL_ 2419523616 RPDU4_B3_SSPC_OnOffSta_13 1 "接通" 0 "断开" ;
VAL_ 2419523616 RPDU4_B3_SSPC_DianHuErr_13 1 "有故障" 0 "无故障" ;
VAL_ 2419458080 RPDU4_B3_SSPC_TripSta_12 1 "短路跳闸" 2 "过流跳闸" 0 "正常" 3 "无定义" ;
VAL_ 2419458080 RPDU4_B3_SSPC_BitErr_12 1 "故障" 0 "正常" ;
VAL_ 2419458080 RPDU4_B3_SSPC_OnOffSta_12 1 "接通" 0 "断开" ;
VAL_ 2419458080 RPDU4_B3_SSPC_DianHuErr_12 1 "有故障" 0 "无故障" ;
VAL_ 2419458080 RPDU4_B3_SSPC_TripSta_11 1 "短路跳闸" 2 "过流跳闸" 0 "正常" 3 "无定义" ;
VAL_ 2419458080 RPDU4_B3_SSPC_BitErr_11 1 "故障" 0 "正常" ;
VAL_ 2419458080 RPDU4_B3_SSPC_OnOffSta_11 1 "接通" 0 "断开" ;
VAL_ 2419458080 RPDU4_B3_SSPC_DianHuErr_11 1 "有故障" 0 "无故障" ;
VAL_ 2419458080 RPDU4_B3_SSPC_TripSta_10 1 "短路跳闸" 2 "过流跳闸" 0 "正常" 3 "无定义" ;
VAL_ 2419458080 RPDU4_B3_SSPC_BitErr_10 1 "故障" 0 "正常" ;
VAL_ 2419458080 RPDU4_B3_SSPC_OnOffSta_10 1 "接通" 0 "断开" ;
VAL_ 2419458080 RPDU4_B3_SSPC_DianHuErr_10 1 "有故障" 0 "无故障" ;
VAL_ 2419458080 RPDU4_B3_SSPC_TripSta_09 1 "短路跳闸" 2 "过流跳闸" 0 "正常" 3 "无定义" ;
VAL_ 2419458080 RPDU4_B3_SSPC_BitErr_09 1 "故障" 0 "正常" ;
VAL_ 2419458080 RPDU4_B3_SSPC_OnOffSta_09 1 "接通" 0 "断开" ;
VAL_ 2419458080 RPDU4_B3_SSPC_DianHuErr_09 1 "有故障" 0 "无故障" ;
VAL_ 2419392544 RPDU4_B3_SSPC_TripSta_08 1 "短路跳闸" 2 "过流跳闸" 0 "正常" 3 "无定义" ;
VAL_ 2419392544 RPDU4_B3_SSPC_BitErr_08 1 "故障" 0 "正常" ;
VAL_ 2419392544 RPDU4_B3_SSPC_OnOffSta_08 1 "接通" 0 "断开" ;
VAL_ 2419392544 RPDU4_B3_SSPC_DianHuErr_08 1 "有故障" 0 "无故障" ;
VAL_ 2419392544 RPDU4_B3_SSPC_TripSta_07 1 "短路跳闸" 2 "过流跳闸" 0 "正常" 3 "无定义" ;
VAL_ 2419392544 RPDU4_B3_SSPC_BitErr_07 1 "故障" 0 "正常" ;
VAL_ 2419392544 RPDU4_B3_SSPC_OnOffSta_07 1 "接通" 0 "断开" ;
VAL_ 2419392544 RPDU4_B3_SSPC_DianHuErr_07 1 "有故障" 0 "无故障" ;
VAL_ 2419392544 RPDU4_B3_SSPC_TripSta_06 1 "短路跳闸" 2 "过流跳闸" 0 "正常" 3 "无定义" ;
VAL_ 2419392544 RPDU4_B3_SSPC_BitErr_06 1 "故障" 0 "正常" ;
VAL_ 2419392544 RPDU4_B3_SSPC_OnOffSta_06 1 "接通" 0 "断开" ;
VAL_ 2419392544 RPDU4_B3_SSPC_DianHuErr_06 1 "有故障" 0 "无故障" ;
VAL_ 2419392544 RPDU4_B3_SSPC_TripSta_05 1 "短路跳闸" 2 "过流跳闸" 0 "正常" 3 "无定义" ;
VAL_ 2419392544 RPDU4_B3_SSPC_BitErr_05 1 "故障" 0 "正常" ;
VAL_ 2419392544 RPDU4_B3_SSPC_OnOffSta_05 1 "接通" 0 "断开" ;
VAL_ 2419392544 RPDU4_B3_SSPC_DianHuErr_05 1 "有故障" 0 "无故障" ;
VAL_ 2419327008 RPDU4_B3_SSPC_TripSta_04 1 "短路跳闸" 2 "过流跳闸" 0 "正常" 3 "无定义" ;
VAL_ 2419327008 RPDU4_B3_SSPC_BitErr_04 1 "故障" 0 "正常" ;
VAL_ 2419327008 RPDU4_B3_SSPC_OnOffSta_04 1 "接通" 0 "断开" ;
VAL_ 2419327008 RPDU4_B3_SSPC_DianHuErr_04 1 "有故障" 0 "无故障" ;
VAL_ 2419327008 RPDU4_B3_SSPC_TripSta_03 1 "短路跳闸" 2 "过流跳闸" 0 "正常" 3 "无定义" ;
VAL_ 2419327008 RPDU4_B3_SSPC_BitErr_03 1 "故障" 0 "正常" ;
VAL_ 2419327008 RPDU4_B3_SSPC_OnOffSta_03 1 "接通" 0 "断开" ;
VAL_ 2419327008 RPDU4_B3_SSPC_DianHuErr_03 1 "有故障" 0 "无故障" ;
VAL_ 2419327008 RPDU4_B3_SSPC_TripSta_02 1 "短路跳闸" 2 "过流跳闸" 0 "正常" 3 "无定义" ;
VAL_ 2419327008 RPDU4_B3_SSPC_BitErr_02 1 "故障" 0 "正常" ;
VAL_ 2419327008 RPDU4_B3_SSPC_OnOffSta_02 1 "接通" 0 "断开" ;
VAL_ 2419327008 RPDU4_B3_SSPC_DianHuErr_02 1 "有故障" 0 "无故障" ;
VAL_ 2419327008 RPDU4_B3_SSPC_TripSta_01 1 "短路跳闸" 2 "过流跳闸" 0 "正常" 3 "无定义" ;
VAL_ 2419327008 RPDU4_B3_SSPC_BitErr_01 1 "故障" 0 "正常" ;
VAL_ 2419327008 RPDU4_B3_SSPC_OnOffSta_01 1 "接通" 0 "断开" ;
VAL_ 2419327008 RPDU4_B3_SSPC_DianHuErr_01 1 "有故障" 0 "无故障" ;
VAL_ 2419261472 RPDU4_B2_SSPC_TripSta_18 1 "短路跳闸" 2 "过流跳闸" 0 "正常" 3 "无定义" ;
VAL_ 2419261472 RPDU4_B2_SSPC_BitErr_18 1 "故障" 0 "正常" ;
VAL_ 2419261472 RPDU4_B2_SSPC_OnOffSta_18 1 "接通" 0 "断开" ;
VAL_ 2419261472 RPDU4_B2_SSPC_DianHuErr_18 1 "有故障" 0 "无故障" ;
VAL_ 2419261472 RPDU4_B2_SSPC_TripSta_17 1 "短路跳闸" 2 "过流跳闸" 0 "正常" 3 "无定义" ;
VAL_ 2419261472 RPDU4_B2_SSPC_BitErr_17 1 "故障" 0 "正常" ;
VAL_ 2419261472 RPDU4_B2_SSPC_OnOffSta_17 1 "接通" 0 "断开" ;
VAL_ 2419261472 RPDU4_B2_SSPC_DianHuErr_17 1 "有故障" 0 "无故障" ;
VAL_ 2419195936 RPDU4_B2_SSPC_TripSta_16 1 "短路跳闸" 2 "过流跳闸" 0 "正常" 3 "无定义" ;
VAL_ 2419195936 RPDU4_B2_SSPC_BitErr_16 1 "故障" 0 "正常" ;
VAL_ 2419195936 RPDU4_B2_SSPC_OnOffSta_16 1 "接通" 0 "断开" ;
VAL_ 2419195936 RPDU4_B2_SSPC_DianHuErr_16 1 "有故障" 0 "无故障" ;
VAL_ 2419195936 RPDU4_B2_SSPC_TripSta_15 1 "短路跳闸" 2 "过流跳闸" 0 "正常" 3 "无定义" ;
VAL_ 2419195936 RPDU4_B2_SSPC_BitErr_15 1 "故障" 0 "正常" ;
VAL_ 2419195936 RPDU4_B2_SSPC_OnOffSta_15 1 "接通" 0 "断开" ;
VAL_ 2419195936 RPDU4_B2_SSPC_DianHuErr_15 1 "有故障" 0 "无故障" ;
VAL_ 2419195936 RPDU4_B2_SSPC_TripSta_14 1 "短路跳闸" 2 "过流跳闸" 0 "正常" 3 "无定义" ;
VAL_ 2419195936 RPDU4_B2_SSPC_BitErr_14 1 "故障" 0 "正常" ;
VAL_ 2419195936 RPDU4_B2_SSPC_OnOffSta_14 1 "接通" 0 "断开" ;
VAL_ 2419195936 RPDU4_B2_SSPC_DianHuErr_14 1 "有故障" 0 "无故障" ;
VAL_ 2419195936 RPDU4_B2_SSPC_TripSta_13 1 "短路跳闸" 2 "过流跳闸" 0 "正常" 3 "无定义" ;
VAL_ 2419195936 RPDU4_B2_SSPC_BitErr_13 1 "故障" 0 "正常" ;
VAL_ 2419195936 RPDU4_B2_SSPC_OnOffSta_13 1 "接通" 0 "断开" ;
VAL_ 2419195936 RPDU4_B2_SSPC_DianHuErr_13 1 "有故障" 0 "无故障" ;
VAL_ 2419130400 RPDU4_B2_SSPC_TripSta_12 1 "短路跳闸" 2 "过流跳闸" 0 "正常" 3 "无定义" ;
VAL_ 2419130400 RPDU4_B2_SSPC_BitErr_12 1 "故障" 0 "正常" ;
VAL_ 2419130400 RPDU4_B2_SSPC_OnOffSta_12 1 "接通" 0 "断开" ;
VAL_ 2419130400 RPDU4_B2_SSPC_DianHuErr_12 1 "有故障" 0 "无故障" ;
VAL_ 2419130400 RPDU4_B2_SSPC_TripSta_11 1 "短路跳闸" 2 "过流跳闸" 0 "正常" 3 "无定义" ;
VAL_ 2419130400 RPDU4_B2_SSPC_BitErr_11 1 "故障" 0 "正常" ;
VAL_ 2419130400 RPDU4_B2_SSPC_OnOffSta_11 1 "接通" 0 "断开" ;
VAL_ 2419130400 RPDU4_B2_SSPC_DianHuErr_11 1 "有故障" 0 "无故障" ;
VAL_ 2419130400 RPDU4_B2_SSPC_TripSta_10 1 "短路跳闸" 2 "过流跳闸" 0 "正常" 3 "无定义" ;
VAL_ 2419130400 RPDU4_B2_SSPC_BitErr_10 1 "故障" 0 "正常" ;
VAL_ 2419130400 RPDU4_B2_SSPC_OnOffSta_10 1 "接通" 0 "断开" ;
VAL_ 2419130400 RPDU4_B2_SSPC_DianHuErr_10 1 "有故障" 0 "无故障" ;
VAL_ 2419130400 RPDU4_B2_SSPC_TripSta_09 1 "短路跳闸" 2 "过流跳闸" 0 "正常" 3 "无定义" ;
VAL_ 2419130400 RPDU4_B2_SSPC_BitErr_09 1 "故障" 0 "正常" ;
VAL_ 2419130400 RPDU4_B2_SSPC_OnOffSta_09 1 "接通" 0 "断开" ;
VAL_ 2419130400 RPDU4_B2_SSPC_DianHuErr_09 1 "有故障" 0 "无故障" ;
VAL_ 2419064864 RPDU4_B2_SSPC_TripSta_08 1 "短路跳闸" 2 "过流跳闸" 0 "正常" 3 "无定义" ;
VAL_ 2419064864 RPDU4_B2_SSPC_BitErr_08 1 "故障" 0 "正常" ;
VAL_ 2419064864 RPDU4_B2_SSPC_OnOffSta_08 1 "接通" 0 "断开" ;
VAL_ 2419064864 RPDU4_B2_SSPC_DianHuErr_08 1 "有故障" 0 "无故障" ;
VAL_ 2419064864 RPDU4_B2_SSPC_TripSta_07 1 "短路跳闸" 2 "过流跳闸" 0 "正常" 3 "无定义" ;
VAL_ 2419064864 RPDU4_B2_SSPC_BitErr_07 1 "故障" 0 "正常" ;
VAL_ 2419064864 RPDU4_B2_SSPC_OnOffSta_07 1 "接通" 0 "断开" ;
VAL_ 2419064864 RPDU4_B2_SSPC_DianHuErr_07 1 "有故障" 0 "无故障" ;
VAL_ 2419064864 RPDU4_B2_SSPC_TripSta_06 1 "短路跳闸" 2 "过流跳闸" 0 "正常" 3 "无定义" ;
VAL_ 2419064864 RPDU4_B2_SSPC_BitErr_06 1 "故障" 0 "正常" ;
VAL_ 2419064864 RPDU4_B2_SSPC_OnOffSta_06 1 "接通" 0 "断开" ;
VAL_ 2419064864 RPDU4_B2_SSPC_DianHuErr_06 1 "有故障" 0 "无故障" ;
VAL_ 2419064864 RPDU4_B2_SSPC_TripSta_05 1 "短路跳闸" 2 "过流跳闸" 0 "正常" 3 "无定义" ;
VAL_ 2419064864 RPDU4_B2_SSPC_BitErr_05 1 "故障" 0 "正常" ;
VAL_ 2419064864 RPDU4_B2_SSPC_OnOffSta_05 1 "接通" 0 "断开" ;
VAL_ 2419064864 RPDU4_B2_SSPC_DianHuErr_05 1 "有故障" 0 "无故障" ;
VAL_ 2418999328 RPDU4_B2_SSPC_TripSta_04 1 "短路跳闸" 2 "过流跳闸" 0 "正常" 3 "无定义" ;
VAL_ 2418999328 RPDU4_B2_SSPC_BitErr_04 1 "故障" 0 "正常" ;
VAL_ 2418999328 RPDU4_B2_SSPC_OnOffSta_04 1 "接通" 0 "断开" ;
VAL_ 2418999328 RPDU4_B2_SSPC_DianHuErr_04 1 "有故障" 0 "无故障" ;
VAL_ 2418999328 RPDU4_B2_SSPC_TripSta_03 1 "短路跳闸" 2 "过流跳闸" 0 "正常" 3 "无定义" ;
VAL_ 2418999328 RPDU4_B2_SSPC_BitErr_03 1 "故障" 0 "正常" ;
VAL_ 2418999328 RPDU4_B2_SSPC_OnOffSta_03 1 "接通" 0 "断开" ;
VAL_ 2418999328 RPDU4_B2_SSPC_DianHuErr_03 1 "有故障" 0 "无故障" ;
VAL_ 2418999328 RPDU4_B2_SSPC_TripSta_02 1 "短路跳闸" 2 "过流跳闸" 0 "正常" 3 "无定义" ;
VAL_ 2418999328 RPDU4_B2_SSPC_BitErr_02 1 "故障" 0 "正常" ;
VAL_ 2418999328 RPDU4_B2_SSPC_OnOffSta_02 1 "接通" 0 "断开" ;
VAL_ 2418999328 RPDU4_B2_SSPC_DianHuErr_02 1 "有故障" 0 "无故障" ;
VAL_ 2418999328 RPDU4_B2_SSPC_TripSta_01 1 "短路跳闸" 2 "过流跳闸" 0 "正常" 3 "无定义" ;
VAL_ 2418999328 RPDU4_B2_SSPC_BitErr_01 1 "故障" 0 "正常" ;
VAL_ 2418999328 RPDU4_B2_SSPC_OnOffSta_01 1 "接通" 0 "断开" ;
VAL_ 2418999328 RPDU4_B2_SSPC_DianHuErr_01 1 "有故障" 0 "无故障" ;
